VERSION "HNNBNNNYNNNNNNNNNNNNNNNNNNNNNNNNNNNNNNNNNN/4/%%%/4/'%**4NNN///"

NS_ :

BS_:

BU_: BAP_Tester BedienDisp_vo BedienSG_hi CGS DDA Gateway Gateway_PAG GurtMikrofon OTA_FC ZR_High ZR_LIMU ZR_MIB_TOP_ab_Gen3 ZR_Standard

BO_ 982 Licht_hinten_01: 8 Gateway
 SG_ BCM2_Bremsl_durch_ECD : 5|1@1+ (1.0,0.0) [0.0|1] ""  ZR_High
 SG_ LH_Aussenlicht_def : 7|1@1+ (1.0,0.0) [0.0|1] ""  ZR_High
 SG_ LH_Standlicht_H_aktiv : 8|1@1+ (1.0,0.0) [0.0|1] ""  ZR_High
 SG_ LH_Parklicht_HL_aktiv : 9|1@1+ (1.0,0.0) [0.0|1] ""  ZR_High
 SG_ LH_Parklicht_HR_aktiv : 10|1@1+ (1.0,0.0) [0.0|1] ""  ZR_High
 SG_ LH_Bremslicht_H_aktiv : 11|1@1+ (1.0,0.0) [0.0|1] ""  ZR_High
 SG_ LH_Nebelschluss_aktiv : 12|1@1+ (1.0,0.0) [0.0|1] ""  ZR_High
 SG_ LH_Rueckfahrlicht_aktiv : 13|1@1+ (1.0,0.0) [0.0|1] ""  ZR_High
 SG_ LH_Blinker_HL_akt : 14|1@1+ (1.0,0.0) [0.0|1] ""  ZR_High
 SG_ LH_Blinker_HR_akt : 15|1@1+ (1.0,0.0) [0.0|1] ""  ZR_High
 SG_ LH_Blinker_li_def : 16|1@1+ (1.0,0.0) [0.0|1] ""  ZR_High
 SG_ LH_Bremsl_li_def : 17|1@1+ (1.0,0.0) [0.0|1] ""  ZR_High
 SG_ LH_Schlusslicht_li_def : 18|1@1+ (1.0,0.0) [0.0|1] ""  ZR_High
 SG_ LH_Rueckf_li_def : 19|1@1+ (1.0,0.0) [0.0|1] ""  ZR_High
 SG_ LH_Nebel_li_def : 20|1@1+ (1.0,0.0) [0.0|1] ""  ZR_High
 SG_ LH_Schluss_Brems_Nebel_li_def : 21|1@1+ (1.0,0.0) [0.0|1] ""  ZR_High
 SG_ LH_Schluss_Brems_Nebel_re_def : 22|1@1+ (1.0,0.0) [0.0|1] ""  ZR_High
 SG_ LH_Zusatzschlussl_def : 23|1@1+ (1.0,0.0) [0.0|1] ""  Vector__XXX
 SG_ LH_Schluss_Brems_li_def : 24|1@1+ (1.0,0.0) [0.0|1] ""  ZR_High
 SG_ LH_Schluss_Nebel_li_def : 25|1@1+ (1.0,0.0) [0.0|1] ""  ZR_High
 SG_ LH_SL_BRL_BLK_li_def : 26|1@1+ (1.0,0.0) [0.0|1] ""  ZR_High
 SG_ LH_Brems_Blk_li_def : 27|1@1+ (1.0,0.0) [0.0|1] ""  Vector__XXX
 SG_ LH_Diag_Status_re_def : 28|1@1+ (1.0,0.0) [0.0|1] ""  ZR_High
 SG_ LH_Diag_Status_li_def : 29|1@1+ (1.0,0.0) [0.0|1] ""  ZR_High
 SG_ LH_Diag_LED_li_def : 30|1@1+ (1.0,0.0) [0.0|1] ""  ZR_High
 SG_ LH_Diag_LED_re_def : 31|1@1+ (1.0,0.0) [0.0|1] ""  ZR_High
 SG_ LH_Blinker_re_def : 32|1@1+ (1.0,0.0) [0.0|1] ""  ZR_High
 SG_ LH_Bremsl_re_def : 33|1@1+ (1.0,0.0) [0.0|1] ""  ZR_High
 SG_ LH_Schlusslicht_re_def : 34|1@1+ (1.0,0.0) [0.0|1] ""  ZR_High
 SG_ LH_Rueckf_re_def : 35|1@1+ (1.0,0.0) [0.0|1] ""  ZR_High
 SG_ LH_Nebel_re_def : 36|1@1+ (1.0,0.0) [0.0|1] ""  ZR_High
 SG_ LH_Schluss_Brems_mi_def : 37|1@1+ (1.0,0.0) [0.0|1] ""  Vector__XXX
 SG_ LH_Schluss_Brems_re_def : 40|1@1+ (1.0,0.0) [0.0|1] ""  ZR_High
 SG_ LH_Schluss_Nebel_re_def : 41|1@1+ (1.0,0.0) [0.0|1] ""  ZR_High
 SG_ LH_SL_BRL_BLK_re_def : 42|1@1+ (1.0,0.0) [0.0|1] ""  ZR_High
 SG_ LH_Brems_Blk_re_def : 43|1@1+ (1.0,0.0) [0.0|1] ""  ZR_High
 SG_ LH_Kennzl_def : 48|1@1+ (1.0,0.0) [0.0|1] ""  ZR_High
 SG_ LH_3_Bremsl_def : 49|1@1+ (1.0,0.0) [0.0|1] ""  ZR_High
 SG_ LH_Nebel_mi_def : 50|1@1+ (1.0,0.0) [0.0|1] ""  ZR_High
 SG_ LH_Rueckf_mi_def : 51|1@1+ (1.0,0.0) [0.0|1] ""  ZR_High
 SG_ LH_Schlusslicht_mi_def : 52|1@1+ (1.0,0.0) [0.0|1] ""  Vector__XXX
 SG_ LH_Bremsl_mi_def : 53|1@1+ (1.0,0.0) [0.0|1] ""  Vector__XXX
 SG_ LH_Bremsl_li_ges_def : 54|1@1+ (1.0,0.0) [0.0|1] ""  ZR_High
 SG_ LH_Bremsl_re_ges_def : 55|1@1+ (1.0,0.0) [0.0|1] ""  ZR_High

BO_ 1624 Licht_vorne_01: 8 Gateway
 SG_ Licht_Vorne_01_CRC : 0|8@1+ (1,0) [0|255] ""  Vector__XXX
 SG_ Licht_Vorne_01_BZ : 8|4@1+ (1,0) [0|15] ""  Vector__XXX
 SG_ LV_Standlicht_Anzeige : 12|1@1+ (1.0,0.0) [0.0|1] ""  BedienSG_hi,ZR_High
 SG_ LV_Abblendlicht_Anzeige : 13|1@1+ (1.0,0.0) [0.0|1] ""  OTA_FC,ZR_High
 SG_ LV_Fernlicht_Anzeige : 14|1@1+ (1.0,0.0) [0.0|1] ""  ZR_High
 SG_ LV_Nebellicht_Anzeige : 15|1@1+ (1.0,0.0) [0.0|1] ""  ZR_High
 SG_ LV_Nebelschlusslicht_Anzeige : 16|1@1+ (1.0,0.0) [0.0|1] ""  ZR_High
 SG_ LV_Tagfahrlicht_Anzeige : 17|1@1+ (1.0,0.0) [0.0|1] ""  BedienSG_hi,ZR_High
 SG_ LV_AFL_aktiv_Anzeige : 18|1@1+ (1.0,0.0) [0.0|1] ""  BedienSG_hi,ZR_High
 SG_ LV_AFL_defekt : 19|1@1+ (1.0,0.0) [0.0|1] ""  ZR_High
 SG_ LV_Blinker_li_def : 20|1@1+ (1.0,0.0) [0.0|1] ""  ZR_High
 SG_ LV_Standlicht_li_def : 21|1@1+ (1.0,0.0) [0.0|1] ""  ZR_High
 SG_ LV_Abblendlicht_li_def : 22|1@1+ (1.0,0.0) [0.0|1] ""  ZR_High
 SG_ LV_Fernlicht_li_def : 23|1@1+ (1.0,0.0) [0.0|1] ""  ZR_High
 SG_ LV_Nebellicht_li_def : 24|1@1+ (1.0,0.0) [0.0|1] ""  ZR_High
 SG_ LV_Blk_li_Seite_def : 25|1@1+ (1.0,0.0) [0.0|1] ""  ZR_High
 SG_ LV_Tagfahrlicht_li_def : 26|1@1+ (1.0,0.0) [0.0|1] ""  ZR_High
 SG_ LV_FLA_aktiv_Anzeige : 27|1@1+ (1.0,0.0) [0.0|1] ""  ZR_High
 SG_ LV_FLA_defekt : 28|1@1+ (1.0,0.0) [0.0|1] ""  ZR_High
 SG_ LV_FLA_Sensor_blockiert : 29|1@1+ (1.0,0.0) [0.0|1] ""  ZR_High
 SG_ LV_Blinker_re_def : 30|1@1+ (1.0,0.0) [0.0|1] ""  ZR_High
 SG_ LV_Standlicht_re_def : 31|1@1+ (1.0,0.0) [0.0|1] ""  ZR_High
 SG_ LV_Abblendlicht_re_def : 32|1@1+ (1.0,0.0) [0.0|1] ""  ZR_High
 SG_ LV_Fernlicht_re_def : 33|1@1+ (1.0,0.0) [0.0|1] ""  ZR_High
 SG_ LV_Nebellicht_re_def : 34|1@1+ (1.0,0.0) [0.0|1] ""  ZR_High
 SG_ LV_Blk_re_Seite_def : 35|1@1+ (1.0,0.0) [0.0|1] ""  ZR_High
 SG_ LV_Tagfahrlicht_re_def : 36|1@1+ (1.0,0.0) [0.0|1] ""  ZR_High
 SG_ LV_Aussenlicht_def : 37|1@1+ (1.0,0.0) [0.0|1] ""  ZR_High
 SG_ LV_Abblendlicht_TFL_li_def : 38|1@1+ (1.0,0.0) [0.0|1] ""  ZR_High
 SG_ LV_Nebellicht_TFL_li_def : 39|1@1+ (1.0,0.0) [0.0|1] ""  ZR_High
 SG_ LV_Standlicht_TFL_li_def : 40|1@1+ (1.0,0.0) [0.0|1] ""  ZR_High
 SG_ LV_Abblend_Fernlicht_li_def : 41|1@1+ (1.0,0.0) [0.0|1] ""  ZR_High
 SG_ LV_Abblendlicht_TFL_re_def : 42|1@1+ (1.0,0.0) [0.0|1] ""  ZR_High
 SG_ LV_Nebellicht_TFL_re_def : 43|1@1+ (1.0,0.0) [0.0|1] ""  ZR_High
 SG_ LV_Standlicht_TFL_re_def : 44|1@1+ (1.0,0.0) [0.0|1] ""  ZR_High
 SG_ LV_Abblend_Fernlicht_re_def : 45|1@1+ (1.0,0.0) [0.0|1] ""  ZR_High
 SG_ LV_Abbiegelicht_li_def : 46|1@1+ (1.0,0.0) [0.0|1] ""  Vector__XXX
 SG_ LV_Abbiegelicht_re_def : 47|1@1+ (1.0,0.0) [0.0|1] ""  Vector__XXX
 SG_ BCM1_Linksverkehr : 48|1@1+ (1.0,0.0) [0.0|1] ""  ZR_High
 SG_ BCM1_Licht_Dunkelheit_aktiv : 49|1@1+ (1.0,0.0) [0.0|1] ""  ZR_High
 SG_ LV_LED_Scheinwerfer_li_def : 50|1@1+ (1.0,0.0) [0.0|1] ""  Vector__XXX
 SG_ LV_LED_Scheinwerfer_re_def : 51|1@1+ (1.0,0.0) [0.0|1] ""  Vector__XXX
 SG_ LV_Blinker_VL_aktiv : 52|1@1+ (1.0,0.0) [0.0|1] ""  OTA_FC,ZR_High
 SG_ LV_Blinker_VR_aktiv : 53|1@1+ (1.0,0.0) [0.0|1] ""  OTA_FC,ZR_High
 SG_ LV_MXB_Status_Anzeige : 54|2@1+ (1.0,0.0) [0.0|3] ""  Vector__XXX

BO_ 1321 Lift_01: 8 Gateway
 SG_ Lift_Charisma_FahrPr : 15|3@1+ (1.0,0.0) [0.0|7] ""  Vector__XXX
 SG_ Lift_Charisma_Status : 18|2@1+ (1.0,0.0) [0.0|3] ""  Vector__XXX
 SG_ Lift_Charisma_Umschaltung : 20|2@1+ (1.0,0.0) [0.0|3] ""  Vector__XXX
 SG_ Lift_Anforderung_EFP : 22|2@1+ (1.0,0.0) [0.0|3] ""  Vector__XXX
 SG_ Lift_ESP_Zuschaltung : 24|1@1+ (1.0,0.0) [0.0|1] ""  Vector__XXX
 SG_ Lift_Meldung_12 : 40|1@1+ (1.0,0.0) [0.0|1] ""  Vector__XXX
 SG_ Lift_Meldung_13 : 41|1@1+ (1.0,0.0) [0.0|1] ""  Vector__XXX
 SG_ Lift_Meldung_14 : 42|1@1+ (1.0,0.0) [0.0|1] ""  Vector__XXX
 SG_ Lift_LED : 43|2@1+ (1.0,0.0) [0.0|3] ""  BedienDisp_vo
 SG_ Lift_Position : 45|3@1+ (1.0,0.0) [0.0|7] ""  Vector__XXX
 SG_ Lift_Meldung_01 : 48|1@1+ (1.0,0.0) [0.0|1] ""  Vector__XXX
 SG_ Lift_Meldung_02 : 49|1@1+ (1.0,0.0) [0.0|1] ""  Vector__XXX
 SG_ Lift_Meldung_03 : 50|1@1+ (1.0,0.0) [0.0|1] ""  Vector__XXX
 SG_ Lift_Meldung_04 : 51|1@1+ (1.0,0.0) [0.0|1] ""  Vector__XXX
 SG_ Lift_Meldung_05 : 52|1@1+ (1.0,0.0) [0.0|1] ""  Vector__XXX
 SG_ Lift_Meldung_06 : 53|1@1+ (1.0,0.0) [0.0|1] ""  Vector__XXX
 SG_ Lift_Meldung_07 : 54|1@1+ (1.0,0.0) [0.0|1] ""  Vector__XXX
 SG_ Lift_Meldung_08 : 55|1@1+ (1.0,0.0) [0.0|1] ""  Vector__XXX
 SG_ Lift_Meldung_09 : 56|1@1+ (1.0,0.0) [0.0|1] ""  Vector__XXX
 SG_ Lift_Meldung_10 : 57|1@1+ (1.0,0.0) [0.0|1] ""  Vector__XXX
 SG_ Lift_Meldung_11 : 58|1@1+ (1.0,0.0) [0.0|1] ""  Vector__XXX
 SG_ Lift_SpannungsAnf : 59|2@1+ (1.0,0.0) [0.0|3] ""  Vector__XXX
 SG_ Lift_StartStopp_Info : 61|2@1+ (1.0,0.0) [0.0|3] ""  Vector__XXX

BO_ 822 LR_HZG_01: 2 Gateway
 SG_ LR_HZG_Temp_Sensor : 0|8@1+ (1,-50) [-50|104] "Unit_DegreCelsi"  ZR_High
 SG_ LR_HZG_Taster_on_off : 8|1@1+ (1.0,0.0) [0.0|1] ""  ZR_High

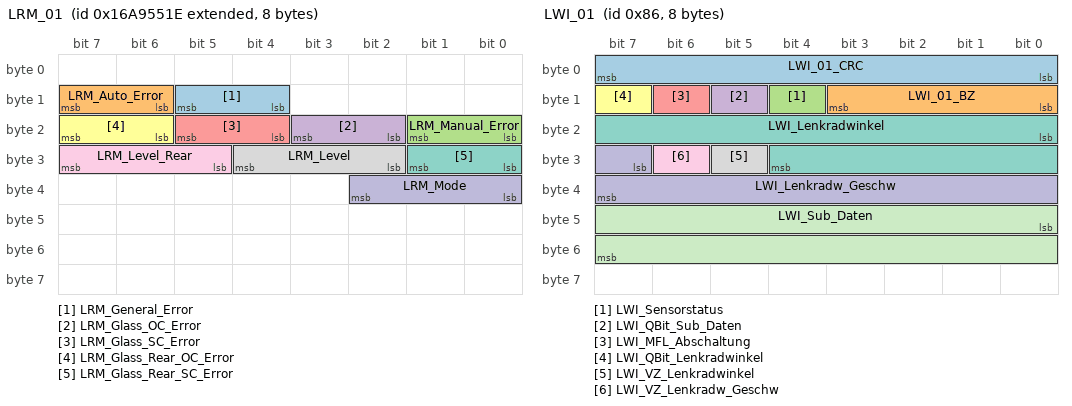
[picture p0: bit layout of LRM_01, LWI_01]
BO_ 2527679774 LRM_01: 8 Gateway
 SG_ LRM_General_Error : 12|2@1+ (1.0,0.0) [0.0|3] ""  ZR_LIMU
 SG_ LRM_Auto_Error : 14|2@1+ (1.0,0.0) [0.0|3] ""  ZR_LIMU
 SG_ LRM_Manual_Error : 16|2@1+ (1.0,0.0) [0.0|3] ""  ZR_LIMU
 SG_ LRM_Glass_OC_Error : 18|2@1+ (1.0,0.0) [0.0|3] ""  ZR_LIMU
 SG_ LRM_Glass_SC_Error : 20|2@1+ (1.0,0.0) [0.0|3] ""  ZR_LIMU
 SG_ LRM_Glass_Rear_OC_Error : 22|2@1+ (1.0,0.0) [0.0|3] ""  ZR_LIMU
 SG_ LRM_Glass_Rear_SC_Error : 24|2@1+ (1.0,0.0) [0.0|3] ""  ZR_LIMU
 SG_ LRM_Level : 26|3@1+ (1.0,0.0) [0.0|7] ""  ZR_LIMU
 SG_ LRM_Level_Rear : 29|3@1+ (1.0,0.0) [0.0|7] ""  ZR_LIMU
 SG_ LRM_Mode : 32|3@1+ (1.0,0.0) [0.0|7] ""  ZR_LIMU

BO_ 134 LWI_01: 8 Gateway
 SG_ LWI_01_CRC : 0|8@1+ (1,0) [0|255] ""  Vector__XXX
 SG_ LWI_01_BZ : 8|4@1+ (1,0) [0|15] ""  Vector__XXX
 SG_ LWI_Sensorstatus : 12|1@1+ (1.0,0.0) [0.0|1] ""  ZR_High,ZR_LIMU,ZR_MIB_TOP_ab_Gen3,ZR_Standard
 SG_ LWI_QBit_Sub_Daten : 13|1@1+ (1.0,0.0) [0.0|1] ""  ZR_High
 SG_ LWI_MFL_Abschaltung : 14|1@1+ (1.0,0.0) [0.0|1] ""  ZR_High
 SG_ LWI_QBit_Lenkradwinkel : 15|1@1+ (1.0,0.0) [0.0|1] ""  ZR_High,ZR_LIMU,ZR_MIB_TOP_ab_Gen3,ZR_Standard
 SG_ LWI_Lenkradwinkel : 16|13@1+ (0.1,0) [0.0|800.0] "Unit_DegreOfArc"  OTA_FC,ZR_High,ZR_LIMU,ZR_MIB_TOP_ab_Gen3,ZR_Standard
 SG_ LWI_VZ_Lenkradwinkel : 29|1@1+ (1.0,0.0) [0.0|1] ""  OTA_FC,ZR_High,ZR_LIMU,ZR_MIB_TOP_ab_Gen3,ZR_Standard
 SG_ LWI_VZ_Lenkradw_Geschw : 30|1@1+ (1.0,0.0) [0.0|1] ""  ZR_High
 SG_ LWI_Lenkradw_Geschw : 31|9@1+ (5,0) [0|2500] "Unit_DegreOfArcPerSecon"  OTA_FC,ZR_High
 SG_ LWI_Sub_Daten : 40|16@1+ (1,0) [0|65535] ""  Vector__XXX

BO_ 917 LWR_AFS_01: 8 Gateway
 SG_ AFS_Abbiegelicht_li_Anf : 0|1@1+ (1.0,0.0) [0.0|1] ""  ZR_High
 SG_ AFS_Abbiegelicht_re_Anf : 1|1@1+ (1.0,0.0) [0.0|1] ""  ZR_High
 SG_ AFS_Abbiegelicht_Dimm_Anf : 2|1@1+ (1.0,0.0) [0.0|1] ""  ZR_High
 SG_ AFS_Verfuegbarkeit_GLW : 3|1@1+ (1.0,0.0) [0.0|1] ""  ZR_High
 SG_ AFS_Status_adaptive_LV : 4|1@1+ (1.0,0.0) [0.0|1] ""  ZR_High
 SG_ AFS_Fernlicht_li_defekt : 5|1@1+ (1.0,0.0) [0.0|1] ""  ZR_High
 SG_ AFS_Fernlicht_re_defekt : 6|1@1+ (1.0,0.0) [0.0|1] ""  ZR_High
 SG_ AFS_Fernlicht_Status : 7|1@1+ (1.0,0.0) [0.0|1] ""  ZR_High
 SG_ LWR_AFS_01_BZ : 8|4@1+ (1,0) [0|15] ""  Vector__XXX
 SG_ AFS_Lampe : 12|1@1+ (1.0,0.0) [0.0|1] ""  ZR_High
 SG_ LWR_Lampe : 13|1@1+ (1.0,0.0) [0.0|1] ""  ZR_High
 SG_ AFS_Fehlertext : 14|1@1+ (1.0,0.0) [0.0|1] ""  ZR_High
 SG_ AFS_LED_Blinkmode : 15|1@1+ (1.0,0.0) [0.0|1] ""  Vector__XXX
 SG_ LWR_Touristenmodus_aktiv : 16|1@1+ (1.0,0.0) [0.0|1] ""  ZR_High
 SG_ AFS_Charisma_FahrPr : 17|4@1+ (1.0,0.0) [0.0|15] ""  Vector__XXX
 SG_ AFS_Charisma_Status : 21|2@1+ (1.0,0.0) [0.0|3] ""  Vector__XXX
 SG_ LWR_Sicherheitsposition_re : 23|1@1+ (1.0,0.0) [0.0|1] ""  ZR_High
 SG_ AFS_Allwetterlicht : 24|1@1+ (1.0,0.0) [0.0|1] ""  ZR_High
 SG_ LWR_Touristenmodus_verbaut : 25|1@1+ (1.0,0.0) [0.0|1] ""  ZR_High
 SG_ AFS_adaptive_LV_verbaut : 26|1@1+ (1.0,0.0) [0.0|1] ""  ZR_High
 SG_ LWR_Reisemodus_Texte : 27|2@1+ (1.0,0.0) [0.0|3] ""  ZR_High
 SG_ GLW_Sensor_blockiert : 29|1@1+ (1.0,0.0) [0.0|1] ""  ZR_High
 SG_ AFS_Charisma_Umschaltung : 30|2@1+ (1.0,0.0) [0.0|3] ""  Vector__XXX
 SG_ LWR_Pos_Schrittmotor : 32|8@1+ (0.4,0) [0.0|100.0] "Unit_PerCent"  Vector__XXX
 SG_ LWR_Hoehenwert_VL : 40|8@1+ (1,-127) [-127|126] ""  ZR_High
 SG_ LWR_Hoehenwert_HL : 48|8@1+ (1,-127) [-127|126] ""  ZR_High
 SG_ AFS_Ersatzlicht_Links : 56|1@1+ (1.0,0.0) [0.0|1] ""  ZR_High
 SG_ AFS_Ersatzlicht_Rechts : 57|1@1+ (1.0,0.0) [0.0|1] ""  ZR_High
 SG_ LWR_AFS_Grundeinstellung : 58|1@1+ (1.0,0.0) [0.0|1] ""  ZR_High
 SG_ LWR_AFS_Parametrisierung : 59|1@1+ (1.0,0.0) [0.0|1] ""  ZR_High
 SG_ LWR_Initialisierungslauf : 60|1@1+ (1.0,0.0) [0.0|1] ""  ZR_High
 SG_ LWR_Sicherheitsposition_li : 61|1@1+ (1.0,0.0) [0.0|1] ""  ZR_High
 SG_ LWR_Modus : 62|1@1+ (1.0,0.0) [0.0|1] ""  ZR_High

BO_ 1153 MainUnit_01: 8 ZR_High
 SG_ ZR_LoGeWa_Event_Kombiwarnung : 0|4@1+ (1.0,0.0) [0.0|15] ""  Gateway,Gateway_PAG
 SG_ Nav_FoD_Status : 4|3@1+ (1.0,0.0) [0.0|7] ""  Gateway,Gateway_PAG
 SG_ MIB_Tongenerator_PH_verfuegbar : 9|3@1+ (1.0,0.0) [0.0|7] ""  Gateway,Gateway_PAG
 SG_ MMI_Counter_Bedienevent : 12|4@1+ (1.0,0.0) [0.0|15] ""  Gateway,Gateway_PAG
 SG_ DSSS_Warning : 16|5@1+ (1.0,0.0) [0.0|31] ""  Gateway,Gateway_PAG
 SG_ ZR_Kindersicherung_RSE : 21|1@1+ (1.0,0.0) [0.0|1] ""  Gateway,Gateway_PAG
 SG_ ZR_RSE_aktivieren : 22|1@1+ (1.0,0.0) [0.0|1] ""  Gateway,Gateway_PAG
 SG_ MMI_SDS_aktiv : 23|1@1+ (1.0,0.0) [0.0|1] ""  Gateway,Gateway_PAG
 SG_ MU_SecondDisplay : 24|3@1+ (1.0,0.0) [0.0|7] ""  Gateway,Gateway_PAG
 SG_ MMI_Telefon_aktiv : 27|1@1+ (1.0,0.0) [0.0|1] ""  Gateway,Gateway_PAG
 SG_ MMI_Gurt_Mic_ref : 28|1@1+ (1.0,0.0) [0.0|1] ""  Gateway,Gateway_PAG,GurtMikrofon
 SG_ ZR_Sta_Inszenierung : 29|2@1+ (1.0,0.0) [0.0|3] ""  Gateway,Gateway_PAG
 SG_ MMI_Gauges_active : 31|1@1+ (1.0,0.0) [0.0|1] ""  BedienDisp_vo,Gateway,Gateway_PAG
 SG_ MU_Update_Time : 32|8@1+ (0.1,0) [0.0|25.5] "Unit_Hours"  Gateway,Gateway_PAG
 SG_ ZR_MXB_Manoever_Ansage : 42|2@1+ (1.0,0.0) [0.0|3] ""  Gateway,Gateway_PAG
 SG_ ZR_LAPP_Sondermodus_Status : 44|2@1+ (1.0,0.0) [0.0|3] ""  DDA,Gateway,Gateway_PAG
 SG_ MMI_StartStopp_Info : 46|2@1+ (1.0,0.0) [0.0|3] ""  Gateway,Gateway_PAG
 SG_ ZR_Parken_Sondermodus : 48|4@1+ (1.0,0.0) [0.0|15] ""  DDA,Gateway,Gateway_PAG
 SG_ ZR_Rundenbewertung : 52|4@1+ (1.0,0.0) [0.0|15] ""  Gateway,Gateway_PAG
 SG_ ZR_Rundenfortschritt : 56|8@1+ (0.5,0) [0.0|100.0] "Unit_PerCent"  Gateway,Gateway_PAG

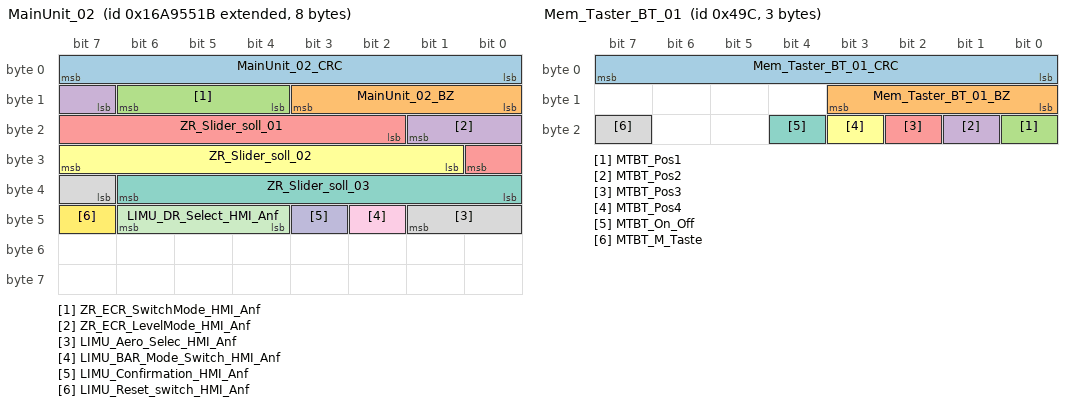
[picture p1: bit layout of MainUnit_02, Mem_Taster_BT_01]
BO_ 2527679771 MainUnit_02: 8 ZR_LIMU
 SG_ MainUnit_02_CRC : 0|8@1+ (1,0) [0|255] ""  Gateway,Gateway_PAG
 SG_ MainUnit_02_BZ : 8|4@1+ (1,0) [0|15] ""  Gateway,Gateway_PAG
 SG_ ZR_ECR_SwitchMode_HMI_Anf : 12|3@1+ (1.0,0.0) [0.0|7] ""  Gateway,Gateway_PAG
 SG_ ZR_ECR_LevelMode_HMI_Anf : 15|3@1+ (1.0,0.0) [0.0|7] ""  Gateway,Gateway_PAG
 SG_ ZR_Slider_soll_01 : 18|7@1+ (0.01,0) [0.00|1.26] "Unit_None"  Gateway,Gateway_PAG
 SG_ ZR_Slider_soll_02 : 25|7@1+ (0.01,0) [0.00|1.26] "Unit_None"  Gateway,Gateway_PAG
 SG_ ZR_Slider_soll_03 : 32|7@1+ (0.01,0) [0.00|1.26] "Unit_None"  Gateway,Gateway_PAG
 SG_ LIMU_Aero_Selec_HMI_Anf : 39|3@1+ (1.0,0.0) [0.0|7] ""  Gateway,Gateway_PAG
 SG_ LIMU_BAR_Mode_Switch_HMI_Anf : 42|1@1+ (1.0,0.0) [0.0|1] ""  Gateway,Gateway_PAG
 SG_ LIMU_Confirmation_HMI_Anf : 43|1@1+ (1.0,0.0) [0.0|1] ""  Gateway,Gateway_PAG
 SG_ LIMU_DR_Select_HMI_Anf : 44|3@1+ (1.0,0.0) [0.0|7] ""  Gateway,Gateway_PAG
 SG_ LIMU_Reset_switch_HMI_Anf : 47|1@1+ (1.0,0.0) [0.0|1] ""  Gateway,Gateway_PAG

BO_ 1639 Mem_BFS_01: 8 Gateway
 SG_ BFS_Fond_Bed_Ack : 12|1@1+ (1.0,0.0) [0.0|1] ""  ZR_High
 SG_ BFS_Lehne_nicht_verriegelt : 13|1@1+ (1.0,0.0) [0.0|1] ""  Vector__XXX
 SG_ BFS_Klapptisch_offen : 14|1@1+ (1.0,0.0) [0.0|1] ""  ZR_High
 SG_ BFS_Gurtbringer_Sperre : 15|1@1+ (1.0,0.0) [0.0|1] ""  ZR_High
 SG_ BFS_Sitzsym_Fahrt_aktiv : 16|1@1+ (1.0,0.0) [0.0|1] ""  ZR_High
 SG_ BFS_Sitzfahrt_aktiv : 17|1@1+ (1.0,0.0) [0.0|1] ""  ZR_High
 SG_ BFS_SLV_aktiv : 18|1@1+ (1.0,0.0) [0.0|1] ""  ZR_High
 SG_ BFS_SHV_aktiv : 19|1@1+ (1.0,0.0) [0.0|1] ""  ZR_High
 SG_ BFS_LNV_aktiv : 20|1@1+ (1.0,0.0) [0.0|1] ""  ZR_High
 SG_ BFS_SNV_aktiv : 21|1@1+ (1.0,0.0) [0.0|1] ""  ZR_High
 SG_ BFS_KSV_aktiv : 22|1@1+ (1.0,0.0) [0.0|1] ""  ZR_High
 SG_ BFS_LKV_aktiv : 23|1@1+ (1.0,0.0) [0.0|1] ""  ZR_High
 SG_ BFS_STV_aktiv : 24|1@1+ (1.0,0.0) [0.0|1] ""  ZR_High
 SG_ BFS_LHV_aktiv : 25|1@1+ (1.0,0.0) [0.0|1] ""  ZR_High
 SG_ BFS_LWV_aktiv : 26|1@1+ (1.0,0.0) [0.0|1] ""  ZR_High
 SG_ BFS_GHV_aktiv : 27|1@1+ (1.0,0.0) [0.0|1] ""  ZR_High
 SG_ BFS_KSS_Fahrt_aktiv : 28|1@1+ (1.0,0.0) [0.0|1] ""  ZR_High
 SG_ BFS_MMB_lokal_Stop : 29|1@1+ (1.0,0.0) [0.0|1] ""  ZR_High
 SG_ BFS_Ruhestellung_Status : 30|1@1+ (1.0,0.0) [0.0|1] ""  ZR_High
 SG_ BFS_Seat_Locked : 31|1@1+ (1.0,0.0) [0.0|1] ""  ZR_High
 SG_ BFS_MMB_storage : 32|4@1+ (1.0,0.0) [0.0|15] ""  ZR_High
 SG_ BFS_MMB_tipp : 36|1@1+ (1.0,0.0) [0.0|1] ""  ZR_High
 SG_ BFS_MMB_tast : 37|1@1+ (1.0,0.0) [0.0|1] ""  ZR_High
 SG_ BFS_MMB_store_LED_on : 38|1@1+ (1.0,0.0) [0.0|1] ""  ZR_High
 SG_ BFS_MMB_storage_beep : 39|1@1+ (1.0,0.0) [0.0|1] ""  ZR_High
 SG_ BFS_MMB_store : 40|1@1+ (1.0,0.0) [0.0|1] ""  ZR_High
 SG_ BFS_MMB_glob_stop : 41|1@1+ (1.0,0.0) [0.0|1] ""  ZR_High
 SG_ BFS_FSV_ausgeklappt : 42|1@1+ (1.0,0.0) [0.0|1] ""  ZR_High
 SG_ BFS_NFA_einfahren : 43|1@1+ (1.0,0.0) [0.0|1] ""  Vector__XXX
 SG_ BFS_Kollisionsbereich_Windschott : 44|1@1+ (1.0,0.0) [0.0|1] ""  Vector__XXX
 SG_ BFS_Kollisionsgefahr_Windschott : 45|1@1+ (1.0,0.0) [0.0|1] ""  Vector__XXX

BO_ 957 Mem_BFS_Fond_01: 8 Gateway
 SG_ Mem_BFSFo_Lordose_hoch : 12|1@1+ (1.0,0.0) [0.0|1] ""  ZR_High
 SG_ Mem_BFSFo_Lordose_runter : 13|1@1+ (1.0,0.0) [0.0|1] ""  ZR_High
 SG_ Mem_BFSFo_Lordose_vor : 14|1@1+ (1.0,0.0) [0.0|1] ""  ZR_High
 SG_ Mem_BFSFo_Lordose_zurueck : 15|1@1+ (1.0,0.0) [0.0|1] ""  ZR_High
 SG_ Mem_BFSFo_Massage_Geschw : 16|3@1+ (1.0,0.0) [0.0|7] ""  ZR_High
 SG_ Mem_BFSFo_Massage_Intens : 19|3@1+ (1.0,0.0) [0.0|7] ""  ZR_High
 SG_ Mem_BFSFo_MMB_storage : 22|2@1+ (1.0,0.0) [0.0|3] ""  ZR_High
 SG_ Mem_BFSFo_Massage_Prg : 24|3@1+ (1.0,0.0) [0.0|7] ""  ZR_High
 SG_ Mem_BFSFo_MMB_tast : 27|1@1+ (1.0,0.0) [0.0|1] ""  ZR_High
 SG_ Mem_BFSFo_MMB_tipp : 28|1@1+ (1.0,0.0) [0.0|1] ""  ZR_High
 SG_ Mem_BFSFo_MMB_glob_Stop : 29|1@1+ (1.0,0.0) [0.0|1] ""  ZR_High
 SG_ Mem_BFSFo_Sitztiefe_vor : 30|1@1+ (1.0,0.0) [0.0|1] ""  ZR_High
 SG_ Mem_BFSFo_Sitztiefe_zur : 31|1@1+ (1.0,0.0) [0.0|1] ""  ZR_High
 SG_ Mem_BFSFo_MMB_store : 32|1@1+ (1.0,0.0) [0.0|1] ""  ZR_High
 SG_ Mem_BFSFo_MMB_storage_beep : 33|1@1+ (1.0,0.0) [0.0|1] ""  Vector__XXX
 SG_ Mem_BFSFo_MMB_store_LED_on : 34|1@1+ (1.0,0.0) [0.0|1] ""  ZR_High
 SG_ Mem_BFSFo_BeifaSitzverstellung : 35|1@1+ (1.0,0.0) [0.0|1] ""  ZR_High
 SG_ Mem_BFSFo_MMB_lokal_Stop : 36|1@1+ (1.0,0.0) [0.0|1] ""  ZR_High
 SG_ Mem_BFSFo_Sitzfahrt_aktiv : 37|1@1+ (1.0,0.0) [0.0|1] ""  ZR_High
 SG_ Mem_BFSFo_BFS_Freigabe : 38|1@1+ (1.0,0.0) [0.0|1] ""  ZR_High
 SG_ Mem_BFS_Spezialpos_loeschen : 39|1@1+ (1.0,0.0) [0.0|1] ""  ZR_High
 SG_ Mem_BFSFo_RSE_zurueck : 40|1@1+ (1.0,0.0) [0.0|1] ""  ZR_High
 SG_ Mem_BFSFo_RSE_vor : 41|1@1+ (1.0,0.0) [0.0|1] ""  ZR_High
 SG_ Mem_BFSFo_Business_anfahren : 42|1@1+ (1.0,0.0) [0.0|1] ""  ZR_High
 SG_ Mem_BFSFo_Relax_anfahren : 43|1@1+ (1.0,0.0) [0.0|1] ""  ZR_High
 SG_ BFS_Kopfstuetze_vor : 44|1@1+ (1.0,0.0) [0.0|1] ""  ZR_High
 SG_ BFS_Kopfstuetze_zurueck : 45|1@1+ (1.0,0.0) [0.0|1] ""  ZR_High
 SG_ Mem_BFSFo_NFA_aufgestellt : 46|1@1+ (1.0,0.0) [0.0|1] ""  Vector__XXX
 SG_ Fernsteuerung_BFS_LED : 47|1@1+ (1.0,0.0) [0.0|1] ""  Vector__XXX
 SG_ Mem_BFSFo_BFS_RSE_Freigabe : 48|1@1+ (1.0,0.0) [0.0|1] ""  ZR_High
 SG_ Mem_BFSFo_Fusstuetze_runter : 49|1@1+ (1.0,0.0) [0.0|1] ""  ZR_High
 SG_ Mem_BFSFo_Fusstuetze_hoch : 50|1@1+ (1.0,0.0) [0.0|1] ""  ZR_High
 SG_ Fernsteuerung_Massage_LED : 51|1@1+ (1.0,0.0) [0.0|1] ""  Vector__XXX

BO_ 1178 Mem_FS_01: 8 Gateway
 SG_ FS_Fond_Bed_enable : 12|1@1+ (1.0,0.0) [0.0|1] ""  ZR_High
 SG_ FS_Lehne_nicht_verriegelt : 13|1@1+ (1.0,0.0) [0.0|1] ""  ZR_High
 SG_ FS_Spezialposition_anfahren : 14|1@1+ (1.0,0.0) [0.0|1] ""  ZR_High
 SG_ FS_Gurtbringer_Sperre : 15|1@1+ (1.0,0.0) [0.0|1] ""  ZR_High
 SG_ FS_BFS_Sitzsym_Anfahrt : 16|1@1+ (1.0,0.0) [0.0|1] ""  ZR_High
 SG_ FS_Sitzfahrt_aktiv : 17|1@1+ (1.0,0.0) [0.0|1] ""  ZR_High
 SG_ FS_SLV_aktiv : 18|1@1+ (1.0,0.0) [0.0|1] ""  ZR_High
 SG_ FS_SHV_aktiv : 19|1@1+ (1.0,0.0) [0.0|1] ""  ZR_High
 SG_ FS_LNV_aktiv : 20|1@1+ (1.0,0.0) [0.0|1] ""  ZR_High
 SG_ FS_SNV_aktiv : 21|1@1+ (1.0,0.0) [0.0|1] ""  ZR_High
 SG_ FS_KSV_aktiv : 22|1@1+ (1.0,0.0) [0.0|1] ""  ZR_High
 SG_ FS_LKV_aktiv : 23|1@1+ (1.0,0.0) [0.0|1] ""  ZR_High
 SG_ FS_STV_aktiv : 24|1@1+ (1.0,0.0) [0.0|1] ""  ZR_High
 SG_ FS_LHV_aktiv : 25|1@1+ (1.0,0.0) [0.0|1] ""  ZR_High
 SG_ FS_LWV_aktiv : 26|1@1+ (1.0,0.0) [0.0|1] ""  ZR_High
 SG_ FS_GHV_aktiv : 27|1@1+ (1.0,0.0) [0.0|1] ""  ZR_High
 SG_ FS_BFS_KSS_Anfahrt : 28|1@1+ (1.0,0.0) [0.0|1] ""  ZR_High
 SG_ FS_MMB_lokal_Stop : 29|1@1+ (1.0,0.0) [0.0|1] ""  ZR_High
 SG_ FS_NFA_einfahren : 30|1@1+ (1.0,0.0) [0.0|1] ""  Vector__XXX
 SG_ FS_Kollisionsbereich_Windschott : 31|1@1+ (1.0,0.0) [0.0|1] ""  Vector__XXX
 SG_ FS_MMB_storage : 32|4@1+ (1.0,0.0) [0.0|15] ""  ZR_High
 SG_ FS_MMB_tipp : 36|1@1+ (1.0,0.0) [0.0|1] ""  ZR_High
 SG_ FS_MMB_tast : 37|1@1+ (1.0,0.0) [0.0|1] ""  ZR_High
 SG_ FS_MMB_store_LED_on : 38|1@1+ (1.0,0.0) [0.0|1] ""  ZR_High
 SG_ FS_MMB_storage_beep : 39|1@1+ (1.0,0.0) [0.0|1] ""  Vector__XXX
 SG_ FS_MMB_store : 40|1@1+ (1.0,0.0) [0.0|1] ""  ZR_High
 SG_ FS_MMB_glob_stop : 41|1@1+ (1.0,0.0) [0.0|1] ""  ZR_High
 SG_ FS_EE_Fond_FS_enable : 42|1@1+ (1.0,0.0) [0.0|1] ""  ZR_High
 SG_ FS_EE_Fond_BFS_enable : 43|1@1+ (1.0,0.0) [0.0|1] ""  ZR_High
 SG_ FS_BFS_Fond_Verst_enable : 44|1@1+ (1.0,0.0) [0.0|1] ""  ZR_High
 SG_ FS_EE_BFS_enable : 45|1@1+ (1.0,0.0) [0.0|1] ""  ZR_High
 SG_ FS_Kollisionsgefahr_Windschott : 46|1@1+ (1.0,0.0) [0.0|1] ""  Vector__XXX

BO_ 954 Mem_FS_02: 8 Gateway
 SG_ Mem_FS_Lordose_hoch : 12|1@1+ (1.0,0.0) [0.0|1] ""  ZR_High
 SG_ Mem_FS_Lordose_runter : 13|1@1+ (1.0,0.0) [0.0|1] ""  ZR_High
 SG_ Mem_FS_Lordose_vor : 14|1@1+ (1.0,0.0) [0.0|1] ""  ZR_High
 SG_ Mem_FS_Lordose_zurueck : 15|1@1+ (1.0,0.0) [0.0|1] ""  ZR_High
 SG_ Mem_FS_Massage_Geschw : 16|3@1+ (1.0,0.0) [0.0|7] ""  ZR_High
 SG_ Mem_FS_Massage_Intensitaet : 19|3@1+ (1.0,0.0) [0.0|7] ""  ZR_High
 SG_ Mem_FS_SWangenLehne_beluef : 22|1@1+ (1.0,0.0) [0.0|1] ""  ZR_High
 SG_ Mem_FS_SWangenLehne_entlue : 23|1@1+ (1.0,0.0) [0.0|1] ""  ZR_High
 SG_ Mem_FS_Massage_Programm : 24|3@1+ (1.0,0.0) [0.0|7] ""  Vector__XXX
 SG_ Mem_FS_SWangenSitz_beluef : 27|1@1+ (1.0,0.0) [0.0|1] ""  ZR_High
 SG_ Mem_FS_SWangenSitz_entlue : 28|1@1+ (1.0,0.0) [0.0|1] ""  ZR_High
 SG_ FS_BFS_aufraeumen : 29|1@1+ (1.0,0.0) [0.0|1] ""  ZR_High
 SG_ FS_BFSFo_aufraeumen : 30|1@1+ (1.0,0.0) [0.0|1] ""  ZR_High
 SG_ FS_FSFo_aufraeumen : 31|1@1+ (1.0,0.0) [0.0|1] ""  ZR_High
 SG_ FS_Remote_Multif_Taster_hoch : 32|1@1+ (1.0,0.0) [0.0|1] ""  ZR_High
 SG_ FS_Remote_Multif_Taster_tief : 33|1@1+ (1.0,0.0) [0.0|1] ""  ZR_High
 SG_ FS_Remote_Multif_Taster_vor : 34|1@1+ (1.0,0.0) [0.0|1] ""  ZR_High
 SG_ FS_Remote_Multif_Taster_zurueck : 35|1@1+ (1.0,0.0) [0.0|1] ""  ZR_High
 SG_ FS_Remote_Programmwippe_hoch : 36|1@1+ (1.0,0.0) [0.0|1] ""  ZR_High
 SG_ FS_Remote_Programmwippe_tief : 37|1@1+ (1.0,0.0) [0.0|1] ""  ZR_High
 SG_ FS_Remote_SHV_Taste_hoch : 38|1@1+ (1.0,0.0) [0.0|1] ""  ZR_High
 SG_ FS_Remote_SHV_Taste_tief : 39|1@1+ (1.0,0.0) [0.0|1] ""  ZR_High
 SG_ FS_Remote_SLV_Taste_vor : 40|1@1+ (1.0,0.0) [0.0|1] ""  ZR_High
 SG_ FS_Remote_SLV_Taste_zurueck : 41|1@1+ (1.0,0.0) [0.0|1] ""  ZR_High
 SG_ FS_Remote_SNV_Taste_hoch : 42|1@1+ (1.0,0.0) [0.0|1] ""  ZR_High
 SG_ FS_Remote_SNV_Taste_tief : 43|1@1+ (1.0,0.0) [0.0|1] ""  ZR_High
 SG_ FS_Remote_KSV_Taste_hoch : 44|1@1+ (1.0,0.0) [0.0|1] ""  ZR_High
 SG_ FS_Remote_KSV_Taste_tief : 45|1@1+ (1.0,0.0) [0.0|1] ""  ZR_High
 SG_ FS_Remote_LNV_Taste_vor : 46|1@1+ (1.0,0.0) [0.0|1] ""  ZR_High
 SG_ FS_Remote_LNV_Taste_zurueck : 47|1@1+ (1.0,0.0) [0.0|1] ""  ZR_High
 SG_ FS_Remote_Massage_Taste : 48|1@1+ (1.0,0.0) [0.0|1] ""  ZR_High
 SG_ FS_RemoteTarget : 49|2@1+ (1.0,0.0) [0.0|3] ""  ZR_High
 SG_ FS_Remote_KSV_Taste_vor : 51|1@1+ (1.0,0.0) [0.0|1] ""  ZR_High
 SG_ FS_Remote_KSV_Taste_zurueck : 52|1@1+ (1.0,0.0) [0.0|1] ""  ZR_High
 SG_ FS_Remote_STV_Taste_vor : 53|1@1+ (1.0,0.0) [0.0|1] ""  ZR_High
 SG_ FS_Remote_STV_Taste_zurueck : 54|1@1+ (1.0,0.0) [0.0|1] ""  ZR_High
 SG_ FS_Remote_SWV_Taste_eng : 55|1@1+ (1.0,0.0) [0.0|1] ""  ZR_High
 SG_ FS_Remote_SWV_Taste_breit : 56|1@1+ (1.0,0.0) [0.0|1] ""  ZR_High
 SG_ FS_Remote_LWV_Taste_eng : 57|1@1+ (1.0,0.0) [0.0|1] ""  ZR_High
 SG_ FS_Remote_LWV_Taste_breit : 58|1@1+ (1.0,0.0) [0.0|1] ""  ZR_High
 SG_ FS_Remote_LKV_Taste_vor : 59|1@1+ (1.0,0.0) [0.0|1] ""  ZR_High
 SG_ FS_Remote_LKV_Taste_zurueck : 60|1@1+ (1.0,0.0) [0.0|1] ""  ZR_High
 SG_ FS_MMB_Sys_Fahrt_aktiv : 61|1@1+ (1.0,0.0) [0.0|1] ""  ZR_High

BO_ 956 Mem_FS_Fond_01: 8 Gateway
 SG_ Mem_FSFo_Lordose_hoch : 12|1@1+ (1.0,0.0) [0.0|1] ""  ZR_High
 SG_ Mem_FSFo_Lordose_runter : 13|1@1+ (1.0,0.0) [0.0|1] ""  ZR_High
 SG_ Mem_FSFo_Lordose_vor : 14|1@1+ (1.0,0.0) [0.0|1] ""  ZR_High
 SG_ Mem_FSFo_Lordose_zurueck : 15|1@1+ (1.0,0.0) [0.0|1] ""  ZR_High
 SG_ Mem_FSFo_Massage_Geschw : 16|3@1+ (1.0,0.0) [0.0|7] ""  ZR_High
 SG_ Mem_FSFo_Massage_Intens : 19|3@1+ (1.0,0.0) [0.0|7] ""  ZR_High
 SG_ Mem_FSFo_MMB_storage : 22|2@1+ (1.0,0.0) [0.0|3] ""  ZR_High
 SG_ Mem_FSFo_Massage_Prg : 24|3@1+ (1.0,0.0) [0.0|7] ""  ZR_High
 SG_ Mem_FSFo_MMB_tast : 27|1@1+ (1.0,0.0) [0.0|1] ""  ZR_High
 SG_ Mem_FSFo_MMB_tipp : 28|1@1+ (1.0,0.0) [0.0|1] ""  ZR_High
 SG_ Mem_FSFo_MMB_glob_Stop : 29|1@1+ (1.0,0.0) [0.0|1] ""  ZR_High
 SG_ Mem_FSFo_Sitztiefe_vor : 30|1@1+ (1.0,0.0) [0.0|1] ""  ZR_High
 SG_ Mem_FSFo_Sitztiefe_zur : 31|1@1+ (1.0,0.0) [0.0|1] ""  ZR_High
 SG_ Mem_FSFo_MMB_store : 32|1@1+ (1.0,0.0) [0.0|1] ""  ZR_High
 SG_ Mem_FSFo_MMB_storage_beep : 33|1@1+ (1.0,0.0) [0.0|1] ""  ZR_High
 SG_ Mem_FSFo_MMB_store_LED_on : 34|1@1+ (1.0,0.0) [0.0|1] ""  ZR_High
 SG_ Mem_FSFo_MMB_lokal_Stop : 36|1@1+ (1.0,0.0) [0.0|1] ""  ZR_High
 SG_ Mem_FSFo_Sitzfahrt_aktiv : 37|1@1+ (1.0,0.0) [0.0|1] ""  ZR_High
 SG_ Mem_FSFo_Business_anfahren : 42|1@1+ (1.0,0.0) [0.0|1] ""  ZR_High
 SG_ Mem_FSFo_Relax_anfahren : 43|1@1+ (1.0,0.0) [0.0|1] ""  ZR_High

BO_ 1180 Mem_Taster_BT_01: 3 Gateway
 SG_ Mem_Taster_BT_01_CRC : 0|8@1+ (1,0) [0|255] ""  Vector__XXX
 SG_ Mem_Taster_BT_01_BZ : 8|4@1+ (1,0) [0|15] ""  Vector__XXX
 SG_ MTBT_Pos1 : 16|1@1+ (1.0,0.0) [0.0|1] ""  ZR_High
 SG_ MTBT_Pos2 : 17|1@1+ (1.0,0.0) [0.0|1] ""  ZR_High
 SG_ MTBT_Pos3 : 18|1@1+ (1.0,0.0) [0.0|1] ""  ZR_High
 SG_ MTBT_Pos4 : 19|1@1+ (1.0,0.0) [0.0|1] ""  ZR_High
 SG_ MTBT_On_Off : 20|1@1+ (1.0,0.0) [0.0|1] ""  ZR_High
 SG_ MTBT_M_Taste : 23|1@1+ (1.0,0.0) [0.0|1] ""  ZR_High

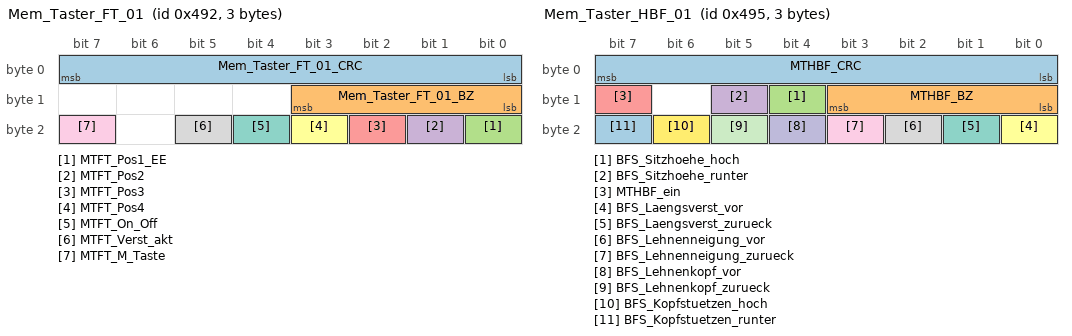
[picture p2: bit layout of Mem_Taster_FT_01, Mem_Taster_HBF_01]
BO_ 1170 Mem_Taster_FT_01: 3 Gateway
 SG_ Mem_Taster_FT_01_CRC : 0|8@1+ (1,0) [0|255] ""  Vector__XXX
 SG_ Mem_Taster_FT_01_BZ : 8|4@1+ (1,0) [0|15] ""  Vector__XXX
 SG_ MTFT_Pos1_EE : 16|1@1+ (1.0,0.0) [0.0|1] ""  ZR_High
 SG_ MTFT_Pos2 : 17|1@1+ (1.0,0.0) [0.0|1] ""  ZR_High
 SG_ MTFT_Pos3 : 18|1@1+ (1.0,0.0) [0.0|1] ""  ZR_High
 SG_ MTFT_Pos4 : 19|1@1+ (1.0,0.0) [0.0|1] ""  ZR_High
 SG_ MTFT_On_Off : 20|1@1+ (1.0,0.0) [0.0|1] ""  ZR_High
 SG_ MTFT_Verst_akt : 21|1@1+ (1.0,0.0) [0.0|1] ""  ZR_High
 SG_ MTFT_M_Taste : 23|1@1+ (1.0,0.0) [0.0|1] ""  ZR_High

BO_ 1173 Mem_Taster_HBF_01: 3 Gateway
 SG_ MTHBF_CRC : 0|8@1+ (1,0) [0|255] ""  Vector__XXX
 SG_ MTHBF_BZ : 8|4@1+ (1,0) [0|15] ""  Vector__XXX
 SG_ BFS_Sitzhoehe_hoch : 12|1@1+ (1.0,0.0) [0.0|1] ""  ZR_High
 SG_ BFS_Sitzhoehe_runter : 13|1@1+ (1.0,0.0) [0.0|1] ""  ZR_High
 SG_ MTHBF_ein : 15|1@1+ (1.0,0.0) [0.0|1] ""  ZR_High
 SG_ BFS_Laengsverst_vor : 16|1@1+ (1.0,0.0) [0.0|1] ""  ZR_High
 SG_ BFS_Laengsverst_zurueck : 17|1@1+ (1.0,0.0) [0.0|1] ""  ZR_High
 SG_ BFS_Lehnenneigung_vor : 18|1@1+ (1.0,0.0) [0.0|1] ""  ZR_High
 SG_ BFS_Lehnenneigung_zurueck : 19|1@1+ (1.0,0.0) [0.0|1] ""  ZR_High
 SG_ BFS_Lehnenkopf_vor : 20|1@1+ (1.0,0.0) [0.0|1] ""  ZR_High
 SG_ BFS_Lehnenkopf_zurueck : 21|1@1+ (1.0,0.0) [0.0|1] ""  ZR_High
 SG_ BFS_Kopfstuetzen_hoch : 22|1@1+ (1.0,0.0) [0.0|1] ""  ZR_High
 SG_ BFS_Kopfstuetzen_runter : 23|1@1+ (1.0,0.0) [0.0|1] ""  ZR_High

BO_TX_BU_ 982 :Gateway,Gateway_PAG;
BO_TX_BU_ 1624 :Gateway,Gateway_PAG;
BO_TX_BU_ 1321 :Gateway,Gateway_PAG;
BO_TX_BU_ 822 :Gateway,Gateway_PAG;
BO_TX_BU_ 134 :Gateway,Gateway_PAG;
BO_TX_BU_ 917 :Gateway,Gateway_PAG;
BO_TX_BU_ 1153 :ZR_High,ZR_LIMU,ZR_MIB_TOP_ab_Gen3,ZR_Standard;
BO_TX_BU_ 1639 :Gateway,Gateway_PAG;
BO_TX_BU_ 957 :Gateway,Gateway_PAG;
BO_TX_BU_ 1178 :Gateway,Gateway_PAG;
BO_TX_BU_ 954 :Gateway,Gateway_PAG;
BO_TX_BU_ 956 :Gateway,Gateway_PAG;
BO_TX_BU_ 1180 :Gateway,Gateway_PAG;
BO_TX_BU_ 1170 :Gateway,Gateway_PAG;
BO_TX_BU_ 1173 :Gateway,Gateway_PAG;
CM_ BO_ 982 "MQB";
CM_ BO_ 134 "ab MQB mit CRC in Byte 1";
CM_ BO_ 917 "MLB";
CM_ BO_ 1639 "MLBevo";
CM_ BO_ 957 "MLBevo";
CM_ BO_ 1178 "ab MQB 7.2";
CM_ BO_ 956 "MLBevo";
CM_ BO_ 1180 "Ab MLBevo - CRC
";
CM_ BO_ 1170 "Ab MLBevo - CRC
";
CM_ BO_ 1173 "Ab MLBevo - CRC";

CM_ SG_ 982 BCM2_Bremsl_durch_ECD "Bremslicht (ECD-Bremsung)
";
CM_ SG_ 982 LH_3_Bremsl_def "Fehlerstatus 3. Bremsleuchte
";
CM_ SG_ 982 LH_Aussenlicht_def "Aussenlicht kann nicht mehr korrekt angesteuert werden (EEPROM Codierung kann nicht mehr ausgelesen werden)
";
CM_ SG_ 982 LH_Blinker_HL_akt "Blinker hinten links
";
CM_ SG_ 982 LH_Blinker_HR_akt "Blinker hinten rechts
";
CM_ SG_ 982 LH_Blinker_li_def "Fehlerstatus Blinker hinten links
";
CM_ SG_ 982 LH_Blinker_re_def "Fehlerstatus Blinker hinten rechts
";
CM_ SG_ 982 LH_Brems_Blk_li_def "Konfiguration BRL + BLK links 
";
CM_ SG_ 982 LH_Brems_Blk_re_def "Konfiguration BRL + BLK rechts
";
CM_ SG_ 982 LH_Bremsl_li_def "Fehlerstatus Bremslicht hinten links (Detektion Einzelausfall)
";
CM_ SG_ 982 LH_Bremsl_li_ges_def "Fehlerstatus Bremslicht hinten links (Detektion Totalausfall)
";
CM_ SG_ 982 LH_Bremsl_mi_def "Fehlerstatus Bremslicht mitte oder Gepäckraumklappe  (Detektion Einzelausfall)";
CM_ SG_ 982 LH_Bremsl_re_def "Fehlerstatus Bremslicht hinten rechts  (Detektion Einzelausfall)
";
CM_ SG_ 982 LH_Bremsl_re_ges_def "Fehlerstatus Bremslicht hinten rechts (Detektion Totalausfall)";
CM_ SG_ 982 LH_Bremslicht_H_aktiv "Bremslicht hinten
";
CM_ SG_ 982 LH_Diag_LED_li_def "Heckleuchte links defekt";
CM_ SG_ 982 LH_Diag_LED_re_def "Heckleuchte rechts defekt";
CM_ SG_ 982 LH_Diag_Status_li_def "Außenlicht Diagnose 
Systemstörung links";
CM_ SG_ 982 LH_Diag_Status_re_def "Außenlicht Diagnose Systemstörung rechts ";
CM_ SG_ 982 LH_Kennzl_def "Fehlerstatus Kennzeichenbeleuchtung hinten
";
CM_ SG_ 982 LH_Nebel_li_def "Fehlererkennung Nebelschlusslicht hinten links
";
CM_ SG_ 982 LH_Nebel_mi_def "Fehlererkennung Nebelschlusslicht hinten Mitte


";
CM_ SG_ 982 LH_Nebel_re_def "Fehlererkennung Nebelschlusslicht hinten rechts
";
CM_ SG_ 982 LH_Nebelschluss_aktiv "Nebelschlusslicht
";
CM_ SG_ 982 LH_Parklicht_HL_aktiv "Parklicht hinten links 
";
CM_ SG_ 982 LH_Parklicht_HR_aktiv "Parklicht hinten rechts 
";
CM_ SG_ 982 LH_Rueckf_li_def "Fehlererkennung Rückfahrlicht hinten links
";
CM_ SG_ 982 LH_Rueckf_mi_def "Fehlererkennung Rückfahrlicht Mitte
";
CM_ SG_ 982 LH_Rueckf_re_def "Fehlererkennung Rückfahrlicht hinten rechts
";
CM_ SG_ 982 LH_Rueckfahrlicht_aktiv "Rueckfahrlicht";
CM_ SG_ 982 LH_Schluss_Brems_li_def "Konfiguration SL+ BRL + PL links und SL+ BRL  links
";
CM_ SG_ 982 LH_Schluss_Brems_mi_def "Fehlerstatus Schluss + Bremslicht mitte defekt (Detektion Einzelausfall)";
CM_ SG_ 982 LH_Schluss_Brems_Nebel_li_def "Signal wird gesetzt, wenn eine Unterbrechung oder  ein Kurzschluss am Lampenausgang für Schluss_Brems_Nebelschlusslicht erkannt wird.";
CM_ SG_ 982 LH_Schluss_Brems_Nebel_re_def "Signal wird gesetzt, wenn eine Unterbrechung oder  ein Kurzschluss am Lampenausgang für Schluss_Brems_Nebelschlusslicht erkannt wird.";
CM_ SG_ 982 LH_Schluss_Brems_re_def "Konfiguration SL+ BRL + PL rechts und SL+ BRL  rechts
";
CM_ SG_ 982 LH_Schluss_Nebel_li_def "Konfiguration SL + NSL links oder SL + NSL + PL links
";
CM_ SG_ 982 LH_Schluss_Nebel_re_def "Konfiguration SL + NSL rechts oder SL + NSL + PL rechts
";
CM_ SG_ 982 LH_Schlusslicht_li_def "Fehlererkennung Schlusslicht hinten links
";
CM_ SG_ 982 LH_Schlusslicht_mi_def "Fehlererkennung Schlusslicht hinten Mitte";
CM_ SG_ 982 LH_Schlusslicht_re_def "Fehlererkennung Schlusslicht hinten rechts
";
CM_ SG_ 982 LH_SL_BRL_BLK_li_def "Konfiguration SL + BRL + BLK links oder SL + BRL + BLK + PL links
";
CM_ SG_ 982 LH_SL_BRL_BLK_re_def "Konfiguration SL + BRL + BLK rechts oder SL + BRL + BLK + PL rechts
";
CM_ SG_ 982 LH_Standlicht_H_aktiv "Standlicht hinten
";
CM_ SG_ 982 LH_Zusatzschlussl_def "mindestens ein Zusatzschlusslicht in der Heckbeleuchtung defekt.";

CM_ SG_ 1624 BCM1_Licht_Dunkelheit_aktiv "Licht aktiv aufgrund von Dunkelheit (nicht bei Autobahn-, Tagfahr- oder Regenlicht)";
CM_ SG_ 1624 BCM1_Linksverkehr "Information über Aufbauzustand des Fzg:
0 = Scheinwerfer für Rechtsverkehr
1 = Scheinwerfer für Linksverkehr";
CM_ SG_ 1624 Licht_Vorne_01_CRC "Für MLB:
'Berechnung siehe Lastenheft 'Kommunikationsabsicherung für FlexRay und CAN''

Ab MQB und MLBevo:
'Berechnung siehe Lastenheft 'End-to-End Kommunikationsabsicherung''

Endwerte siehe Begleitdokument 'S-PDU Kennungsfolgen'";
CM_ SG_ 1624 LV_Abbiegelicht_li_def "Fehlerstatus Abbiegelicht vorne links
";
CM_ SG_ 1624 LV_Abbiegelicht_re_def "Fehlerstatus Abbiegelicht vorne rechts
";
CM_ SG_ 1624 LV_Abblend_Fernlicht_li_def "Fehlerstatus Abblendlicht und Fernlicht links ";
CM_ SG_ 1624 LV_Abblend_Fernlicht_re_def "Fehlerstatus Abblendlicht und Fernlicht rechts";
CM_ SG_ 1624 LV_Abblendlicht_Anzeige "Abblendlicht aktiv";
CM_ SG_ 1624 LV_Abblendlicht_li_def "Fehlerstatus Abblendlicht vorne links 
";
CM_ SG_ 1624 LV_Abblendlicht_re_def "Fehlerstatus Abblendlicht vorne rechts
";
CM_ SG_ 1624 LV_Abblendlicht_TFL_li_def "Fehlerstatus Abblendlicht und Tagfahrlicht links
";
CM_ SG_ 1624 LV_Abblendlicht_TFL_re_def "Fehlerstatus Abblendlicht und Tagfahrlicht rechts ";
CM_ SG_ 1624 LV_AFL_aktiv_Anzeige "Anzeige AFL-Funktion";
CM_ SG_ 1624 LV_AFL_defekt "Fehlerstatus AFL
";
CM_ SG_ 1624 LV_Aussenlicht_def "Aussenlicht kann nicht mehr korrekt angesteuert werden (EEPROM Codierung kann nicht mehr ausgelesen werden)
";
CM_ SG_ 1624 LV_Blinker_li_def "Fehlerstatus Blinker vorne links
";
CM_ SG_ 1624 LV_Blinker_re_def "Fehlerstatus Blinker vorne rechts
";
CM_ SG_ 1624 LV_Blinker_VL_aktiv "Blinker vorne links
";
CM_ SG_ 1624 LV_Blinker_VR_aktiv "Blinker vorne links
";
CM_ SG_ 1624 LV_Blk_li_Seite_def "Fehlerstatus Seitenblinker links
";
CM_ SG_ 1624 LV_Blk_re_Seite_def "Fehlerstatus Blinker Seite rechts
";
CM_ SG_ 1624 LV_Fernlicht_Anzeige "Fernlicht_aktiv";
CM_ SG_ 1624 LV_Fernlicht_li_def "Fehlerstatus Fernlicht vorne links
";
CM_ SG_ 1624 LV_Fernlicht_re_def "Fehlerstatus Fernlicht vorne rechts
";
CM_ SG_ 1624 LV_FLA_aktiv_Anzeige "Ansteuerung FLA-Lampe im Kombi (BCM1 Bedienmaster)";
CM_ SG_ 1624 LV_FLA_defekt "Fehlerstatus FLA (Anzeige des entsprechenden Fehlertext im Kombi)";
CM_ SG_ 1624 LV_FLA_Sensor_blockiert "Status FLA-Sensor (Anzeige des entsprechenden Fehlertext im Kombi)";
CM_ SG_ 1624 LV_LED_Scheinwerfer_li_def "Fehlerstatus LED-Scheinwerfer links
";
CM_ SG_ 1624 LV_LED_Scheinwerfer_re_def "Fehlerstatus LED-Scheinwerfer rechts";
CM_ SG_ 1624 LV_MXB_Status_Anzeige "Aktueller Status des Fernlichts / MxB zur Signalisierung im Kombi.";
CM_ SG_ 1624 LV_Nebellicht_Anzeige "Nebellicht_aktiv
";
CM_ SG_ 1624 LV_Nebellicht_li_def "Fehlerstatus Nebelscheinwerfer vorne links
";
CM_ SG_ 1624 LV_Nebellicht_re_def "Fehlerstatus Nebelscheinwerfer vorne rechts
";
CM_ SG_ 1624 LV_Nebellicht_TFL_li_def "Fehlerstatus Nebellicht und Tagfahrlicht links ";
CM_ SG_ 1624 LV_Nebellicht_TFL_re_def "Fehlerstatus Nebellicht und Tagfahrlicht rechts";
CM_ SG_ 1624 LV_Nebelschlusslicht_Anzeige "Nebelschlusslicht_aktiv
";
CM_ SG_ 1624 LV_Standlicht_Anzeige "Anzeige Standlicht
";
CM_ SG_ 1624 LV_Standlicht_li_def "Fehlerstatus Standlicht vorne links
";
CM_ SG_ 1624 LV_Standlicht_re_def "Fehlerstatus Standlicht vorne rechts
";
CM_ SG_ 1624 LV_Standlicht_TFL_li_def "Fehlerstatus Standlicht und Tagfahrlicht links ";
CM_ SG_ 1624 LV_Standlicht_TFL_re_def "Fehlerstatus Standlicht und Tagfahrlicht rechts ";
CM_ SG_ 1624 LV_Tagfahrlicht_Anzeige "Anzeige Tagfahrlicht
";
CM_ SG_ 1624 LV_Tagfahrlicht_li_def "Fehlerstatus Tagfahrlicht links
";
CM_ SG_ 1624 LV_Tagfahrlicht_re_def "Fehlerstatus Tagfahrlicht rechts";

CM_ SG_ 1321 Lift_Anforderung_EFP "Lift Funktionsanforderungen";
CM_ SG_ 1321 Lift_Charisma_FahrPr "


";
CM_ SG_ 1321 Lift_Charisma_Status "Systemstatus des Charismateilnehmers

";
CM_ SG_ 1321 Lift_Charisma_Umschaltung "Erkennung Umschaltaufforderung des Charisma-Teilnehmers";
CM_ SG_ 1321 Lift_ESP_Zuschaltung "Zwangsweise Aktivierung der ESP-Funktionalität wird angefordert.";
CM_ SG_ 1321 Lift_LED "Status der Liftanzeige";
CM_ SG_ 1321 Lift_Meldung_01 "Meldung 1 für das Kombi ";
CM_ SG_ 1321 Lift_Meldung_02 "Meldung 2 für das Kombi ";
CM_ SG_ 1321 Lift_Meldung_03 "Meldung 3 für das Kombi ";
CM_ SG_ 1321 Lift_Meldung_04 "Meldung 4 für das Kombi ";
CM_ SG_ 1321 Lift_Meldung_05 "Meldung 5 für das Kombi ";
CM_ SG_ 1321 Lift_Meldung_06 "Meldung 6 für das Kombi ";
CM_ SG_ 1321 Lift_Meldung_07 "Meldung 7 für das Kombi ";
CM_ SG_ 1321 Lift_Meldung_08 "Meldung 8 für das Kombi ";
CM_ SG_ 1321 Lift_Meldung_09 "Meldung 9 für das Kombi ";
CM_ SG_ 1321 Lift_Meldung_10 "Meldung 10 für das Kombi";
CM_ SG_ 1321 Lift_Meldung_11 "Meldung 11 für das Kombi";
CM_ SG_ 1321 Lift_Meldung_12 "Meldung 12 für das Kombi";
CM_ SG_ 1321 Lift_Meldung_13 "Meldung 13 für das Kombi";
CM_ SG_ 1321 Lift_Meldung_14 "Meldung 14 für das Kombi";
CM_ SG_ 1321 Lift_Position "Aktuelle Position der Liftfunktion";
CM_ SG_ 1321 Lift_SpannungsAnf "Anforderung des Lift zur Spannungsanhebung des Bordnetzes.";
CM_ SG_ 1321 Lift_StartStopp_Info "Stopp-Freigabe und Start-Anforderung an den Start-Stopp-Koordinator";

CM_ SG_ 822 LR_HZG_Taster_on_off "Anforderung des Schalters am MFL: Lenkradheizung aus/ein
(Regelung der LR_HZG ist im SMLS)";
CM_ SG_ 822 LR_HZG_Temp_Sensor "Temperaturwert Lenkradheizung";

CM_ SG_ 2527679774 LRM_Auto_Error "Auto mode not available";
CM_ SG_ 2527679774 LRM_General_Error "ECU Internal fault";
CM_ SG_ 2527679774 LRM_Glass_OC_Error "Glass open circuit";
CM_ SG_ 2527679774 LRM_Glass_Rear_OC_Error "Rear glass open circuit";
CM_ SG_ 2527679774 LRM_Glass_Rear_SC_Error "Rear glass short circuit";
CM_ SG_ 2527679774 LRM_Glass_SC_Error "Glass short circuit";
CM_ SG_ 2527679774 LRM_Level "Electro-chromic glass level status";
CM_ SG_ 2527679774 LRM_Level_Rear "Rear electro-chromic glass level status";
CM_ SG_ 2527679774 LRM_Manual_Error "Manual mode not available";
CM_ SG_ 2527679774 LRM_Mode "Electro-chromic glass mode status";

CM_ SG_ 134 LWI_01_BZ "Botschaft asynchron geroutet. Zählerwert kann springen.";
CM_ SG_ 134 LWI_01_CRC "Für MLB:
'Berechnung siehe Lastenheft 'Kommunikationsabsicherung für FlexRay und CAN''

Ab MQB und MLBevo:
'Berechnung siehe Lastenheft 'End-to-End Kommunikationsabsicherung'

Endwerte siehe Begleitdokument 'S-PDU Kennungsfolgen'";
CM_ SG_ 134 LWI_Lenkradw_Geschw "Wertebereich = +/- 2500 Grad/s
Auflösung = 5 Grad/s

Hinweis: Zusätzlich gestellte Winkel bei Dynamiklenkung beachten !";
CM_ SG_ 134 LWI_Lenkradwinkel "Wertebereich = +/- 800 Grad
Auflösung = 0,1 Grad
ACHTUNG: spezifizierte Interne Auflösung des Sensors beträgt aber nur Schrittweite 0,5 Grad!

Hinweis:
MLB: Zusätzlich gestellte Winkel bei Dynamiklenkung beachten !
MQB: Nicht konstante Lenkübersetzu";
CM_ SG_ 134 LWI_MFL_Abschaltung "Signal zur Anforderung der MFL Abschaltung bei Erkennung einer dynamischen Lenkbewegung.";
CM_ SG_ 134 LWI_QBit_Lenkradwinkel "Das QBit wird auch bei nicht abgeglichenem Lenkradwinkelsensor gesetzt";
CM_ SG_ 134 LWI_QBit_Sub_Daten "Es gilt die Signalspezifikation laut LAH";
CM_ SG_ 134 LWI_Sub_Daten "Verschlüsseltes Datenpaket vom Sub-Rechner des LWS, Verwendung nur durch SCU und ESP_ADS
Verwendung gemäß 'Sicherheitsanforderungen an Empfängersteuergeräte'

Im MLB gilt die Signalspezifikation: LAH 8K0953B
Im MLBevo gilt die Signalspezifikation LAH.";
CM_ SG_ 134 LWI_VZ_Lenkradw_Geschw "Vorzeichen Lenkradwinkelgeschwindigkeit gemäss DIN70000; 
Nullstellung = +0";
CM_ SG_ 134 LWI_VZ_Lenkradwinkel "Vorzeichen Lenkradwinkel gemäss DIN70000; 
Nullstellung = +0";

CM_ SG_ 917 AFS_Abbiegelicht_Dimm_Anf "Beschreibt ob das Abbiegelicht gedimmt oder hart einschalten werden soll. Dimmkurve ist Empfänger hinterlegt.";
CM_ SG_ 917 AFS_Abbiegelicht_li_Anf "Anforderung das Abbiegelicht links einzuschalten";
CM_ SG_ 917 AFS_Abbiegelicht_re_Anf "Anforderung das Abbiegelicht rechts einzuschalten";
CM_ SG_ 917 AFS_adaptive_LV_verbaut "Verfügbarkeit der adaptiven Lichtverteilung im AFS-SG.
(Das BCM steuert mit diesem Signal die Einblendung des entsprechenden Menüs)";
CM_ SG_ 917 AFS_Allwetterlicht "Status ¿Allwetterlicht¿ - Licht für schlechte Sichtverhältnisse
(bei Defekt -> nicht aktiv)";
CM_ SG_ 917 AFS_Charisma_FahrPr "MLBevo: Aktuelles Fahrprogramm des Charisma-Teilnehmers (siehe Systemlastenheft Drive Select)
MQB: Istwert der Kennlinie (siehe Systemlastenheft MQB FPA)";
CM_ SG_ 917 AFS_Charisma_Status "Charisma Systemstatus des Charisma-Teilnehmers

Wert 0x3 ist nur für Fahrzeuge ab MQB relevant";
CM_ SG_ 917 AFS_Charisma_Umschaltung "Erkennung  Umschaltaufforderung des Charisma-Teilnehmers";
CM_ SG_ 917 AFS_Ersatzlicht_Links "Bei aktivierter Ersatzlichtfunktion wird das Abblendlicht ausgeschaltet und eine Ersatzlichtquelle eingeschaltet (z.Zt. B7)";
CM_ SG_ 917 AFS_Ersatzlicht_Rechts "Bei aktivierter Ersatzlichtfunktion wird das Abblendlicht ausgeschaltet und eine Ersatzlichtquelle eingeschaltet (z.Zt. B7)";
CM_ SG_ 917 AFS_Fehlertext "Fehlertext wird im Kombi angezeigt (z.Zt nur bei VW)";
CM_ SG_ 917 AFS_Fernlicht_li_defekt "Beschreibt ob das Fernlicht des linken Scheinwerfers defekt ist";
CM_ SG_ 917 AFS_Fernlicht_re_defekt "Beschreibt ob das Fernlicht des rechten Scheinwerfers defekt ist";
CM_ SG_ 917 AFS_Fernlicht_Status "Beschreibt ob das Fernlicht aktiv oder inaktiv ist";
CM_ SG_ 917 AFS_Lampe "Status der Fehlerlampe: aktuell anliegender Fehlerzustand des dynamischen oder statischen Kurvenlichtes";
CM_ SG_ 917 AFS_LED_Blinkmode "Lampe soll im Warnfall mit 1Hz blinken, wenn das Bit gesetzt ist (z.Zt nur bei VW)";
CM_ SG_ 917 AFS_Status_adaptive_LV "Gibt den Status der adaptiven Lichtverteilung an";
CM_ SG_ 917 AFS_Verfuegbarkeit_GLW "Beschreibt die Verfügbarkeit der Gleitenden Leuchtweite / Fernlichtassistenz - Verfügbarkeit bedeutet, dass die Funktion Gleitende Leuchtweite möglich ist";
CM_ SG_ 917 GLW_Sensor_blockiert "Das Signal zeigt an, dass die Kamera zur Zeit keine Sicht hat. 
Verhalten wie Fernlichassisten. 
Weiterleitung des Signals vom BCM an das KOMBI";
CM_ SG_ 917 LWR_AFS_Grundeinstellung "Grundeinstellung des Abblendlichtes am Lichteinstellkasten im Service oder Bandende mit Tester erfolgt! (auch für das dynamische Kurvernlicht)";
CM_ SG_ 917 LWR_AFS_Parametrisierung "Parametrisierung wählt die Fahrzeugvariante und die AFS-Variante aus";
CM_ SG_ 917 LWR_Hoehenwert_HL "Aktueller Höhensensorwert Hinten Links
MSS LB überträgt den Aktueller Höhensensorwert Vorne Rechts.

0x7F = 0 mm";
CM_ SG_ 917 LWR_Hoehenwert_VL "Aktueller Höhensensorwert Vorne Links

0x7F = 0 mm";
CM_ SG_ 917 LWR_Initialisierungslauf "Initialisierungslauf der Schrittmotoren, erfolgt defaultmäßig beim Motorstart";
CM_ SG_ 917 LWR_Lampe "Status der Fehlerlampe: aktuell anliegender Fehlerzustand";
CM_ SG_ 917 LWR_Modus "Schnelle oder langsame Regelart der LWR";
CM_ SG_ 917 LWR_Pos_Schrittmotor "Position des Aktuators in Prozent des maximalen Stellweges; vor dem Initialisierungslauf (Motorstart) wird der Initwert ausgegeben: 
0% : tiefste Stellung (auf Block) des Schrittmotors;
100% : maximaler Verstellweg des Schrittmotors (nicht die Grenze de";
CM_ SG_ 917 LWR_Reisemodus_Texte "Anzeige der eingestellten Verkehrsart bei aktivem Touristenlicht";
CM_ SG_ 917 LWR_Sicherheitsposition_li "Rechter Scheinwerfer in Sicherheitsposition.";
CM_ SG_ 917 LWR_Sicherheitsposition_re "Rechter Scheinwerfer in Sicherheitsposition.";
CM_ SG_ 917 LWR_Touristenmodus_aktiv "Über MMI sendet BCM1 eine Anforderung Touristenmodus an die LWR. Diese sendet als Rückmeldung an BCM1, dass der Touristenmodus aktiv geschaltet wurde";
CM_ SG_ 917 LWR_Touristenmodus_verbaut "Verfügbarkeit der Touristenfunktion im AFS/LWR-SG.
(Das BCM steuert mit diesem Signal die Einblendung des entsprechenden Menüs)";

CM_ SG_ 1153 DSSS_Warning "DSSS - Driving Safety Support System Meldungen";
CM_ SG_ 1153 MIB_Tongenerator_PH_verfuegbar "Verfügbarkeit des Tongenerators im MIB für die Nutzung durch die Parkhilfe";
CM_ SG_ 1153 MMI_Counter_Bedienevent "Signal wird inkrementiert, wenn Bedienevent stattgefunden hat.";
CM_ SG_ 1153 MMI_Gauges_active "Signal sent from Main Unit to Kombi instrument to give the display status of the additional gauges in the rotating display";
CM_ SG_ 1153 MMI_Gurt_Mic_ref "Referenzsignal für das Gurtmikrofon Steuergerät zur Signalisierung ob der Downlink aktiv oder inaktiv ist";
CM_ SG_ 1153 MMI_SDS_aktiv "Signal wird gesetzt, solange die Sprachbedienung aktiv ist.";
CM_ SG_ 1153 MMI_StartStopp_Info "Stopp-Freigabe und Start-Anforderung an den Start-Stopp-Koordinator
Signal gilt nur für MHEV12V im MLBevo, Stoppverbot darf nur bei Ausstattungsvariante mit 3D-Sound verwendet werden.";
CM_ SG_ 1153 MU_SecondDisplay "Dient zur Überwachung der zweiten LVDS Leitung.";
CM_ SG_ 1153 MU_Update_Time "Ermöglicht auslesen der Historiendaten, wann ein Update lief";
CM_ SG_ 1153 Nav_FoD_Status "FoD Status der Navigation";
CM_ SG_ 1153 ZR_Kindersicherung_RSE "Sperren der Rearseat Unit (Komplette Weckfähigkeit)";
CM_ SG_ 1153 ZR_LAPP_Sondermodus_Status "Statusrückmeldung zum ZR Sondermodus (BT Abschaltung)";
CM_ SG_ 1153 ZR_LoGeWa_Event_Kombiwarnung "Event für Kombiwarnung";
CM_ SG_ 1153 ZR_MXB_Manoever_Ansage "Übertragung der aktuellen Manöver-Ansage für MatrixBeam. Dient zur Veränderung des Lichtbilds abhängig von Navigationsmanövern.";
CM_ SG_ 1153 ZR_Parken_Sondermodus "Rückkanal zum pilotierten Parken zur Signalisierung Status Sondermodus";
CM_ SG_ 1153 ZR_RSE_aktivieren "Weckfähigkeit der RSE";
CM_ SG_ 1153 ZR_Rundenbewertung "Bewertung einer aktuellen Runde (langsamer, gleich schnell, schneller)";
CM_ SG_ 1153 ZR_Rundenfortschritt "Verhältnis von gefahrener Strecke in einer aktuellen Runde zur Länge einer Referenzrunde in Prozent";
CM_ SG_ 1153 ZR_Sta_Inszenierung "MIB sendet Status über Inszenierungssound (welcome sound) an BCM1
Zweck: Synchronisierung mit weiteren Teilnehmern der Startupinszenierung";

CM_ SG_ 2527679771 LIMU_Aero_Selec_HMI_Anf "Virtual buttons for different tuning of the Aerodynamics modes.";
CM_ SG_ 2527679771 LIMU_BAR_Mode_Switch_HMI_Anf "Manual opening of rear spoiler";
CM_ SG_ 2527679771 LIMU_Confirmation_HMI_Anf "Confirmation virtual button for Slider setting confirm";
CM_ SG_ 2527679771 LIMU_DR_Select_HMI_Anf "Virtual button for Dynamic regulation of Dampfer system";
CM_ SG_ 2527679771 LIMU_Reset_switch_HMI_Anf "Reset virtual button for Slider setting reset";
CM_ SG_ 2527679771 MainUnit_02_BZ "4bit Botschaftszähler, wird mit jeder Sendebotschaft inkrementiert";
CM_ SG_ 2527679771 MainUnit_02_CRC "Für MLB:
Berechnung siehe Lastenheft 'Kommunikationsabsicherung für FlexRay und CAN'
Ab MQB und MLBevo:
Berechnung siehe Lastenheft 'End-to-End Kommunikationsabsicherung'

Endwerte siehe Begleitdokument 'S-PDU Kennungsfolgen'";
CM_ SG_ 2527679771 ZR_ECR_LevelMode_HMI_Anf "Electro-chromic glass level request";
CM_ SG_ 2527679771 ZR_ECR_SwitchMode_HMI_Anf "Electro-chromic glass mode request";
CM_ SG_ 2527679771 ZR_Slider_soll_01 "Information about the slider request";
CM_ SG_ 2527679771 ZR_Slider_soll_02 "Information about the slider request";
CM_ SG_ 2527679771 ZR_Slider_soll_03 "Information about the slider request";

CM_ SG_ 1639 BFS_Fond_Bed_Ack "Bestätigung Beifahrersitzverstellung vom Fond";
CM_ SG_ 1639 BFS_FSV_ausgeklappt "Zustandssignalisierung der el. mech. Fußstütze (eingeklappt oder ausgeklappt)";
CM_ SG_ 1639 BFS_GHV_aktiv "Verstellung Gurthoehe
";
CM_ SG_ 1639 BFS_Gurtbringer_Sperre "Freigabesignal für den Gurtzubringer";
CM_ SG_ 1639 BFS_Klapptisch_offen "Signalisiert eine Verstelleinschränkung des Beifahrersitz  (für BAP Visualisierung)";
CM_ SG_ 1639 BFS_Kollisionsbereich_Windschott "Beifahrersitz steht innerhalb oder außerhalb Windschottbereich. Sitzposition in Kennfeld bedeutet: Windschott kann ohne Kollision ausfahren.";
CM_ SG_ 1639 BFS_Kollisionsgefahr_Windschott "Warnmeldung in Kombi anzeigen, dass manuelle oder automatische Sitzfahrt nicht (mehr) möglich ist, da Kollisionsgefahr zwischen Sitz und Windschott besteht.";
CM_ SG_ 1639 BFS_KSS_Fahrt_aktiv "Komfortseitensichtfahrt (BFS)";
CM_ SG_ 1639 BFS_KSV_aktiv "Kopfstuetzenverstellung BFS
";
CM_ SG_ 1639 BFS_Lehne_nicht_verriegelt "Fahrer Sitz Lehne Verstellung Verriegelt Status

Verwendung nur im  Bentley";
CM_ SG_ 1639 BFS_LHV_aktiv "Verstellung Lordose Höhe
";
CM_ SG_ 1639 BFS_LKV_aktiv "Verstellung Lehnenkopf
";
CM_ SG_ 1639 BFS_LNV_aktiv "Verstellung Lehnenneigung
";
CM_ SG_ 1639 BFS_LWV_aktiv "Lordose W Verstellung
";
CM_ SG_ 1639 BFS_MMB_glob_stop "Abbruch Memoryverstellung";
CM_ SG_ 1639 BFS_MMB_lokal_Stop "mit dem lokal Stop moechte man, dass ein Sitz mit Pneumatik - Lordose sich im Memoryfall wie ein Sitz mit elektromechanischer Lordose verhaelt. Nur lokler Abbruch im TIP-Betrieb.";
CM_ SG_ 1639 BFS_MMB_storage "Speichern auf Memoryposition";
CM_ SG_ 1639 BFS_MMB_storage_beep "Quittierungston Sitzmemory BFS (Anforderung Kombi)

";
CM_ SG_ 1639 BFS_MMB_store "Speichern der Sitzposition
";
CM_ SG_ 1639 BFS_MMB_store_LED_on "LED für Speichern
";
CM_ SG_ 1639 BFS_MMB_tast "Memoryverstellung im Tastbetrieb";
CM_ SG_ 1639 BFS_MMB_tipp "Memoryverstellung im Tippbetrieb";
CM_ SG_ 1639 BFS_NFA_einfahren "Neigungsverstellbare Fussauflage im Fond muss eingefahren werden";
CM_ SG_ 1639 BFS_Ruhestellung_Status "dient der Signalisierung für eine Verstelleinschränkung, da der Sitz sich in Ruhestellung befindet.";
CM_ SG_ 1639 BFS_Seat_Locked "Anzeige des gesperrten Beifahrersitzes aufgrund ungültiger Sitzposition.";
CM_ SG_ 1639 BFS_SHV_aktiv "Sitzhöhenverstellung
";
CM_ SG_ 1639 BFS_Sitzfahrt_aktiv "Aktive Sitzfahrt";
CM_ SG_ 1639 BFS_Sitzsym_Fahrt_aktiv "Sitzsymetriefahrt
";
CM_ SG_ 1639 BFS_SLV_aktiv "Sitzlängsverstellung
";
CM_ SG_ 1639 BFS_SNV_aktiv "Verstellung Sitzneigung
";
CM_ SG_ 1639 BFS_STV_aktiv "Sitztiefeverstellung
";

CM_ SG_ 957 BFS_Kopfstuetze_vor "Berücksichtigung des Aktors Kopfstützenverstellung in X-Richtung bei der Fernsteuerung des Beifahrsersitzes von Hintersitz aus.";
CM_ SG_ 957 BFS_Kopfstuetze_zurueck "Berücksichtigung des Aktors Kopfstützenverstellung in X-Richtung bei der Fernsteuerung des Beifahrsersitzes von Hintersitz aus.";
CM_ SG_ 957 Fernsteuerung_BFS_LED "Fernsteuerung Beifahrersitz-LED
0 = keine Fernsteuerung des Sitzbedienschalters
1 = Fernsteuerung des Sitzbedienschalters - Tastenbetätigung am SBM führen zu keiner Reaktion.
      Anzeige lt. Empfangsbotschaft Mem_Beifahrersitzverstellung.";
CM_ SG_ 957 Fernsteuerung_Massage_LED "Fernsteuerung Sitzbedienmodul Massagefunktions-LED
0 = keine Fernsteuerung des Sitzbedienschalters
1 = Fernsteuerung des Sitzbedienschalters - Tastenbetätigung am SBM führen zu keiner Reaktion.
      Anzeige lt. Empfangsbotschaft Mem_Hx_Massage_Intens ";
CM_ SG_ 957 Mem_BFS_Spezialpos_loeschen "Spezialpositionen im BFS löschen";
CM_ SG_ 957 Mem_BFSFo_BeifaSitzverstellung "Funktionsrückmelde-LED 'Beifahrersitzverstellung aktiv'";
CM_ SG_ 957 Mem_BFSFo_BFS_Freigabe "Freigabe für die Fahrt des Beifahrersitzes aus der  Ruhestellung .";
CM_ SG_ 957 Mem_BFSFo_BFS_RSE_Freigabe "Freigabe für die RSE-Verstellung am am Ruhestellung.";
CM_ SG_ 957 Mem_BFSFo_Business_anfahren "Befehl um Business Position an zufahren";
CM_ SG_ 957 Mem_BFSFo_Fusstuetze_hoch "dient der Fusstuetzen -steuerung am Beifahrersitz aus dem Fond";
CM_ SG_ 957 Mem_BFSFo_Fusstuetze_runter "dient der Fusstuetzen -steuerung am Beifahrersitz aus dem Fond";
CM_ SG_ 957 Mem_BFSFo_Lordose_hoch "Anforderung Lordosenwölbung nach oben zu verschieben.";
CM_ SG_ 957 Mem_BFSFo_Lordose_runter "Anforderung Lordosenwölbung nach unten zu verschieben.";
CM_ SG_ 957 Mem_BFSFo_Lordose_vor "Anforderung Lordosenwölbung pneumatisch zu vergrößern.";
CM_ SG_ 957 Mem_BFSFo_Lordose_zurueck "Anforderung Lordosenwölbung zu verkleinern.";
CM_ SG_ 957 Mem_BFSFo_Massage_Geschw "Weiterleitung  der gewünschten Massage Geschwindigkeit ans IVB und zugleich Anforderungsbestätigung für LEDs am Klima-SG.";
CM_ SG_ 957 Mem_BFSFo_Massage_Intens "Weiterleitung  der gewünschten Massage Intensität ans IVB und zugleich Anforderungsbestätigung für LEDs am Klima-SG.";
CM_ SG_ 957 Mem_BFSFo_Massage_Prg "Weiterleitung  des gewünschten Massageprogramms ans IVB und zugleich Anforderungsbestätigung für LEDs am Klima-SG.";
CM_ SG_ 957 Mem_BFSFo_MMB_glob_Stop "Globaler Abbruch für automatische Funktionen";
CM_ SG_ 957 Mem_BFSFo_MMB_lokal_Stop "mit dem lokal Stop moechte man, dass ein Sitz mit Pneumatik - Lordose sich im Memoryfall wie ein Sitz mit elektromechanischer Lordose verhaelt. Nur lokler Abbruch im TIP-Betrieb.";
CM_ SG_ 957 Mem_BFSFo_MMB_storage "Angabe der zu speichernden oder einzustellenden Memoryposition";
CM_ SG_ 957 Mem_BFSFo_MMB_storage_beep "Quittierungston Sitzmemory  (Anforderung Kombi)";
CM_ SG_ 957 Mem_BFSFo_MMB_store "Aufforderung Memory-Position Mem_HL_MMB_store zu speichern";
CM_ SG_ 957 Mem_BFSFo_MMB_store_LED_on "LED zur Anzeige der Speicherbereitschaft";
CM_ SG_ 957 Mem_BFSFo_MMB_tast "Einstellung der Memoryposition im  Tastbetrieb";
CM_ SG_ 957 Mem_BFSFo_MMB_tipp "Einstellung der Memoryposition im  Tippbetrieb";
CM_ SG_ 957 Mem_BFSFo_NFA_aufgestellt "Neigungsverstellbare Fussauflage aufgestellt";
CM_ SG_ 957 Mem_BFSFo_Relax_anfahren "Befehl um Relax Position an zufahren";
CM_ SG_ 957 Mem_BFSFo_RSE_vor "dient der Monitorsteuerung (RSE) am Beifahrersitz aus dem Fond";
CM_ SG_ 957 Mem_BFSFo_RSE_zurueck "dient der Monitorsteuerung (RSE) am Beifahrersitz aus dem Fond";
CM_ SG_ 957 Mem_BFSFo_Sitzfahrt_aktiv "Signalisiert eine aktive Sitzfahrt.";
CM_ SG_ 957 Mem_BFSFo_Sitztiefe_vor "Anforderung Sitztiefe nach vorne zu verlängern.";
CM_ SG_ 957 Mem_BFSFo_Sitztiefe_zur "Anforderung Sitztiefe nach vorne zu verlängern.";

CM_ SG_ 1178 FS_BFS_Fond_Verst_enable "Verstellung Fond (vom MMI)
";
CM_ SG_ 1178 FS_BFS_KSS_Anfahrt "Komfortseitensicht Anfahrt BFS";
CM_ SG_ 1178 FS_BFS_Sitzsym_Anfahrt "Sitzsymetrie Anfahrt BFS";
CM_ SG_ 1178 FS_EE_BFS_enable "EasyEntry Freigabe für Befahrersitz.";
CM_ SG_ 1178 FS_EE_Fond_BFS_enable "EE Fond rechts

";
CM_ SG_ 1178 FS_EE_Fond_FS_enable "EE Fond links
";
CM_ SG_ 1178 FS_Fond_Bed_enable "Freigabe für Fondsitzverstellungen";
CM_ SG_ 1178 FS_GHV_aktiv "Verstellung Gurthöhe
";
CM_ SG_ 1178 FS_Gurtbringer_Sperre "Freigabesignal für den Gurtzubringer";
CM_ SG_ 1178 FS_Kollisionsbereich_Windschott "Fahrersitz steht innerhalb oder außerhalb Windschottbereich. Sitzposition in Kennfeld bedeutet: Windschott kann ohne Kollision ausfahren.";
CM_ SG_ 1178 FS_Kollisionsgefahr_Windschott "Warnmeldung in Kombi anzeigen, dass manuelle oder automatische Sitzfahrt nicht (mehr) möglich ist, da Kollisionsgefahr zwischen Sitz und Windschott besteht.";
CM_ SG_ 1178 FS_KSV_aktiv "Verstellung Kopfstütze
";
CM_ SG_ 1178 FS_Lehne_nicht_verriegelt "Fahrer Sitz Lehne Verstellung Verriegelt Status

Verwendung nur im Bentley";
CM_ SG_ 1178 FS_LHV_aktiv "Verstellung Lordose Höhe
";
CM_ SG_ 1178 FS_LKV_aktiv "Verstellung Lehnenkopf
";
CM_ SG_ 1178 FS_LNV_aktiv "Verstellung Lehnenneigung
";
CM_ SG_ 1178 FS_LWV_aktiv "Verstellung Lordose W
";
CM_ SG_ 1178 FS_MMB_glob_stop "Abbruch Memoryverstellung";
CM_ SG_ 1178 FS_MMB_lokal_Stop "mit dem lokal Stop moechte man, dass ein Sitz mit Pneumatik - Lordose sich im Memoryfall wie ein Sitz mit elektromechanischer Lordose verhaelt. Nur lokler Abbruch im TIP-Betrieb.";
CM_ SG_ 1178 FS_MMB_storage "Memory-Positionstaste, Funkschlüssel-Memory-ID, Benutzerkonto-Nummer";
CM_ SG_ 1178 FS_MMB_storage_beep "Quittierungston Sitzmemory FS (Anforderung Kombi)";
CM_ SG_ 1178 FS_MMB_store "Memoryposition Speichern";
CM_ SG_ 1178 FS_MMB_store_LED_on "LED für Speichern
";
CM_ SG_ 1178 FS_MMB_tast "Memoryverstellung im Tastbetrieb";
CM_ SG_ 1178 FS_MMB_tipp "Memoryverstellung im Tippbetrieb";
CM_ SG_ 1178 FS_NFA_einfahren "Neigungsverstellbare Fussauflage im Fond muss eingefahren werden";
CM_ SG_ 1178 FS_SHV_aktiv "Verstellung Sitzhöhe

";
CM_ SG_ 1178 FS_Sitzfahrt_aktiv "Aktive Sitzfahrt Fahrersitz
";
CM_ SG_ 1178 FS_SLV_aktiv "Sitzlängsverstellung
";
CM_ SG_ 1178 FS_SNV_aktiv "Verstellung Sitzneigung
";
CM_ SG_ 1178 FS_Spezialposition_anfahren "paralell zu diesem Signal wird eine Botschaft auf den KCAN gesendet in der spezielle Anforderungen für den Empfänger stehen. 
Dieses Signal dient zusätzlich der Checksummenabsicherung bei einer Remotverstellung ";
CM_ SG_ 1178 FS_STV_aktiv "Verstellung Sitztiefe
";

CM_ SG_ 954 FS_BFS_aufraeumen "Das Signal dient der Fernsteuerung des Beifahrersitz.";
CM_ SG_ 954 FS_BFSFo_aufraeumen "Das Signal dient der Fernsteuerung des Beifahrersitz.";
CM_ SG_ 954 FS_FSFo_aufraeumen "Das Signal dient der Fernsteuerung des Beifahrersitz.";
CM_ SG_ 954 FS_MMB_Sys_Fahrt_aktiv "Signalisierung einer aktiven Verstellung, solange der Sitz und/oder die Lenksäule im Fall Peronalisierung eine Automatikfahrt durchführt. Nutzung dieses Signals zur Verkürzung der Anzeigedauer des Abbruchtexts im Kombi oder der entsprechenden Abbruchmögli";
CM_ SG_ 954 FS_Remote_KSV_Taste_hoch "Zu FS_Remote_Target zugehöriges Aktionssignal zur Fernsteuerung von Sitzfunktionen (hier KSV).";
CM_ SG_ 954 FS_Remote_KSV_Taste_tief "Zu FS_Remote_Target zugehöriges Aktionssignal zur Fernsteuerung von Sitzfunktionen (hier KSV).";
CM_ SG_ 954 FS_Remote_KSV_Taste_vor "Zu FS_Remote_Target zugehöriges Aktionssignal zur Fernsteuerung von Sitzfunktionen (hier KSVx).";
CM_ SG_ 954 FS_Remote_KSV_Taste_zurueck "Zu FS_Remote_Target zugehöriges Aktionssignal zur Fernsteuerung von Sitzfunktionen (hier KSVx).";
CM_ SG_ 954 FS_Remote_LKV_Taste_vor "Zu FS_Remote_Target zugehöriges Aktionssignal zur Fernsteuerung von Sitzfunktionen (hier LKV).";
CM_ SG_ 954 FS_Remote_LKV_Taste_zurueck "Zu FS_Remote_Target zugehöriges Aktionssignal zur Fernsteuerung von Sitzfunktionen (hier LKV).";
CM_ SG_ 954 FS_Remote_LNV_Taste_vor "Zu FS_Remote_Target zugehöriges Aktionssignal zur Fernsteuerung von Sitzfunktionen (hier LNV).";
CM_ SG_ 954 FS_Remote_LNV_Taste_zurueck "Zu FS_Remote_Target zugehöriges Aktionssignal zur Fernsteuerung von Sitzfunktionen (hier LNV).";
CM_ SG_ 954 FS_Remote_LWV_Taste_breit "Zu FS_Remote_Target zugehöriges Aktionssignal zur Fernsteuerung von Sitzfunktionen (hier LWV).";
CM_ SG_ 954 FS_Remote_LWV_Taste_eng "Zu FS_Remote_Target zugehöriges Aktionssignal zur Fernsteuerung von Sitzfunktionen (hier LWV).";
CM_ SG_ 954 FS_Remote_Massage_Taste "Zu FS_Remote_Target zugehöriges Aktionssignal zur Fernsteuerung von Sitzfunktionen (hier Massage).";
CM_ SG_ 954 FS_Remote_Multif_Taster_hoch "Zu FS_Remote_Target zugehöriges Aktionssignal zur Fernsteuerung von Sitzfunktionen (hier MuFu).";
CM_ SG_ 954 FS_Remote_Multif_Taster_tief "Zu FS_Remote_Target zugehöriges Aktionssignal zur Fernsteuerung von Sitzfunktionen (hier MuFu).";
CM_ SG_ 954 FS_Remote_Multif_Taster_vor "Zu FS_Remote_Target zugehöriges Aktionssignal zur Fernsteuerung von Sitzfunktionen (hier MuFu).";
CM_ SG_ 954 FS_Remote_Multif_Taster_zurueck "Zu FS_Remote_Target zugehöriges Aktionssignal zur Fernsteuerung von Sitzfunktionen (hier MuFu).";
CM_ SG_ 954 FS_Remote_Programmwippe_hoch "Zu FS_Remote_Target zugehöriges Aktionssignal zur Fernsteuerung von Sitzfunktionen (hier MuFu).";
CM_ SG_ 954 FS_Remote_Programmwippe_tief "Zu FS_Remote_Target zugehöriges Aktionssignal zur Fernsteuerung von Sitzfunktionen (hier MuFu).";
CM_ SG_ 954 FS_Remote_SHV_Taste_hoch "Zu FS_Remote_Target zugehöriges Aktionssignal zur Fernsteuerung von Sitzfunktionen (hier SHV).";
CM_ SG_ 954 FS_Remote_SHV_Taste_tief "Zu FS_Remote_Target zugehöriges Aktionssignal zur Fernsteuerung von Sitzfunktionen (hier SHV).";
CM_ SG_ 954 FS_Remote_SLV_Taste_vor "Zu FS_Remote_Target zugehöriges Aktionssignal zur Fernsteuerung von Sitzfunktionen (hier SLV).";
CM_ SG_ 954 FS_Remote_SLV_Taste_zurueck "Zu FS_Remote_Target zugehöriges Aktionssignal zur Fernsteuerung von Sitzfunktionen (hier SLV).";
CM_ SG_ 954 FS_Remote_SNV_Taste_hoch "Zu FS_Remote_Target zugehöriges Aktionssignal zur Fernsteuerung von Sitzfunktionen (hier SNV).";
CM_ SG_ 954 FS_Remote_SNV_Taste_tief "Zu FS_Remote_Target zugehöriges Aktionssignal zur Fernsteuerung von Sitzfunktionen (hier SNV).";
CM_ SG_ 954 FS_Remote_STV_Taste_vor "Zu FS_Remote_Target zugehöriges Aktionssignal zur Fernsteuerung von Sitzfunktionen (hier STV).";
CM_ SG_ 954 FS_Remote_STV_Taste_zurueck "Zu FS_Remote_Target zugehöriges Aktionssignal zur Fernsteuerung von Sitzfunktionen (hier STV).";
CM_ SG_ 954 FS_Remote_SWV_Taste_breit "Zu FS_Remote_Target zugehöriges Aktionssignal zur Fernsteuerung von Sitzfunktionen (hier SWV).";
CM_ SG_ 954 FS_Remote_SWV_Taste_eng "Zu FS_Remote_Target zugehöriges Aktionssignal zur Fernsteuerung von Sitzfunktionen (hier SWV).";
CM_ SG_ 954 FS_RemoteTarget "Empfänger-Nummer der zugehörigen FS_Remote-Signale (Fernsteuerung von Sitzfunktionen BFS, FSFo & BFSFo vom Fahrersitz aus)";
CM_ SG_ 954 Mem_FS_Lordose_hoch "Anforderung Lordosenwölbung nach oben zu verschieben.";
CM_ SG_ 954 Mem_FS_Lordose_runter "Anforderung Lordosenwölbung nach unten zu verschieben.";
CM_ SG_ 954 Mem_FS_Lordose_vor "Anforderung Lordosenwölbung pneumatisch zu vergrößern.";
CM_ SG_ 954 Mem_FS_Lordose_zurueck "Anforderung Lordosenwölbung zu verkleinern.";
CM_ SG_ 954 Mem_FS_Massage_Geschw "Weiterleitung  der gewünschten Massage Geschwindigkeit";
CM_ SG_ 954 Mem_FS_Massage_Intensitaet "Weiterleitung  der gewünschten Massage Intensität";
CM_ SG_ 954 Mem_FS_Massage_Programm "Weiterleitung  des gewünschten Massageprogramms";
CM_ SG_ 954 Mem_FS_SWangenLehne_beluef "Anforderung Seitenwangen Lehne zu vergrößern.";
CM_ SG_ 954 Mem_FS_SWangenLehne_entlue "Anforderung Seitenwangen Lehne zu verkleinern.";
CM_ SG_ 954 Mem_FS_SWangenSitz_beluef "Anforderung Seitenwangen Sitz zu vergrößern.";
CM_ SG_ 954 Mem_FS_SWangenSitz_entlue "Anforderung Seitenwangen Sitz zu verkleinern.";

CM_ SG_ 956 Mem_FSFo_Business_anfahren "Befehl um Business Position an zufahren";
CM_ SG_ 956 Mem_FSFo_Lordose_hoch "Anforderung Lordosenwölbung nach oben zu verschieben.";
CM_ SG_ 956 Mem_FSFo_Lordose_runter "Anforderung Lordosenwölbung nach unten zu verschieben.";
CM_ SG_ 956 Mem_FSFo_Lordose_vor "Anforderung Lordosenwölbung pneumatisch zu vergrößern.";
CM_ SG_ 956 Mem_FSFo_Lordose_zurueck "Anforderung Lordosenwölbung zu verkleinern.";
CM_ SG_ 956 Mem_FSFo_Massage_Geschw "Weiterleitung  der gewünschten Massage Geschwindigkeit ans IVB und zugleich Anforderungsbestätigung für LEDs am Klima-SG.";
CM_ SG_ 956 Mem_FSFo_Massage_Intens "Weiterleitung  der gewünschten Massage Intensität ans IVB und zugleich Anforderungsbestätigung für LEDs am Klima-SG.";
CM_ SG_ 956 Mem_FSFo_Massage_Prg "Weiterleitung  des gewünschten Massageprogramms ans IVB und zugleich Anforderungsbestätigung für LEDs am Klima-SG.";
CM_ SG_ 956 Mem_FSFo_MMB_glob_Stop "Globaler Abbruch für automatische Funktionen";
CM_ SG_ 956 Mem_FSFo_MMB_lokal_Stop "mit dem lokal Stop moechte man, dass ein Sitz mit Pneumatik - Lordose sich im Memoryfall wie ein Sitz mit elektromechanischer Lordose verhaelt. Nur lokler Abbruch im TIP-Betrieb.";
CM_ SG_ 956 Mem_FSFo_MMB_storage "Angabe der zu speichernden oder einzustellenden Memoryposition";
CM_ SG_ 956 Mem_FSFo_MMB_storage_beep "Quittierungston Sitzmemory  (Anforderung Kombi)";
CM_ SG_ 956 Mem_FSFo_MMB_store "Aufforderung Memory-Position Mem_HL_MMB_store zu speichern";
CM_ SG_ 956 Mem_FSFo_MMB_store_LED_on "LED zur Anzeige der Speicherbereitschaft";
CM_ SG_ 956 Mem_FSFo_MMB_tast "Einstellung der Memoryposition im  Tastbetrieb";
CM_ SG_ 956 Mem_FSFo_MMB_tipp "Einstellung der Memoryposition im  Tippbetrieb";
CM_ SG_ 956 Mem_FSFo_Relax_anfahren "Befehl um Relax Position an zufahren";
CM_ SG_ 956 Mem_FSFo_Sitzfahrt_aktiv "Signalisiert eine aktive Sitzfahrt.";
CM_ SG_ 956 Mem_FSFo_Sitztiefe_vor "Anforderung Sitztiefe nach vorne zu verlängern.";
CM_ SG_ 956 Mem_FSFo_Sitztiefe_zur "Anforderung Sitztiefe nach vorne zu verlängern.";

CM_ SG_ 1180 Mem_Taster_BT_01_BZ "4bit Botschaftszähler, wird in jeder Sendebotschaft inkrementiert";
CM_ SG_ 1180 Mem_Taster_BT_01_CRC "Für MLB:
'Berechnung siehe Lastenheft 'Kommunikationsabsicherung für FlexRay und CAN''

Ab MQB und MLBevo:
'Berechnung siehe Lastenheft 'End-to-End Kommunikationsabsicherung''

Endwerte siehe Begleitdokument 'S-PDU Kennungsfolgen'";
CM_ SG_ 1180 MTBT_M_Taste "Betätigung M-Taste BT";
CM_ SG_ 1180 MTBT_On_Off "Betätigung On-Off Taste BT";
CM_ SG_ 1180 MTBT_Pos1 "Betätigung Postionstaste 1 BT";
CM_ SG_ 1180 MTBT_Pos2 "Betätigung Postionstaste 2 BT";
CM_ SG_ 1180 MTBT_Pos3 "Betätigung Postionstaste 3 BT";
CM_ SG_ 1180 MTBT_Pos4 "Betätigung Postionstaste 4 BT";

CM_ SG_ 1170 Mem_Taster_FT_01_BZ "4bit Botschaftszähler, wird in jeder Sendebotschaft inkrementiert";
CM_ SG_ 1170 Mem_Taster_FT_01_CRC "Für MLB:
'Berechnung siehe Lastenheft 'Kommunikationsabsicherung für FlexRay und CAN''

Ab MQB und MLBevo:
'Berechnung siehe Lastenheft 'End-to-End Kommunikationsabsicherung''

Endwerte siehe Begleitdokument 'S-PDU Kennungsfolgen'";
CM_ SG_ 1170 MTFT_M_Taste "Betätigung M-Taste FT";
CM_ SG_ 1170 MTFT_On_Off "Betätigung On-Off Taste FT";
CM_ SG_ 1170 MTFT_Pos1_EE "Betätigung Postionstaste 1 FT";
CM_ SG_ 1170 MTFT_Pos2 "Betätigung Postionstaste 2 FT";
CM_ SG_ 1170 MTFT_Pos3 "Betätigung Postionstaste 3 FT";
CM_ SG_ 1170 MTFT_Pos4 "Betätigung Postionstaste 4 FT";
CM_ SG_ 1170 MTFT_Verst_akt "Mem Taster Verstellung aktiv";

CM_ SG_ 1173 BFS_Kopfstuetzen_hoch "Kopfstützen hoch (Wird bei Rechtslenker vom TSG HL gesendet)";
CM_ SG_ 1173 BFS_Kopfstuetzen_runter "Kopfstützen runter (Wird bei Rechtslenker vom TSG HL gesendet)";
CM_ SG_ 1173 BFS_Laengsverst_vor "Längsverstellung vor (Wird bei Rechtslenker vom TSG HL gesendet)";
CM_ SG_ 1173 BFS_Laengsverst_zurueck "Längsverstellung zurück (Wird bei Rechtslenker vom TSG HL gesendet)";
CM_ SG_ 1173 BFS_Lehnenkopf_vor "Lehnenkopf vor (Wird bei Rechtslenker vom TSG HL gesendet)";
CM_ SG_ 1173 BFS_Lehnenkopf_zurueck "Lehnenkopf zurück (Wird bei Rechtslenker vom TSG HL gesendet)";
CM_ SG_ 1173 BFS_Lehnenneigung_vor "Lehnenneigung vor (Wird bei Rechtslenker vom TSG HL gesendet)";
CM_ SG_ 1173 BFS_Lehnenneigung_zurueck "Lehnenneigung zurück (Wird bei Rechtslenker vom TSG HL gesendet)";
CM_ SG_ 1173 BFS_Sitzhoehe_hoch "Dient der Sitzhoehenverstellung des Beifahrersitzes aus dem Fond";
CM_ SG_ 1173 BFS_Sitzhoehe_runter "Dient der Sitzhoehenverstellung des Beifahrersitzes aus dem Fond";
CM_ SG_ 1173 MTHBF_BZ "4bit Botschaftszähler, wird in jeder Sendebotschaft inkrementiert
(Wird bei Rechtslenker vom TSG HL gesendet)
";
CM_ SG_ 1173 MTHBF_CRC "Für MLB:
'Berechnung siehe Lastenheft 'Kommunikationsabsicherung für FlexRay und CAN''

Ab MQB und MLBevo:
'Berechnung siehe Lastenheft 'End-to-End Kommunikationsabsicherung''

Endwerte siehe Begleitdokument 'S-PDU Kennungsfolgen'";
CM_ SG_ 1173 MTHBF_ein "Wird bei Rechtslenker vom TSG HL gesendet";
BA_DEF_REL_ BU_SG_REL_  "GenSigTimeoutTime" INT 0 65535;
BA_DEF_ BO_  "DiagRequest" ENUM "No", "Yes";
BA_DEF_ BO_  "DiagResponse" ENUM "No", "Yes";
BA_DEF_ BO_  "DiagState" ENUM "No", "Yes";
BA_DEF_ BO_  "GenMsgChkConstant" HEX 0 4095;
BA_DEF_ BO_  "GenMsgCycleTime" INT 0 65535;
BA_DEF_ BO_  "GenMsgCycleTimeFast" INT 0 65535;
BA_DEF_ BO_  "GenMsgDelayTime" INT 0 100000;
BA_DEF_ BO_  "GenMsgILSupport" ENUM "No", "Yes";
BA_DEF_ BO_  "GenMsgNrOfRepetition" INT 0 100;
BA_DEF_ BO_  "GenMsgPDUConstants" STRING;
BA_DEF_ BO_  "GenMsgSendType" ENUM "Cyclic", "not_used", "not_used", "not_used", "not_used", "not_used", "not_used", "IfActive", "NoMsgSendType";
BA_DEF_ BO_  "GenMsgStartDelayTime" INT 0 100000;
BA_DEF_ BO_  "NmMessage" ENUM "No", "Yes";
BA_DEF_ BO_  "NmhMessage" ENUM "No", "Yes";
BA_DEF_ BO_  "MsgType" ENUM "Application", "NM ", "NMH", "TP2.0", "ISO-TP ", "BAP", "EID", "KS", "XCP_PRE_CONFIGURED", "XCP_RUNTIME_CONFIGURED";
BA_DEF_ BO_  "VAGTP20_API" HEX 0 255;
BA_DEF_ BO_  "VAGTP20_DynConnection" ENUM "No", "Yes";
BA_DEF_ BO_  "VAGTP20_DynSetup" ENUM "No", "Yes";
BA_DEF_ BO_  "VAGTP20_StatConnection" ENUM "No", "Yes";
BA_DEF_ SG_  "GenSigActiveRepetitions" INT -2147483648 2147483647;
BA_DEF_ SG_  "GenSigInactiveValue" INT -2147483648 2147483647;
BA_DEF_ SG_  "GenSigSendType" ENUM "Cyclic", "OnWrite", "OnWriteWithRepetition", "OnChange", "OnChangeWithRepetition", "IfActive", "IfActiveWithRepetition", "NoSigSendType", "OnChangeAndIfActive", "OnChangeAndIfActiveWithRepetition";
BA_DEF_ SG_  "GenSigStartValue" INT -2147483648 2147483647;
BA_DEF_ SG_  "NWM-WakeupAllowed" ENUM "No", "Yes";
BA_DEF_ SG_  "GenSigFuncType" ENUM "NoFunction", "MsgCounter", "CRC-8", "XOR", "XOR-2", "DatedBit", "SW-Kl15", "CHK", "Constant", "Protocol", "CRC-8-SAE_J1850", "CRC-32", "DataLength", "DataID", "MsgCounter16", "SOK-Signatur", "Cluster";
BA_DEF_ SG_  "GenSigSwitchedByIgnition" ENUM "No", "Yes";
BA_DEF_ SG_  "Fehlerwert" HEX 0 2147483647;
BA_DEF_ SG_  "GenSigMissingSourceValue" HEX 0 2147483647;
BA_DEF_DEF_REL_  "GenSigTimeoutTime" 0;
BA_DEF_DEF_  "DiagRequest" "No";
BA_DEF_DEF_  "DiagResponse" "No";
BA_DEF_DEF_  "DiagState" "No";
BA_DEF_DEF_  "GenMsgChkConstant" 0;
BA_DEF_DEF_  "GenMsgCycleTime" 0;
BA_DEF_DEF_  "GenMsgCycleTimeFast" 0;
BA_DEF_DEF_  "GenMsgDelayTime" 0;
BA_DEF_DEF_  "GenMsgILSupport" "No";
BA_DEF_DEF_  "GenMsgNrOfRepetition" 0;
BA_DEF_DEF_  "GenMsgPDUConstants" "";
BA_DEF_DEF_  "GenMsgSendType" "NoMsgSendType";
BA_DEF_DEF_  "GenMsgStartDelayTime" 0;
BA_DEF_DEF_  "NmMessage" "No";
BA_DEF_DEF_  "NmhMessage" "No";
BA_DEF_DEF_  "MsgType" "Application";
BA_DEF_DEF_  "VAGTP20_API" 0;
BA_DEF_DEF_  "VAGTP20_DynConnection" "No";
BA_DEF_DEF_  "VAGTP20_DynSetup" "No";
BA_DEF_DEF_  "VAGTP20_StatConnection" "No";
BA_DEF_DEF_  "GenSigActiveRepetitions" 0;
BA_DEF_DEF_  "GenSigInactiveValue" 0;
BA_DEF_DEF_  "GenSigSendType" "NoSigSendType";
BA_DEF_DEF_  "GenSigStartValue" 0;
BA_DEF_DEF_  "NWM-WakeupAllowed" "No";
BA_DEF_DEF_  "GenSigFuncType" "NoFunction";
BA_DEF_DEF_  "GenSigSwitchedByIgnition" "Yes";
BA_DEF_DEF_  "Fehlerwert" 0;
BA_DEF_DEF_  "GenSigMissingSourceValue" 0;
BA_ "GenMsgCycleTime" BO_ 982 100;
BA_ "GenMsgILSupport" BO_ 982 1;
BA_ "GenMsgPDUConstants" BO_ 982 "0xc5,0x8e,0x64,0x95,0x9e,0xed,0x60,0x45,0x5d,0x8d,0xb2,0x80,0xa1,0x23,0x7d,0x35";
BA_ "GenMsgSendType" BO_ 982 0;
BA_ "GenMsgCycleTime" BO_ 1624 1000;
BA_ "GenMsgDelayTime" BO_ 1624 50;
BA_ "GenMsgILSupport" BO_ 1624 1;
BA_ "GenMsgPDUConstants" BO_ 1624 "0x46,0x0f,0xe0,0xcc,0xbe,0xb1,0xd7,0xf1,0x1f,0x31,0xc1,0x25,0xb4,0x3e,0xc8,0xa3";
BA_ "GenMsgSendType" BO_ 1624 0;
BA_ "GenMsgCycleTime" BO_ 1321 200;
BA_ "GenMsgDelayTime" BO_ 1321 20;
BA_ "GenMsgILSupport" BO_ 1321 1;
BA_ "GenMsgSendType" BO_ 1321 0;
BA_ "GenMsgCycleTime" BO_ 822 120;
BA_ "GenMsgILSupport" BO_ 822 1;
BA_ "GenMsgSendType" BO_ 822 0;
BA_ "GenMsgCycleTime" BO_ 2527679774 500;
BA_ "GenMsgDelayTime" BO_ 2527679774 50;
BA_ "GenMsgILSupport" BO_ 2527679774 1;
BA_ "GenMsgSendType" BO_ 2527679774 0;
BA_ "GenMsgChkConstant" BO_ 134 134;
BA_ "GenMsgCycleTime" BO_ 134 100;
BA_ "GenMsgILSupport" BO_ 134 1;
BA_ "GenMsgPDUConstants" BO_ 134 "0x86,0x86,0x86,0x86,0x86,0x86,0x86,0x86,0x86,0x86,0x86,0x86,0x86,0x86,0x86,0x86";
BA_ "GenMsgSendType" BO_ 134 0;
BA_ "GenMsgCycleTime" BO_ 917 100;
BA_ "GenMsgDelayTime" BO_ 917 10;
BA_ "GenMsgILSupport" BO_ 917 1;
BA_ "GenMsgSendType" BO_ 917 0;
BA_ "GenMsgCycleTime" BO_ 1153 500;
BA_ "GenMsgCycleTimeFast" BO_ 1153 50;
BA_ "GenMsgDelayTime" BO_ 1153 50;
BA_ "GenMsgILSupport" BO_ 1153 1;
BA_ "GenMsgNrOfRepetition" BO_ 1153 5;
BA_ "GenMsgSendType" BO_ 1153 0;
BA_ "GenMsgStartDelayTime" BO_ 1153 10;
BA_ "GenMsgCycleTime" BO_ 2527679771 500;
BA_ "GenMsgDelayTime" BO_ 2527679771 50;
BA_ "GenMsgILSupport" BO_ 2527679771 1;
BA_ "GenMsgPDUConstants" BO_ 2527679771 "0x1a,0xab,0x8f,0xd8,0x5f,0x05,0x58,0x17,0xb0,0x16,0x98,0x76,0x0d,0xc7,0xa4,0xbe";
BA_ "GenMsgSendType" BO_ 2527679771 0;
BA_ "GenMsgCycleTime" BO_ 1639 100;
BA_ "GenMsgDelayTime" BO_ 1639 50;
BA_ "GenMsgILSupport" BO_ 1639 1;
BA_ "GenMsgSendType" BO_ 1639 0;
BA_ "GenMsgCycleTime" BO_ 957 100;
BA_ "GenMsgDelayTime" BO_ 957 50;
BA_ "GenMsgILSupport" BO_ 957 1;
BA_ "GenMsgSendType" BO_ 957 0;
BA_ "GenMsgCycleTime" BO_ 1178 100;
BA_ "GenMsgDelayTime" BO_ 1178 50;
BA_ "GenMsgILSupport" BO_ 1178 1;
BA_ "GenMsgSendType" BO_ 1178 0;
BA_ "GenMsgCycleTime" BO_ 954 100;
BA_ "GenMsgDelayTime" BO_ 954 50;
BA_ "GenMsgILSupport" BO_ 954 1;
BA_ "GenMsgSendType" BO_ 954 0;
BA_ "GenMsgCycleTime" BO_ 956 100;
BA_ "GenMsgDelayTime" BO_ 956 50;
BA_ "GenMsgILSupport" BO_ 956 1;
BA_ "GenMsgSendType" BO_ 956 0;
BA_ "GenMsgChkConstant" BO_ 1180 152;
BA_ "GenMsgCycleTime" BO_ 1180 100;
BA_ "GenMsgCycleTimeFast" BO_ 1180 50;
BA_ "GenMsgDelayTime" BO_ 1180 30;
BA_ "GenMsgILSupport" BO_ 1180 1;
BA_ "GenMsgNrOfRepetition" BO_ 1180 6;
BA_ "GenMsgPDUConstants" BO_ 1180 "0x98,0x98,0x98,0x98,0x98,0x98,0x98,0x98,0x98,0x98,0x98,0x98,0x98,0x98,0x98,0x98";
BA_ "GenMsgSendType" BO_ 1180 0;
BA_ "GenMsgChkConstant" BO_ 1170 150;
BA_ "GenMsgCycleTime" BO_ 1170 100;
BA_ "GenMsgCycleTimeFast" BO_ 1170 50;
BA_ "GenMsgDelayTime" BO_ 1170 30;
BA_ "GenMsgILSupport" BO_ 1170 1;
BA_ "GenMsgNrOfRepetition" BO_ 1170 6;
BA_ "GenMsgPDUConstants" BO_ 1170 "0x96,0x96,0x96,0x96,0x96,0x96,0x96,0x96,0x96,0x96,0x96,0x96,0x96,0x96,0x96,0x96";
BA_ "GenMsgSendType" BO_ 1170 0;
BA_ "GenMsgChkConstant" BO_ 1173 145;
BA_ "GenMsgCycleTime" BO_ 1173 100;
BA_ "GenMsgILSupport" BO_ 1173 1;
BA_ "GenMsgPDUConstants" BO_ 1173 "0x91,0x91,0x91,0x91,0x91,0x91,0x91,0x91,0x91,0x91,0x91,0x91,0x91,0x91,0x91,0x91";
BA_ "GenMsgSendType" BO_ 1173 0;
BA_ "GenSigSendType" SG_ 982 BCM2_Bremsl_durch_ECD 0;
BA_ "GenSigSwitchedByIgnition" SG_ 982 BCM2_Bremsl_durch_ECD 0;
BA_ "GenSigSendType" SG_ 982 LH_3_Bremsl_def 0;
BA_ "GenSigSwitchedByIgnition" SG_ 982 LH_3_Bremsl_def 0;
BA_ "GenSigSendType" SG_ 982 LH_Aussenlicht_def 0;
BA_ "GenSigSwitchedByIgnition" SG_ 982 LH_Aussenlicht_def 0;
BA_ "GenSigSendType" SG_ 982 LH_Blinker_HL_akt 0;
BA_ "GenSigSwitchedByIgnition" SG_ 982 LH_Blinker_HL_akt 0;
BA_ "GenSigSendType" SG_ 982 LH_Blinker_HR_akt 0;
BA_ "GenSigSwitchedByIgnition" SG_ 982 LH_Blinker_HR_akt 0;
BA_ "GenSigSendType" SG_ 982 LH_Blinker_li_def 0;
BA_ "GenSigSwitchedByIgnition" SG_ 982 LH_Blinker_li_def 0;
BA_ "GenSigSendType" SG_ 982 LH_Blinker_re_def 0;
BA_ "GenSigSwitchedByIgnition" SG_ 982 LH_Blinker_re_def 0;
BA_ "GenSigSendType" SG_ 982 LH_Brems_Blk_li_def 0;
BA_ "GenSigSwitchedByIgnition" SG_ 982 LH_Brems_Blk_li_def 0;
BA_ "GenSigSendType" SG_ 982 LH_Brems_Blk_re_def 0;
BA_ "GenSigSwitchedByIgnition" SG_ 982 LH_Brems_Blk_re_def 0;
BA_ "GenSigSendType" SG_ 982 LH_Bremsl_li_def 0;
BA_ "GenSigSwitchedByIgnition" SG_ 982 LH_Bremsl_li_def 0;
BA_ "GenSigSendType" SG_ 982 LH_Bremsl_li_ges_def 0;
BA_ "GenSigSwitchedByIgnition" SG_ 982 LH_Bremsl_li_ges_def 0;
BA_ "GenSigSendType" SG_ 982 LH_Bremsl_mi_def 0;
BA_ "GenSigSwitchedByIgnition" SG_ 982 LH_Bremsl_mi_def 0;
BA_ "GenSigSendType" SG_ 982 LH_Bremsl_re_def 0;
BA_ "GenSigSwitchedByIgnition" SG_ 982 LH_Bremsl_re_def 0;
BA_ "GenSigSendType" SG_ 982 LH_Bremsl_re_ges_def 0;
BA_ "GenSigSwitchedByIgnition" SG_ 982 LH_Bremsl_re_ges_def 0;
BA_ "GenSigSendType" SG_ 982 LH_Bremslicht_H_aktiv 0;
BA_ "GenSigSwitchedByIgnition" SG_ 982 LH_Bremslicht_H_aktiv 0;
BA_ "GenSigSendType" SG_ 982 LH_Diag_LED_li_def 0;
BA_ "GenSigSwitchedByIgnition" SG_ 982 LH_Diag_LED_li_def 0;
BA_ "GenSigSendType" SG_ 982 LH_Diag_LED_re_def 0;
BA_ "GenSigSwitchedByIgnition" SG_ 982 LH_Diag_LED_re_def 0;
BA_ "GenSigSendType" SG_ 982 LH_Diag_Status_li_def 0;
BA_ "GenSigSwitchedByIgnition" SG_ 982 LH_Diag_Status_li_def 0;
BA_ "GenSigSendType" SG_ 982 LH_Diag_Status_re_def 0;
BA_ "GenSigSwitchedByIgnition" SG_ 982 LH_Diag_Status_re_def 0;
BA_ "GenSigSendType" SG_ 982 LH_Kennzl_def 0;
BA_ "GenSigSwitchedByIgnition" SG_ 982 LH_Kennzl_def 0;
BA_ "GenSigSendType" SG_ 982 LH_Nebel_li_def 0;
BA_ "GenSigSwitchedByIgnition" SG_ 982 LH_Nebel_li_def 0;
BA_ "GenSigSendType" SG_ 982 LH_Nebel_mi_def 0;
BA_ "GenSigSwitchedByIgnition" SG_ 982 LH_Nebel_mi_def 0;
BA_ "GenSigSendType" SG_ 982 LH_Nebel_re_def 0;
BA_ "GenSigSwitchedByIgnition" SG_ 982 LH_Nebel_re_def 0;
BA_ "GenSigSendType" SG_ 982 LH_Nebelschluss_aktiv 0;
BA_ "GenSigSwitchedByIgnition" SG_ 982 LH_Nebelschluss_aktiv 0;
BA_ "GenSigSendType" SG_ 982 LH_Parklicht_HL_aktiv 0;
BA_ "GenSigSwitchedByIgnition" SG_ 982 LH_Parklicht_HL_aktiv 0;
BA_ "GenSigSendType" SG_ 982 LH_Parklicht_HR_aktiv 0;
BA_ "GenSigSwitchedByIgnition" SG_ 982 LH_Parklicht_HR_aktiv 0;
BA_ "GenSigSendType" SG_ 982 LH_Rueckf_li_def 0;
BA_ "GenSigSwitchedByIgnition" SG_ 982 LH_Rueckf_li_def 0;
BA_ "GenSigSendType" SG_ 982 LH_Rueckf_mi_def 0;
BA_ "GenSigSwitchedByIgnition" SG_ 982 LH_Rueckf_mi_def 0;
BA_ "GenSigSendType" SG_ 982 LH_Rueckf_re_def 0;
BA_ "GenSigSwitchedByIgnition" SG_ 982 LH_Rueckf_re_def 0;
BA_ "GenSigSendType" SG_ 982 LH_Rueckfahrlicht_aktiv 0;
BA_ "GenSigSwitchedByIgnition" SG_ 982 LH_Rueckfahrlicht_aktiv 0;
BA_ "GenSigSendType" SG_ 982 LH_Schluss_Brems_li_def 0;
BA_ "GenSigSwitchedByIgnition" SG_ 982 LH_Schluss_Brems_li_def 0;
BA_ "GenSigSendType" SG_ 982 LH_Schluss_Brems_mi_def 0;
BA_ "GenSigSwitchedByIgnition" SG_ 982 LH_Schluss_Brems_mi_def 0;
BA_ "GenSigSendType" SG_ 982 LH_Schluss_Brems_Nebel_li_def 0;
BA_ "GenSigSwitchedByIgnition" SG_ 982 LH_Schluss_Brems_Nebel_li_def 0;
BA_ "GenSigSendType" SG_ 982 LH_Schluss_Brems_Nebel_re_def 0;
BA_ "GenSigSwitchedByIgnition" SG_ 982 LH_Schluss_Brems_Nebel_re_def 0;
BA_ "GenSigSendType" SG_ 982 LH_Schluss_Brems_re_def 0;
BA_ "GenSigSwitchedByIgnition" SG_ 982 LH_Schluss_Brems_re_def 0;
BA_ "GenSigSendType" SG_ 982 LH_Schluss_Nebel_li_def 0;
BA_ "GenSigSwitchedByIgnition" SG_ 982 LH_Schluss_Nebel_li_def 0;
BA_ "GenSigSendType" SG_ 982 LH_Schluss_Nebel_re_def 0;
BA_ "GenSigSwitchedByIgnition" SG_ 982 LH_Schluss_Nebel_re_def 0;
BA_ "GenSigSendType" SG_ 982 LH_Schlusslicht_li_def 0;
BA_ "GenSigSwitchedByIgnition" SG_ 982 LH_Schlusslicht_li_def 0;
BA_ "GenSigSendType" SG_ 982 LH_Schlusslicht_mi_def 0;
BA_ "GenSigSwitchedByIgnition" SG_ 982 LH_Schlusslicht_mi_def 0;
BA_ "GenSigSendType" SG_ 982 LH_Schlusslicht_re_def 0;
BA_ "GenSigSwitchedByIgnition" SG_ 982 LH_Schlusslicht_re_def 0;
BA_ "GenSigSendType" SG_ 982 LH_SL_BRL_BLK_li_def 0;
BA_ "GenSigSwitchedByIgnition" SG_ 982 LH_SL_BRL_BLK_li_def 0;
BA_ "GenSigSendType" SG_ 982 LH_SL_BRL_BLK_re_def 0;
BA_ "GenSigSwitchedByIgnition" SG_ 982 LH_SL_BRL_BLK_re_def 0;
BA_ "GenSigSendType" SG_ 982 LH_Standlicht_H_aktiv 0;
BA_ "GenSigSwitchedByIgnition" SG_ 982 LH_Standlicht_H_aktiv 0;
BA_ "GenSigSendType" SG_ 982 LH_Zusatzschlussl_def 0;
BA_ "GenSigSwitchedByIgnition" SG_ 982 LH_Zusatzschlussl_def 0;
BA_ "GenSigSendType" SG_ 1624 BCM1_Licht_Dunkelheit_aktiv 3;
BA_ "GenSigSwitchedByIgnition" SG_ 1624 BCM1_Licht_Dunkelheit_aktiv 0;
BA_ "GenSigSendType" SG_ 1624 BCM1_Linksverkehr 0;
BA_ "GenSigSwitchedByIgnition" SG_ 1624 BCM1_Linksverkehr 0;
BA_ "GenSigSendType" SG_ 1624 Licht_Vorne_01_BZ 0;
BA_ "GenSigFuncType" SG_ 1624 Licht_Vorne_01_BZ 1;
BA_ "GenSigSendType" SG_ 1624 Licht_Vorne_01_CRC 0;
BA_ "GenSigFuncType" SG_ 1624 Licht_Vorne_01_CRC 2;
BA_ "GenSigSendType" SG_ 1624 LV_Abbiegelicht_li_def 0;
BA_ "GenSigSwitchedByIgnition" SG_ 1624 LV_Abbiegelicht_li_def 0;
BA_ "GenSigSendType" SG_ 1624 LV_Abbiegelicht_re_def 0;
BA_ "GenSigSwitchedByIgnition" SG_ 1624 LV_Abbiegelicht_re_def 0;
BA_ "GenSigSendType" SG_ 1624 LV_Abblend_Fernlicht_li_def 0;
BA_ "GenSigSwitchedByIgnition" SG_ 1624 LV_Abblend_Fernlicht_li_def 0;
BA_ "GenSigSendType" SG_ 1624 LV_Abblend_Fernlicht_re_def 0;
BA_ "GenSigSwitchedByIgnition" SG_ 1624 LV_Abblend_Fernlicht_re_def 0;
BA_ "GenSigSendType" SG_ 1624 LV_Abblendlicht_Anzeige 3;
BA_ "GenSigSwitchedByIgnition" SG_ 1624 LV_Abblendlicht_Anzeige 0;
BA_ "GenSigSendType" SG_ 1624 LV_Abblendlicht_li_def 0;
BA_ "GenSigSwitchedByIgnition" SG_ 1624 LV_Abblendlicht_li_def 0;
BA_ "GenSigSendType" SG_ 1624 LV_Abblendlicht_re_def 0;
BA_ "GenSigSwitchedByIgnition" SG_ 1624 LV_Abblendlicht_re_def 0;
BA_ "GenSigSendType" SG_ 1624 LV_Abblendlicht_TFL_li_def 0;
BA_ "GenSigSwitchedByIgnition" SG_ 1624 LV_Abblendlicht_TFL_li_def 0;
BA_ "GenSigSendType" SG_ 1624 LV_Abblendlicht_TFL_re_def 0;
BA_ "GenSigSwitchedByIgnition" SG_ 1624 LV_Abblendlicht_TFL_re_def 0;
BA_ "GenSigSendType" SG_ 1624 LV_AFL_aktiv_Anzeige 3;
BA_ "GenSigSwitchedByIgnition" SG_ 1624 LV_AFL_aktiv_Anzeige 0;
BA_ "GenSigSendType" SG_ 1624 LV_AFL_defekt 3;
BA_ "GenSigSwitchedByIgnition" SG_ 1624 LV_AFL_defekt 0;
BA_ "GenSigSendType" SG_ 1624 LV_Aussenlicht_def 3;
BA_ "GenSigSwitchedByIgnition" SG_ 1624 LV_Aussenlicht_def 0;
BA_ "GenSigSendType" SG_ 1624 LV_Blinker_li_def 3;
BA_ "GenSigSwitchedByIgnition" SG_ 1624 LV_Blinker_li_def 0;
BA_ "GenSigSendType" SG_ 1624 LV_Blinker_re_def 3;
BA_ "GenSigSwitchedByIgnition" SG_ 1624 LV_Blinker_re_def 0;
BA_ "GenSigSendType" SG_ 1624 LV_Blinker_VL_aktiv 3;
BA_ "GenSigSwitchedByIgnition" SG_ 1624 LV_Blinker_VL_aktiv 0;
BA_ "GenSigSendType" SG_ 1624 LV_Blinker_VR_aktiv 3;
BA_ "GenSigSwitchedByIgnition" SG_ 1624 LV_Blinker_VR_aktiv 0;
BA_ "GenSigSendType" SG_ 1624 LV_Blk_li_Seite_def 0;
BA_ "GenSigSwitchedByIgnition" SG_ 1624 LV_Blk_li_Seite_def 0;
BA_ "GenSigSendType" SG_ 1624 LV_Blk_re_Seite_def 0;
BA_ "GenSigSwitchedByIgnition" SG_ 1624 LV_Blk_re_Seite_def 0;
BA_ "GenSigSendType" SG_ 1624 LV_Fernlicht_Anzeige 3;
BA_ "GenSigSwitchedByIgnition" SG_ 1624 LV_Fernlicht_Anzeige 0;
BA_ "GenSigSendType" SG_ 1624 LV_Fernlicht_li_def 0;
BA_ "GenSigSwitchedByIgnition" SG_ 1624 LV_Fernlicht_li_def 0;
BA_ "GenSigSendType" SG_ 1624 LV_Fernlicht_re_def 0;
BA_ "GenSigSwitchedByIgnition" SG_ 1624 LV_Fernlicht_re_def 0;
BA_ "GenSigSendType" SG_ 1624 LV_FLA_aktiv_Anzeige 3;
BA_ "GenSigSwitchedByIgnition" SG_ 1624 LV_FLA_aktiv_Anzeige 0;
BA_ "GenSigSendType" SG_ 1624 LV_FLA_defekt 0;
BA_ "GenSigSwitchedByIgnition" SG_ 1624 LV_FLA_defekt 0;
BA_ "GenSigSendType" SG_ 1624 LV_FLA_Sensor_blockiert 0;
BA_ "GenSigSwitchedByIgnition" SG_ 1624 LV_FLA_Sensor_blockiert 0;
BA_ "GenSigSendType" SG_ 1624 LV_LED_Scheinwerfer_li_def 0;
BA_ "GenSigSwitchedByIgnition" SG_ 1624 LV_LED_Scheinwerfer_li_def 0;
BA_ "GenSigSendType" SG_ 1624 LV_LED_Scheinwerfer_re_def 0;
BA_ "GenSigSwitchedByIgnition" SG_ 1624 LV_LED_Scheinwerfer_re_def 0;
BA_ "GenSigSendType" SG_ 1624 LV_MXB_Status_Anzeige 3;
BA_ "GenSigSwitchedByIgnition" SG_ 1624 LV_MXB_Status_Anzeige 0;
BA_ "GenSigSendType" SG_ 1624 LV_Nebellicht_Anzeige 3;
BA_ "GenSigSwitchedByIgnition" SG_ 1624 LV_Nebellicht_Anzeige 0;
BA_ "GenSigSendType" SG_ 1624 LV_Nebellicht_li_def 0;
BA_ "GenSigSwitchedByIgnition" SG_ 1624 LV_Nebellicht_li_def 0;
BA_ "GenSigSendType" SG_ 1624 LV_Nebellicht_re_def 0;
BA_ "GenSigSwitchedByIgnition" SG_ 1624 LV_Nebellicht_re_def 0;
BA_ "GenSigSendType" SG_ 1624 LV_Nebellicht_TFL_li_def 0;
BA_ "GenSigSwitchedByIgnition" SG_ 1624 LV_Nebellicht_TFL_li_def 0;
BA_ "GenSigSendType" SG_ 1624 LV_Nebellicht_TFL_re_def 0;
BA_ "GenSigSwitchedByIgnition" SG_ 1624 LV_Nebellicht_TFL_re_def 0;
BA_ "GenSigSendType" SG_ 1624 LV_Nebelschlusslicht_Anzeige 3;
BA_ "GenSigSwitchedByIgnition" SG_ 1624 LV_Nebelschlusslicht_Anzeige 0;
BA_ "GenSigSendType" SG_ 1624 LV_Standlicht_Anzeige 3;
BA_ "GenSigSwitchedByIgnition" SG_ 1624 LV_Standlicht_Anzeige 0;
BA_ "GenSigSendType" SG_ 1624 LV_Standlicht_li_def 0;
BA_ "GenSigSwitchedByIgnition" SG_ 1624 LV_Standlicht_li_def 0;
BA_ "GenSigSendType" SG_ 1624 LV_Standlicht_re_def 0;
BA_ "GenSigSwitchedByIgnition" SG_ 1624 LV_Standlicht_re_def 0;
BA_ "GenSigSendType" SG_ 1624 LV_Standlicht_TFL_li_def 0;
BA_ "GenSigSwitchedByIgnition" SG_ 1624 LV_Standlicht_TFL_li_def 0;
BA_ "GenSigSendType" SG_ 1624 LV_Standlicht_TFL_re_def 0;
BA_ "GenSigSwitchedByIgnition" SG_ 1624 LV_Standlicht_TFL_re_def 0;
BA_ "GenSigSendType" SG_ 1624 LV_Tagfahrlicht_Anzeige 3;
BA_ "GenSigSwitchedByIgnition" SG_ 1624 LV_Tagfahrlicht_Anzeige 0;
BA_ "GenSigSendType" SG_ 1624 LV_Tagfahrlicht_li_def 0;
BA_ "GenSigSwitchedByIgnition" SG_ 1624 LV_Tagfahrlicht_li_def 0;
BA_ "GenSigSendType" SG_ 1624 LV_Tagfahrlicht_re_def 0;
BA_ "GenSigSwitchedByIgnition" SG_ 1624 LV_Tagfahrlicht_re_def 0;
BA_ "GenSigSendType" SG_ 1321 Lift_Anforderung_EFP 3;
BA_ "GenSigSwitchedByIgnition" SG_ 1321 Lift_Anforderung_EFP 0;
BA_ "GenSigSendType" SG_ 1321 Lift_Charisma_FahrPr 3;
BA_ "GenSigSwitchedByIgnition" SG_ 1321 Lift_Charisma_FahrPr 0;
BA_ "GenSigSendType" SG_ 1321 Lift_Charisma_Status 3;
BA_ "GenSigSwitchedByIgnition" SG_ 1321 Lift_Charisma_Status 0;
BA_ "GenSigSendType" SG_ 1321 Lift_Charisma_Umschaltung 3;
BA_ "GenSigSwitchedByIgnition" SG_ 1321 Lift_Charisma_Umschaltung 0;
BA_ "GenSigSendType" SG_ 1321 Lift_ESP_Zuschaltung 3;
BA_ "GenSigSwitchedByIgnition" SG_ 1321 Lift_ESP_Zuschaltung 0;
BA_ "GenSigSendType" SG_ 1321 Lift_LED 3;
BA_ "GenSigSwitchedByIgnition" SG_ 1321 Lift_LED 0;
BA_ "Fehlerwert" SG_ 1321 Lift_LED 3;
BA_ "GenSigSendType" SG_ 1321 Lift_Meldung_01 3;
BA_ "GenSigSwitchedByIgnition" SG_ 1321 Lift_Meldung_01 0;
BA_ "GenSigSendType" SG_ 1321 Lift_Meldung_02 3;
BA_ "GenSigSwitchedByIgnition" SG_ 1321 Lift_Meldung_02 0;
BA_ "GenSigSendType" SG_ 1321 Lift_Meldung_03 3;
BA_ "GenSigSwitchedByIgnition" SG_ 1321 Lift_Meldung_03 0;
BA_ "GenSigSendType" SG_ 1321 Lift_Meldung_04 3;
BA_ "GenSigSwitchedByIgnition" SG_ 1321 Lift_Meldung_04 0;
BA_ "GenSigSendType" SG_ 1321 Lift_Meldung_05 3;
BA_ "GenSigSwitchedByIgnition" SG_ 1321 Lift_Meldung_05 0;
BA_ "GenSigSendType" SG_ 1321 Lift_Meldung_06 3;
BA_ "GenSigSwitchedByIgnition" SG_ 1321 Lift_Meldung_06 0;
BA_ "GenSigSendType" SG_ 1321 Lift_Meldung_07 3;
BA_ "GenSigSwitchedByIgnition" SG_ 1321 Lift_Meldung_07 0;
BA_ "GenSigSendType" SG_ 1321 Lift_Meldung_08 3;
BA_ "GenSigSwitchedByIgnition" SG_ 1321 Lift_Meldung_08 0;
BA_ "GenSigSendType" SG_ 1321 Lift_Meldung_09 3;
BA_ "GenSigSwitchedByIgnition" SG_ 1321 Lift_Meldung_09 0;
BA_ "GenSigSendType" SG_ 1321 Lift_Meldung_10 3;
BA_ "GenSigSwitchedByIgnition" SG_ 1321 Lift_Meldung_10 0;
BA_ "GenSigSendType" SG_ 1321 Lift_Meldung_11 3;
BA_ "GenSigSwitchedByIgnition" SG_ 1321 Lift_Meldung_11 0;
BA_ "GenSigSendType" SG_ 1321 Lift_Meldung_12 3;
BA_ "GenSigSwitchedByIgnition" SG_ 1321 Lift_Meldung_12 0;
BA_ "GenSigSendType" SG_ 1321 Lift_Meldung_13 3;
BA_ "GenSigSwitchedByIgnition" SG_ 1321 Lift_Meldung_13 0;
BA_ "GenSigSendType" SG_ 1321 Lift_Meldung_14 3;
BA_ "GenSigSwitchedByIgnition" SG_ 1321 Lift_Meldung_14 0;
BA_ "GenSigSendType" SG_ 1321 Lift_Position 3;
BA_ "GenSigSwitchedByIgnition" SG_ 1321 Lift_Position 0;
BA_ "GenSigSendType" SG_ 1321 Lift_SpannungsAnf 3;
BA_ "GenSigSwitchedByIgnition" SG_ 1321 Lift_SpannungsAnf 0;
BA_ "GenSigSendType" SG_ 1321 Lift_StartStopp_Info 3;
BA_ "GenSigSendType" SG_ 822 LR_HZG_Taster_on_off 0;
BA_ "GenSigSwitchedByIgnition" SG_ 822 LR_HZG_Taster_on_off 0;
BA_ "GenSigSendType" SG_ 822 LR_HZG_Temp_Sensor 0;
BA_ "GenSigStartValue" SG_ 822 LR_HZG_Temp_Sensor 254;
BA_ "GenSigSwitchedByIgnition" SG_ 822 LR_HZG_Temp_Sensor 0;
BA_ "GenSigSendType" SG_ 2527679774 LRM_Auto_Error 3;
BA_ "GenSigSwitchedByIgnition" SG_ 2527679774 LRM_Auto_Error 0;
BA_ "GenSigSendType" SG_ 2527679774 LRM_General_Error 3;
BA_ "GenSigSwitchedByIgnition" SG_ 2527679774 LRM_General_Error 0;
BA_ "GenSigSendType" SG_ 2527679774 LRM_Glass_OC_Error 3;
BA_ "GenSigSwitchedByIgnition" SG_ 2527679774 LRM_Glass_OC_Error 0;
BA_ "GenSigSendType" SG_ 2527679774 LRM_Glass_Rear_OC_Error 3;
BA_ "GenSigSwitchedByIgnition" SG_ 2527679774 LRM_Glass_Rear_OC_Error 0;
BA_ "GenSigSendType" SG_ 2527679774 LRM_Glass_Rear_SC_Error 3;
BA_ "GenSigSwitchedByIgnition" SG_ 2527679774 LRM_Glass_Rear_SC_Error 0;
BA_ "GenSigSendType" SG_ 2527679774 LRM_Glass_SC_Error 3;
BA_ "GenSigSwitchedByIgnition" SG_ 2527679774 LRM_Glass_SC_Error 0;
BA_ "GenSigSendType" SG_ 2527679774 LRM_Level 3;
BA_ "GenSigStartValue" SG_ 2527679774 LRM_Level 6;
BA_ "GenSigSwitchedByIgnition" SG_ 2527679774 LRM_Level 0;
BA_ "Fehlerwert" SG_ 2527679774 LRM_Level 7;
BA_ "GenSigSendType" SG_ 2527679774 LRM_Level_Rear 3;
BA_ "GenSigStartValue" SG_ 2527679774 LRM_Level_Rear 6;
BA_ "GenSigSwitchedByIgnition" SG_ 2527679774 LRM_Level_Rear 0;
BA_ "Fehlerwert" SG_ 2527679774 LRM_Level_Rear 7;
BA_ "GenSigSendType" SG_ 2527679774 LRM_Manual_Error 3;
BA_ "GenSigSwitchedByIgnition" SG_ 2527679774 LRM_Manual_Error 0;
BA_ "GenSigSendType" SG_ 2527679774 LRM_Mode 3;
BA_ "GenSigStartValue" SG_ 2527679774 LRM_Mode 6;
BA_ "GenSigSwitchedByIgnition" SG_ 2527679774 LRM_Mode 0;
BA_ "Fehlerwert" SG_ 2527679774 LRM_Mode 7;
BA_ "GenSigSendType" SG_ 134 LWI_01_BZ 0;
BA_ "GenSigFuncType" SG_ 134 LWI_01_BZ 1;
BA_ "GenSigSendType" SG_ 134 LWI_01_CRC 0;
BA_ "GenSigFuncType" SG_ 134 LWI_01_CRC 2;
BA_ "GenSigSwitchedByIgnition" SG_ 134 LWI_01_CRC 0;
BA_ "GenSigSendType" SG_ 134 LWI_Lenkradw_Geschw 0;
BA_ "GenSigStartValue" SG_ 134 LWI_Lenkradw_Geschw 510;
BA_ "Fehlerwert" SG_ 134 LWI_Lenkradw_Geschw 511;
BA_ "GenSigSendType" SG_ 134 LWI_Lenkradwinkel 0;
BA_ "GenSigStartValue" SG_ 134 LWI_Lenkradwinkel 8190;
BA_ "Fehlerwert" SG_ 134 LWI_Lenkradwinkel 8191;
BA_ "GenSigSendType" SG_ 134 LWI_MFL_Abschaltung 0;
BA_ "GenSigSwitchedByIgnition" SG_ 134 LWI_MFL_Abschaltung 0;
BA_ "GenSigSendType" SG_ 134 LWI_QBit_Lenkradwinkel 0;
BA_ "GenSigStartValue" SG_ 134 LWI_QBit_Lenkradwinkel 1;
BA_ "GenSigSendType" SG_ 134 LWI_QBit_Sub_Daten 0;
BA_ "GenSigSendType" SG_ 134 LWI_Sensorstatus 0;
BA_ "GenSigSendType" SG_ 134 LWI_Sub_Daten 0;
BA_ "GenSigSendType" SG_ 134 LWI_VZ_Lenkradw_Geschw 0;
BA_ "GenSigSendType" SG_ 134 LWI_VZ_Lenkradwinkel 0;
BA_ "GenSigSendType" SG_ 917 AFS_Abbiegelicht_Dimm_Anf 0;
BA_ "GenSigSendType" SG_ 917 AFS_Abbiegelicht_li_Anf 0;
BA_ "GenSigSendType" SG_ 917 AFS_Abbiegelicht_re_Anf 0;
BA_ "GenSigSendType" SG_ 917 AFS_adaptive_LV_verbaut 0;
BA_ "GenSigSendType" SG_ 917 AFS_Allwetterlicht 0;
BA_ "GenSigSendType" SG_ 917 AFS_Charisma_FahrPr 0;
BA_ "GenSigSendType" SG_ 917 AFS_Charisma_Status 0;
BA_ "GenSigSendType" SG_ 917 AFS_Charisma_Umschaltung 3;
BA_ "GenSigSendType" SG_ 917 AFS_Ersatzlicht_Links 0;
BA_ "GenSigSendType" SG_ 917 AFS_Ersatzlicht_Rechts 0;
BA_ "GenSigSendType" SG_ 917 AFS_Fehlertext 0;
BA_ "GenSigSendType" SG_ 917 AFS_Fernlicht_li_defekt 0;
BA_ "GenSigSendType" SG_ 917 AFS_Fernlicht_re_defekt 0;
BA_ "GenSigSendType" SG_ 917 AFS_Fernlicht_Status 3;
BA_ "GenSigSendType" SG_ 917 AFS_Lampe 0;
BA_ "GenSigSendType" SG_ 917 AFS_LED_Blinkmode 0;
BA_ "GenSigSendType" SG_ 917 AFS_Status_adaptive_LV 0;
BA_ "GenSigStartValue" SG_ 917 AFS_Status_adaptive_LV 1;
BA_ "GenSigSendType" SG_ 917 AFS_Verfuegbarkeit_GLW 0;
BA_ "GenSigStartValue" SG_ 917 AFS_Verfuegbarkeit_GLW 1;
BA_ "GenSigSendType" SG_ 917 GLW_Sensor_blockiert 0;
BA_ "GenSigSendType" SG_ 917 LWR_AFS_01_BZ 0;
BA_ "GenSigFuncType" SG_ 917 LWR_AFS_01_BZ 1;
BA_ "GenSigSendType" SG_ 917 LWR_AFS_Grundeinstellung 0;
BA_ "GenSigSendType" SG_ 917 LWR_AFS_Parametrisierung 0;
BA_ "GenSigSendType" SG_ 917 LWR_Hoehenwert_HL 0;
BA_ "GenSigStartValue" SG_ 917 LWR_Hoehenwert_HL 254;
BA_ "Fehlerwert" SG_ 917 LWR_Hoehenwert_HL 255;
BA_ "GenSigSendType" SG_ 917 LWR_Hoehenwert_VL 0;
BA_ "GenSigStartValue" SG_ 917 LWR_Hoehenwert_VL 254;
BA_ "Fehlerwert" SG_ 917 LWR_Hoehenwert_VL 255;
BA_ "GenSigSendType" SG_ 917 LWR_Initialisierungslauf 0;
BA_ "GenSigSendType" SG_ 917 LWR_Lampe 0;
BA_ "GenSigSendType" SG_ 917 LWR_Modus 0;
BA_ "GenSigSendType" SG_ 917 LWR_Pos_Schrittmotor 0;
BA_ "GenSigStartValue" SG_ 917 LWR_Pos_Schrittmotor 254;
BA_ "Fehlerwert" SG_ 917 LWR_Pos_Schrittmotor 255;
BA_ "GenSigSendType" SG_ 917 LWR_Reisemodus_Texte 0;
BA_ "GenSigSendType" SG_ 917 LWR_Sicherheitsposition_li 0;
BA_ "GenSigSendType" SG_ 917 LWR_Sicherheitsposition_re 0;
BA_ "GenSigSendType" SG_ 917 LWR_Touristenmodus_aktiv 0;
BA_ "GenSigSendType" SG_ 917 LWR_Touristenmodus_verbaut 0;
BA_ "GenSigSendType" SG_ 1153 DSSS_Warning 3;
BA_ "GenSigSwitchedByIgnition" SG_ 1153 DSSS_Warning 0;
BA_ "GenSigSendType" SG_ 1153 MIB_Tongenerator_PH_verfuegbar 3;
BA_ "GenSigSwitchedByIgnition" SG_ 1153 MIB_Tongenerator_PH_verfuegbar 0;
BA_ "GenSigSendType" SG_ 1153 MMI_Counter_Bedienevent 0;
BA_ "GenSigSwitchedByIgnition" SG_ 1153 MMI_Counter_Bedienevent 0;
BA_ "GenSigSendType" SG_ 1153 MMI_Gauges_active 3;
BA_ "GenSigSwitchedByIgnition" SG_ 1153 MMI_Gauges_active 0;
BA_ "GenSigSendType" SG_ 1153 MMI_Gurt_Mic_ref 0;
BA_ "GenSigSwitchedByIgnition" SG_ 1153 MMI_Gurt_Mic_ref 0;
BA_ "GenSigSendType" SG_ 1153 MMI_SDS_aktiv 3;
BA_ "GenSigSwitchedByIgnition" SG_ 1153 MMI_SDS_aktiv 0;
BA_ "GenSigSendType" SG_ 1153 MMI_StartStopp_Info 3;
BA_ "GenSigSwitchedByIgnition" SG_ 1153 MMI_StartStopp_Info 0;
BA_ "Fehlerwert" SG_ 1153 MMI_StartStopp_Info 3;
BA_ "GenSigSendType" SG_ 1153 MMI_Telefon_aktiv 3;
BA_ "GenSigSwitchedByIgnition" SG_ 1153 MMI_Telefon_aktiv 0;
BA_ "GenSigSendType" SG_ 1153 MU_SecondDisplay 3;
BA_ "GenSigSwitchedByIgnition" SG_ 1153 MU_SecondDisplay 0;
BA_ "GenSigSendType" SG_ 1153 MU_Update_Time 0;
BA_ "GenSigSwitchedByIgnition" SG_ 1153 MU_Update_Time 0;
BA_ "GenSigSendType" SG_ 1153 Nav_FoD_Status 3;
BA_ "GenSigSwitchedByIgnition" SG_ 1153 Nav_FoD_Status 0;
BA_ "GenSigSendType" SG_ 1153 ZR_Kindersicherung_RSE 3;
BA_ "GenSigSwitchedByIgnition" SG_ 1153 ZR_Kindersicherung_RSE 0;
BA_ "GenSigSendType" SG_ 1153 ZR_LAPP_Sondermodus_Status 3;
BA_ "GenSigSendType" SG_ 1153 ZR_LoGeWa_Event_Kombiwarnung 3;
BA_ "GenSigSwitchedByIgnition" SG_ 1153 ZR_LoGeWa_Event_Kombiwarnung 0;
BA_ "GenSigSendType" SG_ 1153 ZR_MXB_Manoever_Ansage 3;
BA_ "GenSigSwitchedByIgnition" SG_ 1153 ZR_MXB_Manoever_Ansage 0;
BA_ "GenSigSendType" SG_ 1153 ZR_Parken_Sondermodus 3;
BA_ "GenSigSwitchedByIgnition" SG_ 1153 ZR_Parken_Sondermodus 0;
BA_ "GenSigSendType" SG_ 1153 ZR_RSE_aktivieren 3;
BA_ "GenSigSwitchedByIgnition" SG_ 1153 ZR_RSE_aktivieren 0;
BA_ "GenSigSendType" SG_ 1153 ZR_Rundenbewertung 3;
BA_ "GenSigStartValue" SG_ 1153 ZR_Rundenbewertung 14;
BA_ "GenSigSwitchedByIgnition" SG_ 1153 ZR_Rundenbewertung 0;
BA_ "GenSigSendType" SG_ 1153 ZR_Rundenfortschritt 3;
BA_ "GenSigStartValue" SG_ 1153 ZR_Rundenfortschritt 254;
BA_ "GenSigSwitchedByIgnition" SG_ 1153 ZR_Rundenfortschritt 0;
BA_ "GenSigActiveRepetitions" SG_ 1153 ZR_Sta_Inszenierung 5;
BA_ "GenSigSendType" SG_ 1153 ZR_Sta_Inszenierung 4;
BA_ "GenSigSwitchedByIgnition" SG_ 1153 ZR_Sta_Inszenierung 0;
BA_ "GenSigSendType" SG_ 2527679771 LIMU_Aero_Selec_HMI_Anf 3;
BA_ "GenSigSwitchedByIgnition" SG_ 2527679771 LIMU_Aero_Selec_HMI_Anf 0;
BA_ "GenSigSendType" SG_ 2527679771 LIMU_BAR_Mode_Switch_HMI_Anf 3;
BA_ "GenSigSwitchedByIgnition" SG_ 2527679771 LIMU_BAR_Mode_Switch_HMI_Anf 0;
BA_ "GenSigSendType" SG_ 2527679771 LIMU_Confirmation_HMI_Anf 3;
BA_ "GenSigSwitchedByIgnition" SG_ 2527679771 LIMU_Confirmation_HMI_Anf 0;
BA_ "GenSigSendType" SG_ 2527679771 LIMU_DR_Select_HMI_Anf 3;
BA_ "GenSigSwitchedByIgnition" SG_ 2527679771 LIMU_DR_Select_HMI_Anf 0;
BA_ "GenSigSendType" SG_ 2527679771 LIMU_Reset_switch_HMI_Anf 3;
BA_ "GenSigSwitchedByIgnition" SG_ 2527679771 LIMU_Reset_switch_HMI_Anf 0;
BA_ "GenSigSendType" SG_ 2527679771 MainUnit_02_BZ 0;
BA_ "GenSigFuncType" SG_ 2527679771 MainUnit_02_BZ 1;
BA_ "GenSigSwitchedByIgnition" SG_ 2527679771 MainUnit_02_BZ 0;
BA_ "GenSigSendType" SG_ 2527679771 MainUnit_02_CRC 0;
BA_ "GenSigFuncType" SG_ 2527679771 MainUnit_02_CRC 2;
BA_ "GenSigSwitchedByIgnition" SG_ 2527679771 MainUnit_02_CRC 0;
BA_ "GenSigSendType" SG_ 2527679771 ZR_ECR_LevelMode_HMI_Anf 3;
BA_ "GenSigSwitchedByIgnition" SG_ 2527679771 ZR_ECR_LevelMode_HMI_Anf 0;
BA_ "Fehlerwert" SG_ 2527679771 ZR_ECR_LevelMode_HMI_Anf 7;
BA_ "GenSigSendType" SG_ 2527679771 ZR_ECR_SwitchMode_HMI_Anf 3;
BA_ "GenSigStartValue" SG_ 2527679771 ZR_ECR_SwitchMode_HMI_Anf 3;
BA_ "GenSigSwitchedByIgnition" SG_ 2527679771 ZR_ECR_SwitchMode_HMI_Anf 0;
BA_ "Fehlerwert" SG_ 2527679771 ZR_ECR_SwitchMode_HMI_Anf 7;
BA_ "GenSigSendType" SG_ 2527679771 ZR_Slider_soll_01 3;
BA_ "GenSigStartValue" SG_ 2527679771 ZR_Slider_soll_01 127;
BA_ "GenSigSwitchedByIgnition" SG_ 2527679771 ZR_Slider_soll_01 0;
BA_ "GenSigSendType" SG_ 2527679771 ZR_Slider_soll_02 3;
BA_ "GenSigStartValue" SG_ 2527679771 ZR_Slider_soll_02 127;
BA_ "GenSigSwitchedByIgnition" SG_ 2527679771 ZR_Slider_soll_02 0;
BA_ "GenSigSendType" SG_ 2527679771 ZR_Slider_soll_03 3;
BA_ "GenSigStartValue" SG_ 2527679771 ZR_Slider_soll_03 127;
BA_ "GenSigSwitchedByIgnition" SG_ 2527679771 ZR_Slider_soll_03 0;
BA_ "GenSigSendType" SG_ 1639 BFS_Fond_Bed_Ack 3;
BA_ "GenSigSwitchedByIgnition" SG_ 1639 BFS_Fond_Bed_Ack 0;
BA_ "GenSigSendType" SG_ 1639 BFS_FSV_ausgeklappt 0;
BA_ "GenSigSwitchedByIgnition" SG_ 1639 BFS_FSV_ausgeklappt 0;
BA_ "GenSigSendType" SG_ 1639 BFS_GHV_aktiv 3;
BA_ "GenSigSwitchedByIgnition" SG_ 1639 BFS_GHV_aktiv 0;
BA_ "GenSigSendType" SG_ 1639 BFS_Gurtbringer_Sperre 0;
BA_ "GenSigSwitchedByIgnition" SG_ 1639 BFS_Gurtbringer_Sperre 0;
BA_ "GenSigSendType" SG_ 1639 BFS_Klapptisch_offen 3;
BA_ "GenSigSwitchedByIgnition" SG_ 1639 BFS_Klapptisch_offen 0;
BA_ "GenSigSendType" SG_ 1639 BFS_Kollisionsbereich_Windschott 3;
BA_ "GenSigSwitchedByIgnition" SG_ 1639 BFS_Kollisionsbereich_Windschott 0;
BA_ "GenSigSendType" SG_ 1639 BFS_Kollisionsgefahr_Windschott 3;
BA_ "GenSigSwitchedByIgnition" SG_ 1639 BFS_Kollisionsgefahr_Windschott 0;
BA_ "GenSigSendType" SG_ 1639 BFS_KSS_Fahrt_aktiv 3;
BA_ "GenSigSwitchedByIgnition" SG_ 1639 BFS_KSS_Fahrt_aktiv 0;
BA_ "GenSigSendType" SG_ 1639 BFS_KSV_aktiv 3;
BA_ "GenSigSwitchedByIgnition" SG_ 1639 BFS_KSV_aktiv 0;
BA_ "GenSigSendType" SG_ 1639 BFS_Lehne_nicht_verriegelt 3;
BA_ "GenSigSwitchedByIgnition" SG_ 1639 BFS_Lehne_nicht_verriegelt 0;
BA_ "GenSigSendType" SG_ 1639 BFS_LHV_aktiv 3;
BA_ "GenSigSwitchedByIgnition" SG_ 1639 BFS_LHV_aktiv 0;
BA_ "GenSigSendType" SG_ 1639 BFS_LKV_aktiv 3;
BA_ "GenSigSwitchedByIgnition" SG_ 1639 BFS_LKV_aktiv 0;
BA_ "GenSigSendType" SG_ 1639 BFS_LNV_aktiv 3;
BA_ "GenSigSwitchedByIgnition" SG_ 1639 BFS_LNV_aktiv 0;
BA_ "GenSigSendType" SG_ 1639 BFS_LWV_aktiv 3;
BA_ "GenSigSwitchedByIgnition" SG_ 1639 BFS_LWV_aktiv 0;
BA_ "GenSigSendType" SG_ 1639 BFS_MMB_glob_stop 3;
BA_ "GenSigSwitchedByIgnition" SG_ 1639 BFS_MMB_glob_stop 0;
BA_ "GenSigSendType" SG_ 1639 BFS_MMB_lokal_Stop 3;
BA_ "GenSigSwitchedByIgnition" SG_ 1639 BFS_MMB_lokal_Stop 0;
BA_ "GenSigSendType" SG_ 1639 BFS_MMB_storage 3;
BA_ "GenSigSwitchedByIgnition" SG_ 1639 BFS_MMB_storage 0;
BA_ "GenSigSendType" SG_ 1639 BFS_MMB_storage_beep 3;
BA_ "GenSigSwitchedByIgnition" SG_ 1639 BFS_MMB_storage_beep 0;
BA_ "GenSigSendType" SG_ 1639 BFS_MMB_store 3;
BA_ "GenSigSwitchedByIgnition" SG_ 1639 BFS_MMB_store 0;
BA_ "GenSigSendType" SG_ 1639 BFS_MMB_store_LED_on 3;
BA_ "GenSigSwitchedByIgnition" SG_ 1639 BFS_MMB_store_LED_on 0;
BA_ "GenSigSendType" SG_ 1639 BFS_MMB_tast 3;
BA_ "GenSigSwitchedByIgnition" SG_ 1639 BFS_MMB_tast 0;
BA_ "GenSigSendType" SG_ 1639 BFS_MMB_tipp 3;
BA_ "GenSigSwitchedByIgnition" SG_ 1639 BFS_MMB_tipp 0;
BA_ "GenSigSendType" SG_ 1639 BFS_NFA_einfahren 3;
BA_ "GenSigSwitchedByIgnition" SG_ 1639 BFS_NFA_einfahren 0;
BA_ "GenSigSendType" SG_ 1639 BFS_Ruhestellung_Status 3;
BA_ "GenSigSwitchedByIgnition" SG_ 1639 BFS_Ruhestellung_Status 0;
BA_ "GenSigSendType" SG_ 1639 BFS_Seat_Locked 0;
BA_ "GenSigSwitchedByIgnition" SG_ 1639 BFS_Seat_Locked 0;
BA_ "GenSigSendType" SG_ 1639 BFS_SHV_aktiv 3;
BA_ "GenSigSwitchedByIgnition" SG_ 1639 BFS_SHV_aktiv 0;
BA_ "GenSigSendType" SG_ 1639 BFS_Sitzfahrt_aktiv 3;
BA_ "GenSigSwitchedByIgnition" SG_ 1639 BFS_Sitzfahrt_aktiv 0;
BA_ "GenSigSendType" SG_ 1639 BFS_Sitzsym_Fahrt_aktiv 3;
BA_ "GenSigSwitchedByIgnition" SG_ 1639 BFS_Sitzsym_Fahrt_aktiv 0;
BA_ "GenSigSendType" SG_ 1639 BFS_SLV_aktiv 3;
BA_ "GenSigSwitchedByIgnition" SG_ 1639 BFS_SLV_aktiv 0;
BA_ "GenSigSendType" SG_ 1639 BFS_SNV_aktiv 3;
BA_ "GenSigSwitchedByIgnition" SG_ 1639 BFS_SNV_aktiv 0;
BA_ "GenSigSendType" SG_ 1639 BFS_STV_aktiv 3;
BA_ "GenSigSwitchedByIgnition" SG_ 1639 BFS_STV_aktiv 0;
BA_ "GenSigSendType" SG_ 957 BFS_Kopfstuetze_vor 0;
BA_ "GenSigSwitchedByIgnition" SG_ 957 BFS_Kopfstuetze_vor 0;
BA_ "GenSigSendType" SG_ 957 BFS_Kopfstuetze_zurueck 0;
BA_ "GenSigSwitchedByIgnition" SG_ 957 BFS_Kopfstuetze_zurueck 0;
BA_ "GenSigSendType" SG_ 957 Fernsteuerung_BFS_LED 0;
BA_ "GenSigSwitchedByIgnition" SG_ 957 Fernsteuerung_BFS_LED 0;
BA_ "GenSigSendType" SG_ 957 Fernsteuerung_Massage_LED 0;
BA_ "GenSigSwitchedByIgnition" SG_ 957 Fernsteuerung_Massage_LED 0;
BA_ "GenSigSendType" SG_ 957 Mem_BFS_Spezialpos_loeschen 3;
BA_ "GenSigSwitchedByIgnition" SG_ 957 Mem_BFS_Spezialpos_loeschen 0;
BA_ "GenSigSendType" SG_ 957 Mem_BFSFo_BeifaSitzverstellung 3;
BA_ "GenSigSwitchedByIgnition" SG_ 957 Mem_BFSFo_BeifaSitzverstellung 0;
BA_ "GenSigSendType" SG_ 957 Mem_BFSFo_BFS_Freigabe 3;
BA_ "GenSigSwitchedByIgnition" SG_ 957 Mem_BFSFo_BFS_Freigabe 0;
BA_ "GenSigSendType" SG_ 957 Mem_BFSFo_BFS_RSE_Freigabe 3;
BA_ "GenSigSwitchedByIgnition" SG_ 957 Mem_BFSFo_BFS_RSE_Freigabe 0;
BA_ "GenSigSendType" SG_ 957 Mem_BFSFo_Business_anfahren 3;
BA_ "GenSigSwitchedByIgnition" SG_ 957 Mem_BFSFo_Business_anfahren 0;
BA_ "GenSigSendType" SG_ 957 Mem_BFSFo_Fusstuetze_hoch 3;
BA_ "GenSigSwitchedByIgnition" SG_ 957 Mem_BFSFo_Fusstuetze_hoch 0;
BA_ "GenSigSendType" SG_ 957 Mem_BFSFo_Fusstuetze_runter 3;
BA_ "GenSigSwitchedByIgnition" SG_ 957 Mem_BFSFo_Fusstuetze_runter 0;
BA_ "GenSigSendType" SG_ 957 Mem_BFSFo_Lordose_hoch 3;
BA_ "GenSigSwitchedByIgnition" SG_ 957 Mem_BFSFo_Lordose_hoch 0;
BA_ "GenSigSendType" SG_ 957 Mem_BFSFo_Lordose_runter 3;
BA_ "GenSigSwitchedByIgnition" SG_ 957 Mem_BFSFo_Lordose_runter 0;
BA_ "GenSigSendType" SG_ 957 Mem_BFSFo_Lordose_vor 3;
BA_ "GenSigSwitchedByIgnition" SG_ 957 Mem_BFSFo_Lordose_vor 0;
BA_ "GenSigSendType" SG_ 957 Mem_BFSFo_Lordose_zurueck 3;
BA_ "GenSigSwitchedByIgnition" SG_ 957 Mem_BFSFo_Lordose_zurueck 0;
BA_ "GenSigSendType" SG_ 957 Mem_BFSFo_Massage_Geschw 3;
BA_ "GenSigSwitchedByIgnition" SG_ 957 Mem_BFSFo_Massage_Geschw 0;
BA_ "GenSigSendType" SG_ 957 Mem_BFSFo_Massage_Intens 3;
BA_ "GenSigSwitchedByIgnition" SG_ 957 Mem_BFSFo_Massage_Intens 0;
BA_ "GenSigSendType" SG_ 957 Mem_BFSFo_Massage_Prg 3;
BA_ "GenSigSwitchedByIgnition" SG_ 957 Mem_BFSFo_Massage_Prg 0;
BA_ "GenSigSendType" SG_ 957 Mem_BFSFo_MMB_glob_Stop 3;
BA_ "GenSigSwitchedByIgnition" SG_ 957 Mem_BFSFo_MMB_glob_Stop 0;
BA_ "GenSigSendType" SG_ 957 Mem_BFSFo_MMB_lokal_Stop 3;
BA_ "GenSigSwitchedByIgnition" SG_ 957 Mem_BFSFo_MMB_lokal_Stop 0;
BA_ "GenSigSendType" SG_ 957 Mem_BFSFo_MMB_storage 3;
BA_ "GenSigSwitchedByIgnition" SG_ 957 Mem_BFSFo_MMB_storage 0;
BA_ "GenSigSendType" SG_ 957 Mem_BFSFo_MMB_storage_beep 3;
BA_ "GenSigSwitchedByIgnition" SG_ 957 Mem_BFSFo_MMB_storage_beep 0;
BA_ "GenSigSendType" SG_ 957 Mem_BFSFo_MMB_store 3;
BA_ "GenSigSwitchedByIgnition" SG_ 957 Mem_BFSFo_MMB_store 0;
BA_ "GenSigSendType" SG_ 957 Mem_BFSFo_MMB_store_LED_on 3;
BA_ "GenSigSwitchedByIgnition" SG_ 957 Mem_BFSFo_MMB_store_LED_on 0;
BA_ "GenSigSendType" SG_ 957 Mem_BFSFo_MMB_tast 3;
BA_ "GenSigSwitchedByIgnition" SG_ 957 Mem_BFSFo_MMB_tast 0;
BA_ "GenSigSendType" SG_ 957 Mem_BFSFo_MMB_tipp 3;
BA_ "GenSigSwitchedByIgnition" SG_ 957 Mem_BFSFo_MMB_tipp 0;
BA_ "GenSigSendType" SG_ 957 Mem_BFSFo_NFA_aufgestellt 3;
BA_ "GenSigSwitchedByIgnition" SG_ 957 Mem_BFSFo_NFA_aufgestellt 0;
BA_ "GenSigSendType" SG_ 957 Mem_BFSFo_Relax_anfahren 3;
BA_ "GenSigSwitchedByIgnition" SG_ 957 Mem_BFSFo_Relax_anfahren 0;
BA_ "GenSigSendType" SG_ 957 Mem_BFSFo_RSE_vor 3;
BA_ "GenSigSwitchedByIgnition" SG_ 957 Mem_BFSFo_RSE_vor 0;
BA_ "GenSigSendType" SG_ 957 Mem_BFSFo_RSE_zurueck 3;
BA_ "GenSigSwitchedByIgnition" SG_ 957 Mem_BFSFo_RSE_zurueck 0;
BA_ "GenSigSendType" SG_ 957 Mem_BFSFo_Sitzfahrt_aktiv 3;
BA_ "GenSigSwitchedByIgnition" SG_ 957 Mem_BFSFo_Sitzfahrt_aktiv 0;
BA_ "GenSigSendType" SG_ 957 Mem_BFSFo_Sitztiefe_vor 3;
BA_ "GenSigSwitchedByIgnition" SG_ 957 Mem_BFSFo_Sitztiefe_vor 0;
BA_ "GenSigSendType" SG_ 957 Mem_BFSFo_Sitztiefe_zur 3;
BA_ "GenSigSwitchedByIgnition" SG_ 957 Mem_BFSFo_Sitztiefe_zur 0;
BA_ "GenSigSendType" SG_ 1178 FS_BFS_Fond_Verst_enable 3;
BA_ "GenSigSwitchedByIgnition" SG_ 1178 FS_BFS_Fond_Verst_enable 0;
BA_ "GenSigSendType" SG_ 1178 FS_BFS_KSS_Anfahrt 3;
BA_ "GenSigSwitchedByIgnition" SG_ 1178 FS_BFS_KSS_Anfahrt 0;
BA_ "GenSigSendType" SG_ 1178 FS_BFS_Sitzsym_Anfahrt 3;
BA_ "GenSigSwitchedByIgnition" SG_ 1178 FS_BFS_Sitzsym_Anfahrt 0;
BA_ "GenSigSendType" SG_ 1178 FS_EE_BFS_enable 3;
BA_ "GenSigSwitchedByIgnition" SG_ 1178 FS_EE_BFS_enable 0;
BA_ "GenSigSendType" SG_ 1178 FS_EE_Fond_BFS_enable 3;
BA_ "GenSigSwitchedByIgnition" SG_ 1178 FS_EE_Fond_BFS_enable 0;
BA_ "GenSigSendType" SG_ 1178 FS_EE_Fond_FS_enable 3;
BA_ "GenSigSwitchedByIgnition" SG_ 1178 FS_EE_Fond_FS_enable 0;
BA_ "GenSigSendType" SG_ 1178 FS_Fond_Bed_enable 3;
BA_ "GenSigSwitchedByIgnition" SG_ 1178 FS_Fond_Bed_enable 0;
BA_ "GenSigSendType" SG_ 1178 FS_GHV_aktiv 3;
BA_ "GenSigSwitchedByIgnition" SG_ 1178 FS_GHV_aktiv 0;
BA_ "GenSigSendType" SG_ 1178 FS_Gurtbringer_Sperre 0;
BA_ "GenSigSwitchedByIgnition" SG_ 1178 FS_Gurtbringer_Sperre 0;
BA_ "GenSigSendType" SG_ 1178 FS_Kollisionsbereich_Windschott 3;
BA_ "GenSigSwitchedByIgnition" SG_ 1178 FS_Kollisionsbereich_Windschott 0;
BA_ "GenSigSendType" SG_ 1178 FS_Kollisionsgefahr_Windschott 3;
BA_ "GenSigSwitchedByIgnition" SG_ 1178 FS_Kollisionsgefahr_Windschott 0;
BA_ "GenSigSendType" SG_ 1178 FS_KSV_aktiv 3;
BA_ "GenSigSwitchedByIgnition" SG_ 1178 FS_KSV_aktiv 0;
BA_ "GenSigSendType" SG_ 1178 FS_Lehne_nicht_verriegelt 3;
BA_ "GenSigSwitchedByIgnition" SG_ 1178 FS_Lehne_nicht_verriegelt 0;
BA_ "GenSigSendType" SG_ 1178 FS_LHV_aktiv 3;
BA_ "GenSigSwitchedByIgnition" SG_ 1178 FS_LHV_aktiv 0;
BA_ "GenSigSendType" SG_ 1178 FS_LKV_aktiv 3;
BA_ "GenSigSwitchedByIgnition" SG_ 1178 FS_LKV_aktiv 0;
BA_ "GenSigSendType" SG_ 1178 FS_LNV_aktiv 3;
BA_ "GenSigSwitchedByIgnition" SG_ 1178 FS_LNV_aktiv 0;
BA_ "GenSigSendType" SG_ 1178 FS_LWV_aktiv 3;
BA_ "GenSigSwitchedByIgnition" SG_ 1178 FS_LWV_aktiv 0;
BA_ "GenSigSendType" SG_ 1178 FS_MMB_glob_stop 3;
BA_ "GenSigSwitchedByIgnition" SG_ 1178 FS_MMB_glob_stop 0;
BA_ "GenSigSendType" SG_ 1178 FS_MMB_lokal_Stop 3;
BA_ "GenSigSwitchedByIgnition" SG_ 1178 FS_MMB_lokal_Stop 0;
BA_ "GenSigSendType" SG_ 1178 FS_MMB_storage 3;
BA_ "GenSigSwitchedByIgnition" SG_ 1178 FS_MMB_storage 0;
BA_ "GenSigSendType" SG_ 1178 FS_MMB_storage_beep 3;
BA_ "GenSigSwitchedByIgnition" SG_ 1178 FS_MMB_storage_beep 0;
BA_ "GenSigSendType" SG_ 1178 FS_MMB_store 3;
BA_ "GenSigSwitchedByIgnition" SG_ 1178 FS_MMB_store 0;
BA_ "GenSigSendType" SG_ 1178 FS_MMB_store_LED_on 3;
BA_ "GenSigSwitchedByIgnition" SG_ 1178 FS_MMB_store_LED_on 0;
BA_ "GenSigSendType" SG_ 1178 FS_MMB_tast 3;
BA_ "GenSigSwitchedByIgnition" SG_ 1178 FS_MMB_tast 0;
BA_ "GenSigSendType" SG_ 1178 FS_MMB_tipp 3;
BA_ "GenSigSwitchedByIgnition" SG_ 1178 FS_MMB_tipp 0;
BA_ "GenSigSendType" SG_ 1178 FS_NFA_einfahren 3;
BA_ "GenSigSwitchedByIgnition" SG_ 1178 FS_NFA_einfahren 0;
BA_ "GenSigSendType" SG_ 1178 FS_SHV_aktiv 3;
BA_ "GenSigSwitchedByIgnition" SG_ 1178 FS_SHV_aktiv 0;
BA_ "GenSigSendType" SG_ 1178 FS_Sitzfahrt_aktiv 3;
BA_ "GenSigSwitchedByIgnition" SG_ 1178 FS_Sitzfahrt_aktiv 0;
BA_ "GenSigSendType" SG_ 1178 FS_SLV_aktiv 3;
BA_ "GenSigSwitchedByIgnition" SG_ 1178 FS_SLV_aktiv 0;
BA_ "GenSigSendType" SG_ 1178 FS_SNV_aktiv 3;
BA_ "GenSigSwitchedByIgnition" SG_ 1178 FS_SNV_aktiv 0;
BA_ "GenSigSendType" SG_ 1178 FS_Spezialposition_anfahren 3;
BA_ "GenSigSwitchedByIgnition" SG_ 1178 FS_Spezialposition_anfahren 0;
BA_ "GenSigSendType" SG_ 1178 FS_STV_aktiv 3;
BA_ "GenSigSwitchedByIgnition" SG_ 1178 FS_STV_aktiv 0;
BA_ "GenSigSendType" SG_ 954 FS_BFS_aufraeumen 3;
BA_ "GenSigSwitchedByIgnition" SG_ 954 FS_BFS_aufraeumen 0;
BA_ "GenSigSendType" SG_ 954 FS_BFSFo_aufraeumen 3;
BA_ "GenSigSwitchedByIgnition" SG_ 954 FS_BFSFo_aufraeumen 0;
BA_ "GenSigSendType" SG_ 954 FS_FSFo_aufraeumen 3;
BA_ "GenSigSwitchedByIgnition" SG_ 954 FS_FSFo_aufraeumen 0;
BA_ "GenSigSendType" SG_ 954 FS_MMB_Sys_Fahrt_aktiv 3;
BA_ "GenSigSwitchedByIgnition" SG_ 954 FS_MMB_Sys_Fahrt_aktiv 0;
BA_ "GenSigSendType" SG_ 954 FS_Remote_KSV_Taste_hoch 3;
BA_ "GenSigSwitchedByIgnition" SG_ 954 FS_Remote_KSV_Taste_hoch 0;
BA_ "GenSigSendType" SG_ 954 FS_Remote_KSV_Taste_tief 3;
BA_ "GenSigSwitchedByIgnition" SG_ 954 FS_Remote_KSV_Taste_tief 0;
BA_ "GenSigSendType" SG_ 954 FS_Remote_KSV_Taste_vor 3;
BA_ "GenSigSwitchedByIgnition" SG_ 954 FS_Remote_KSV_Taste_vor 0;
BA_ "GenSigSendType" SG_ 954 FS_Remote_KSV_Taste_zurueck 3;
BA_ "GenSigSwitchedByIgnition" SG_ 954 FS_Remote_KSV_Taste_zurueck 0;
BA_ "GenSigSendType" SG_ 954 FS_Remote_LKV_Taste_vor 3;
BA_ "GenSigSwitchedByIgnition" SG_ 954 FS_Remote_LKV_Taste_vor 0;
BA_ "GenSigSendType" SG_ 954 FS_Remote_LKV_Taste_zurueck 3;
BA_ "GenSigSwitchedByIgnition" SG_ 954 FS_Remote_LKV_Taste_zurueck 0;
BA_ "GenSigSendType" SG_ 954 FS_Remote_LNV_Taste_vor 3;
BA_ "GenSigSwitchedByIgnition" SG_ 954 FS_Remote_LNV_Taste_vor 0;
BA_ "GenSigSendType" SG_ 954 FS_Remote_LNV_Taste_zurueck 3;
BA_ "GenSigSwitchedByIgnition" SG_ 954 FS_Remote_LNV_Taste_zurueck 0;
BA_ "GenSigSendType" SG_ 954 FS_Remote_LWV_Taste_breit 3;
BA_ "GenSigSwitchedByIgnition" SG_ 954 FS_Remote_LWV_Taste_breit 0;
BA_ "GenSigSendType" SG_ 954 FS_Remote_LWV_Taste_eng 3;
BA_ "GenSigSwitchedByIgnition" SG_ 954 FS_Remote_LWV_Taste_eng 0;
BA_ "GenSigSendType" SG_ 954 FS_Remote_Massage_Taste 3;
BA_ "GenSigSwitchedByIgnition" SG_ 954 FS_Remote_Massage_Taste 0;
BA_ "GenSigSendType" SG_ 954 FS_Remote_Multif_Taster_hoch 3;
BA_ "GenSigSwitchedByIgnition" SG_ 954 FS_Remote_Multif_Taster_hoch 0;
BA_ "GenSigSendType" SG_ 954 FS_Remote_Multif_Taster_tief 3;
BA_ "GenSigSwitchedByIgnition" SG_ 954 FS_Remote_Multif_Taster_tief 0;
BA_ "GenSigSendType" SG_ 954 FS_Remote_Multif_Taster_vor 3;
BA_ "GenSigSwitchedByIgnition" SG_ 954 FS_Remote_Multif_Taster_vor 0;
BA_ "GenSigSendType" SG_ 954 FS_Remote_Multif_Taster_zurueck 3;
BA_ "GenSigSwitchedByIgnition" SG_ 954 FS_Remote_Multif_Taster_zurueck 0;
BA_ "GenSigSendType" SG_ 954 FS_Remote_Programmwippe_hoch 3;
BA_ "GenSigSwitchedByIgnition" SG_ 954 FS_Remote_Programmwippe_hoch 0;
BA_ "GenSigSendType" SG_ 954 FS_Remote_Programmwippe_tief 3;
BA_ "GenSigSwitchedByIgnition" SG_ 954 FS_Remote_Programmwippe_tief 0;
BA_ "GenSigSendType" SG_ 954 FS_Remote_SHV_Taste_hoch 3;
BA_ "GenSigSwitchedByIgnition" SG_ 954 FS_Remote_SHV_Taste_hoch 0;
BA_ "GenSigSendType" SG_ 954 FS_Remote_SHV_Taste_tief 3;
BA_ "GenSigSwitchedByIgnition" SG_ 954 FS_Remote_SHV_Taste_tief 0;
BA_ "GenSigSendType" SG_ 954 FS_Remote_SLV_Taste_vor 3;
BA_ "GenSigSwitchedByIgnition" SG_ 954 FS_Remote_SLV_Taste_vor 0;
BA_ "GenSigSendType" SG_ 954 FS_Remote_SLV_Taste_zurueck 3;
BA_ "GenSigSwitchedByIgnition" SG_ 954 FS_Remote_SLV_Taste_zurueck 0;
BA_ "GenSigSendType" SG_ 954 FS_Remote_SNV_Taste_hoch 3;
BA_ "GenSigSwitchedByIgnition" SG_ 954 FS_Remote_SNV_Taste_hoch 0;
BA_ "GenSigSendType" SG_ 954 FS_Remote_SNV_Taste_tief 3;
BA_ "GenSigSwitchedByIgnition" SG_ 954 FS_Remote_SNV_Taste_tief 0;
BA_ "GenSigSendType" SG_ 954 FS_Remote_STV_Taste_vor 3;
BA_ "GenSigSwitchedByIgnition" SG_ 954 FS_Remote_STV_Taste_vor 0;
BA_ "GenSigSendType" SG_ 954 FS_Remote_STV_Taste_zurueck 3;
BA_ "GenSigSwitchedByIgnition" SG_ 954 FS_Remote_STV_Taste_zurueck 0;
BA_ "GenSigSendType" SG_ 954 FS_Remote_SWV_Taste_breit 3;
BA_ "GenSigSwitchedByIgnition" SG_ 954 FS_Remote_SWV_Taste_breit 0;
BA_ "GenSigSendType" SG_ 954 FS_Remote_SWV_Taste_eng 3;
BA_ "GenSigSwitchedByIgnition" SG_ 954 FS_Remote_SWV_Taste_eng 0;
BA_ "GenSigSendType" SG_ 954 FS_RemoteTarget 3;
BA_ "GenSigSwitchedByIgnition" SG_ 954 FS_RemoteTarget 0;
BA_ "GenSigSendType" SG_ 954 Mem_FS_Lordose_hoch 3;
BA_ "GenSigSwitchedByIgnition" SG_ 954 Mem_FS_Lordose_hoch 0;
BA_ "GenSigSendType" SG_ 954 Mem_FS_Lordose_runter 3;
BA_ "GenSigSwitchedByIgnition" SG_ 954 Mem_FS_Lordose_runter 0;
BA_ "GenSigSendType" SG_ 954 Mem_FS_Lordose_vor 3;
BA_ "GenSigSwitchedByIgnition" SG_ 954 Mem_FS_Lordose_vor 0;
BA_ "GenSigSendType" SG_ 954 Mem_FS_Lordose_zurueck 3;
BA_ "GenSigSwitchedByIgnition" SG_ 954 Mem_FS_Lordose_zurueck 0;
BA_ "GenSigSendType" SG_ 954 Mem_FS_Massage_Geschw 3;
BA_ "GenSigSwitchedByIgnition" SG_ 954 Mem_FS_Massage_Geschw 0;
BA_ "GenSigSendType" SG_ 954 Mem_FS_Massage_Intensitaet 3;
BA_ "GenSigSwitchedByIgnition" SG_ 954 Mem_FS_Massage_Intensitaet 0;
BA_ "GenSigSendType" SG_ 954 Mem_FS_Massage_Programm 3;
BA_ "GenSigSwitchedByIgnition" SG_ 954 Mem_FS_Massage_Programm 0;
BA_ "GenSigSendType" SG_ 954 Mem_FS_SWangenLehne_beluef 3;
BA_ "GenSigSwitchedByIgnition" SG_ 954 Mem_FS_SWangenLehne_beluef 0;
BA_ "GenSigSendType" SG_ 954 Mem_FS_SWangenLehne_entlue 3;
BA_ "GenSigSwitchedByIgnition" SG_ 954 Mem_FS_SWangenLehne_entlue 0;
BA_ "GenSigSendType" SG_ 954 Mem_FS_SWangenSitz_beluef 3;
BA_ "GenSigSwitchedByIgnition" SG_ 954 Mem_FS_SWangenSitz_beluef 0;
BA_ "GenSigSendType" SG_ 954 Mem_FS_SWangenSitz_entlue 3;
BA_ "GenSigSwitchedByIgnition" SG_ 954 Mem_FS_SWangenSitz_entlue 0;
BA_ "GenSigSendType" SG_ 956 Mem_FSFo_Business_anfahren 3;
BA_ "GenSigSwitchedByIgnition" SG_ 956 Mem_FSFo_Business_anfahren 0;
BA_ "GenSigSendType" SG_ 956 Mem_FSFo_Lordose_hoch 3;
BA_ "GenSigSwitchedByIgnition" SG_ 956 Mem_FSFo_Lordose_hoch 0;
BA_ "GenSigSendType" SG_ 956 Mem_FSFo_Lordose_runter 3;
BA_ "GenSigSwitchedByIgnition" SG_ 956 Mem_FSFo_Lordose_runter 0;
BA_ "GenSigSendType" SG_ 956 Mem_FSFo_Lordose_vor 3;
BA_ "GenSigSwitchedByIgnition" SG_ 956 Mem_FSFo_Lordose_vor 0;
BA_ "GenSigSendType" SG_ 956 Mem_FSFo_Lordose_zurueck 3;
BA_ "GenSigSwitchedByIgnition" SG_ 956 Mem_FSFo_Lordose_zurueck 0;
BA_ "GenSigSendType" SG_ 956 Mem_FSFo_Massage_Geschw 3;
BA_ "GenSigSwitchedByIgnition" SG_ 956 Mem_FSFo_Massage_Geschw 0;
BA_ "GenSigSendType" SG_ 956 Mem_FSFo_Massage_Intens 3;
BA_ "GenSigSwitchedByIgnition" SG_ 956 Mem_FSFo_Massage_Intens 0;
BA_ "GenSigSendType" SG_ 956 Mem_FSFo_Massage_Prg 3;
BA_ "GenSigSwitchedByIgnition" SG_ 956 Mem_FSFo_Massage_Prg 0;
BA_ "GenSigSendType" SG_ 956 Mem_FSFo_MMB_glob_Stop 3;
BA_ "GenSigSwitchedByIgnition" SG_ 956 Mem_FSFo_MMB_glob_Stop 0;
BA_ "GenSigSendType" SG_ 956 Mem_FSFo_MMB_lokal_Stop 3;
BA_ "GenSigSwitchedByIgnition" SG_ 956 Mem_FSFo_MMB_lokal_Stop 0;
BA_ "GenSigSendType" SG_ 956 Mem_FSFo_MMB_storage 3;
BA_ "GenSigSwitchedByIgnition" SG_ 956 Mem_FSFo_MMB_storage 0;
BA_ "GenSigSendType" SG_ 956 Mem_FSFo_MMB_storage_beep 3;
BA_ "GenSigSwitchedByIgnition" SG_ 956 Mem_FSFo_MMB_storage_beep 0;
BA_ "GenSigSendType" SG_ 956 Mem_FSFo_MMB_store 3;
BA_ "GenSigSwitchedByIgnition" SG_ 956 Mem_FSFo_MMB_store 0;
BA_ "GenSigSendType" SG_ 956 Mem_FSFo_MMB_store_LED_on 3;
BA_ "GenSigSwitchedByIgnition" SG_ 956 Mem_FSFo_MMB_store_LED_on 0;
BA_ "GenSigSendType" SG_ 956 Mem_FSFo_MMB_tast 3;
BA_ "GenSigSwitchedByIgnition" SG_ 956 Mem_FSFo_MMB_tast 0;
BA_ "GenSigSendType" SG_ 956 Mem_FSFo_MMB_tipp 3;
BA_ "GenSigSwitchedByIgnition" SG_ 956 Mem_FSFo_MMB_tipp 0;
BA_ "GenSigSendType" SG_ 956 Mem_FSFo_Relax_anfahren 3;
BA_ "GenSigSwitchedByIgnition" SG_ 956 Mem_FSFo_Relax_anfahren 0;
BA_ "GenSigSendType" SG_ 956 Mem_FSFo_Sitzfahrt_aktiv 3;
BA_ "GenSigSwitchedByIgnition" SG_ 956 Mem_FSFo_Sitzfahrt_aktiv 0;
BA_ "GenSigSendType" SG_ 956 Mem_FSFo_Sitztiefe_vor 3;
BA_ "GenSigSwitchedByIgnition" SG_ 956 Mem_FSFo_Sitztiefe_vor 0;
BA_ "GenSigSendType" SG_ 956 Mem_FSFo_Sitztiefe_zur 3;
BA_ "GenSigSwitchedByIgnition" SG_ 956 Mem_FSFo_Sitztiefe_zur 0;
BA_ "GenSigSendType" SG_ 1180 Mem_Taster_BT_01_BZ 0;
BA_ "GenSigFuncType" SG_ 1180 Mem_Taster_BT_01_BZ 1;
BA_ "GenSigSwitchedByIgnition" SG_ 1180 Mem_Taster_BT_01_BZ 0;
BA_ "GenSigSendType" SG_ 1180 Mem_Taster_BT_01_CRC 0;
BA_ "GenSigFuncType" SG_ 1180 Mem_Taster_BT_01_CRC 2;
BA_ "GenSigActiveRepetitions" SG_ 1180 MTBT_M_Taste 6;
BA_ "GenSigSendType" SG_ 1180 MTBT_M_Taste 4;
BA_ "GenSigSwitchedByIgnition" SG_ 1180 MTBT_M_Taste 0;
BA_ "GenSigActiveRepetitions" SG_ 1180 MTBT_On_Off 6;
BA_ "GenSigSendType" SG_ 1180 MTBT_On_Off 4;
BA_ "GenSigSwitchedByIgnition" SG_ 1180 MTBT_On_Off 0;
BA_ "GenSigActiveRepetitions" SG_ 1180 MTBT_Pos1 6;
BA_ "GenSigSendType" SG_ 1180 MTBT_Pos1 4;
BA_ "GenSigSwitchedByIgnition" SG_ 1180 MTBT_Pos1 0;
BA_ "GenSigActiveRepetitions" SG_ 1180 MTBT_Pos2 6;
BA_ "GenSigSendType" SG_ 1180 MTBT_Pos2 4;
BA_ "GenSigSwitchedByIgnition" SG_ 1180 MTBT_Pos2 0;
BA_ "GenSigActiveRepetitions" SG_ 1180 MTBT_Pos3 6;
BA_ "GenSigSendType" SG_ 1180 MTBT_Pos3 4;
BA_ "GenSigSwitchedByIgnition" SG_ 1180 MTBT_Pos3 0;
BA_ "GenSigActiveRepetitions" SG_ 1180 MTBT_Pos4 6;
BA_ "GenSigSendType" SG_ 1180 MTBT_Pos4 4;
BA_ "GenSigSwitchedByIgnition" SG_ 1180 MTBT_Pos4 0;
BA_ "GenSigSendType" SG_ 1170 Mem_Taster_FT_01_BZ 0;
BA_ "GenSigFuncType" SG_ 1170 Mem_Taster_FT_01_BZ 1;
BA_ "GenSigSwitchedByIgnition" SG_ 1170 Mem_Taster_FT_01_BZ 0;
BA_ "GenSigSendType" SG_ 1170 Mem_Taster_FT_01_CRC 0;
BA_ "GenSigFuncType" SG_ 1170 Mem_Taster_FT_01_CRC 2;
BA_ "GenSigActiveRepetitions" SG_ 1170 MTFT_M_Taste 6;
BA_ "GenSigSendType" SG_ 1170 MTFT_M_Taste 4;
BA_ "GenSigSwitchedByIgnition" SG_ 1170 MTFT_M_Taste 0;
BA_ "GenSigActiveRepetitions" SG_ 1170 MTFT_On_Off 6;
BA_ "GenSigSendType" SG_ 1170 MTFT_On_Off 4;
BA_ "GenSigSwitchedByIgnition" SG_ 1170 MTFT_On_Off 0;
BA_ "GenSigActiveRepetitions" SG_ 1170 MTFT_Pos1_EE 6;
BA_ "GenSigSendType" SG_ 1170 MTFT_Pos1_EE 4;
BA_ "GenSigSwitchedByIgnition" SG_ 1170 MTFT_Pos1_EE 0;
BA_ "GenSigActiveRepetitions" SG_ 1170 MTFT_Pos2 6;
BA_ "GenSigSendType" SG_ 1170 MTFT_Pos2 4;
BA_ "GenSigSwitchedByIgnition" SG_ 1170 MTFT_Pos2 0;
BA_ "GenSigActiveRepetitions" SG_ 1170 MTFT_Pos3 6;
BA_ "GenSigSendType" SG_ 1170 MTFT_Pos3 4;
BA_ "GenSigSwitchedByIgnition" SG_ 1170 MTFT_Pos3 0;
BA_ "GenSigActiveRepetitions" SG_ 1170 MTFT_Pos4 6;
BA_ "GenSigSendType" SG_ 1170 MTFT_Pos4 4;
BA_ "GenSigSwitchedByIgnition" SG_ 1170 MTFT_Pos4 0;
BA_ "GenSigActiveRepetitions" SG_ 1170 MTFT_Verst_akt 6;
BA_ "GenSigSendType" SG_ 1170 MTFT_Verst_akt 4;
BA_ "GenSigSwitchedByIgnition" SG_ 1170 MTFT_Verst_akt 0;
BA_ "GenSigSendType" SG_ 1173 BFS_Kopfstuetzen_hoch 0;
BA_ "GenSigSwitchedByIgnition" SG_ 1173 BFS_Kopfstuetzen_hoch 0;
BA_ "GenSigSendType" SG_ 1173 BFS_Kopfstuetzen_runter 0;
BA_ "GenSigSwitchedByIgnition" SG_ 1173 BFS_Kopfstuetzen_runter 0;
BA_ "GenSigSendType" SG_ 1173 BFS_Laengsverst_vor 0;
BA_ "GenSigSwitchedByIgnition" SG_ 1173 BFS_Laengsverst_vor 0;
BA_ "GenSigSendType" SG_ 1173 BFS_Laengsverst_zurueck 0;
BA_ "GenSigSwitchedByIgnition" SG_ 1173 BFS_Laengsverst_zurueck 0;
BA_ "GenSigSendType" SG_ 1173 BFS_Lehnenkopf_vor 0;
BA_ "GenSigSwitchedByIgnition" SG_ 1173 BFS_Lehnenkopf_vor 0;
BA_ "GenSigSendType" SG_ 1173 BFS_Lehnenkopf_zurueck 0;
BA_ "GenSigSwitchedByIgnition" SG_ 1173 BFS_Lehnenkopf_zurueck 0;
BA_ "GenSigSendType" SG_ 1173 BFS_Lehnenneigung_vor 0;
BA_ "GenSigSwitchedByIgnition" SG_ 1173 BFS_Lehnenneigung_vor 0;
BA_ "GenSigSendType" SG_ 1173 BFS_Lehnenneigung_zurueck 0;
BA_ "GenSigSwitchedByIgnition" SG_ 1173 BFS_Lehnenneigung_zurueck 0;
BA_ "GenSigSendType" SG_ 1173 BFS_Sitzhoehe_hoch 0;
BA_ "GenSigSwitchedByIgnition" SG_ 1173 BFS_Sitzhoehe_hoch 0;
BA_ "GenSigSendType" SG_ 1173 BFS_Sitzhoehe_runter 0;
BA_ "GenSigSwitchedByIgnition" SG_ 1173 BFS_Sitzhoehe_runter 0;
BA_ "GenSigSendType" SG_ 1173 MTHBF_BZ 0;
BA_ "GenSigFuncType" SG_ 1173 MTHBF_BZ 1;
BA_ "GenSigSwitchedByIgnition" SG_ 1173 MTHBF_BZ 0;
BA_ "GenSigSendType" SG_ 1173 MTHBF_CRC 0;
BA_ "GenSigFuncType" SG_ 1173 MTHBF_CRC 2;
BA_ "GenSigSendType" SG_ 1173 MTHBF_ein 0;
BA_ "GenSigSwitchedByIgnition" SG_ 1173 MTHBF_ein 0;
BA_REL_ "GenSigTimeoutTime" BU_SG_REL_ BedienDisp_vo SG_ 1321 Lift_LED 2000;
BA_REL_ "GenSigTimeoutTime" BU_SG_REL_ BedienDisp_vo SG_ 1153 MMI_Gauges_active 5000;
BA_REL_ "GenSigTimeoutTime" BU_SG_REL_ BedienSG_hi SG_ 1624 LV_Standlicht_Anzeige 5000;
BA_REL_ "GenSigTimeoutTime" BU_SG_REL_ BedienSG_hi SG_ 1624 LV_Tagfahrlicht_Anzeige 5000;
BA_REL_ "GenSigTimeoutTime" BU_SG_REL_ BedienSG_hi SG_ 1624 LV_AFL_aktiv_Anzeige 5000;
BA_REL_ "GenSigTimeoutTime" BU_SG_REL_ DDA SG_ 1153 ZR_LAPP_Sondermodus_Status 5000;
BA_REL_ "GenSigTimeoutTime" BU_SG_REL_ DDA SG_ 1153 ZR_Parken_Sondermodus 5000;
BA_REL_ "GenSigTimeoutTime" BU_SG_REL_ Gateway SG_ 1153 MMI_Counter_Bedienevent 5000;
BA_REL_ "GenSigTimeoutTime" BU_SG_REL_ Gateway SG_ 1153 MMI_SDS_aktiv 5000;
BA_REL_ "GenSigTimeoutTime" BU_SG_REL_ Gateway SG_ 1153 MMI_Telefon_aktiv 5000;
BA_REL_ "GenSigTimeoutTime" BU_SG_REL_ Gateway SG_ 1153 MU_Update_Time 5000;
BA_REL_ "GenSigTimeoutTime" BU_SG_REL_ Gateway_PAG SG_ 1153 MMI_Counter_Bedienevent 5000;
BA_REL_ "GenSigTimeoutTime" BU_SG_REL_ Gateway_PAG SG_ 1153 MMI_SDS_aktiv 5000;
BA_REL_ "GenSigTimeoutTime" BU_SG_REL_ Gateway_PAG SG_ 1153 MMI_Telefon_aktiv 5000;
BA_REL_ "GenSigTimeoutTime" BU_SG_REL_ Gateway_PAG SG_ 1153 MU_Update_Time 5000;
BA_REL_ "GenSigTimeoutTime" BU_SG_REL_ GurtMikrofon SG_ 1153 MMI_Gurt_Mic_ref 5000;
BA_REL_ "GenSigTimeoutTime" BU_SG_REL_ OTA_FC SG_ 1624 LV_Abblendlicht_Anzeige 5000;
BA_REL_ "GenSigTimeoutTime" BU_SG_REL_ OTA_FC SG_ 1624 LV_Blinker_VL_aktiv 5000;
BA_REL_ "GenSigTimeoutTime" BU_SG_REL_ OTA_FC SG_ 1624 LV_Blinker_VR_aktiv 5000;
BA_REL_ "GenSigTimeoutTime" BU_SG_REL_ OTA_FC SG_ 134 LWI_Lenkradwinkel 1000;
BA_REL_ "GenSigTimeoutTime" BU_SG_REL_ OTA_FC SG_ 134 LWI_VZ_Lenkradwinkel 1000;
BA_REL_ "GenSigTimeoutTime" BU_SG_REL_ OTA_FC SG_ 134 LWI_Lenkradw_Geschw 1000;
BA_REL_ "GenSigTimeoutTime" BU_SG_REL_ ZR_High SG_ 982 BCM2_Bremsl_durch_ECD 1000;
BA_REL_ "GenSigTimeoutTime" BU_SG_REL_ ZR_High SG_ 982 LH_Aussenlicht_def 1000;
BA_REL_ "GenSigTimeoutTime" BU_SG_REL_ ZR_High SG_ 982 LH_Standlicht_H_aktiv 1000;
BA_REL_ "GenSigTimeoutTime" BU_SG_REL_ ZR_High SG_ 982 LH_Parklicht_HL_aktiv 1000;
BA_REL_ "GenSigTimeoutTime" BU_SG_REL_ ZR_High SG_ 982 LH_Parklicht_HR_aktiv 1000;
BA_REL_ "GenSigTimeoutTime" BU_SG_REL_ ZR_High SG_ 982 LH_Bremslicht_H_aktiv 1000;
BA_REL_ "GenSigTimeoutTime" BU_SG_REL_ ZR_High SG_ 982 LH_Nebelschluss_aktiv 1000;
BA_REL_ "GenSigTimeoutTime" BU_SG_REL_ ZR_High SG_ 982 LH_Rueckfahrlicht_aktiv 1000;
BA_REL_ "GenSigTimeoutTime" BU_SG_REL_ ZR_High SG_ 982 LH_Blinker_HL_akt 1000;
BA_REL_ "GenSigTimeoutTime" BU_SG_REL_ ZR_High SG_ 982 LH_Blinker_HR_akt 1000;
BA_REL_ "GenSigTimeoutTime" BU_SG_REL_ ZR_High SG_ 982 LH_Blinker_li_def 1000;
BA_REL_ "GenSigTimeoutTime" BU_SG_REL_ ZR_High SG_ 982 LH_Bremsl_li_def 1000;
BA_REL_ "GenSigTimeoutTime" BU_SG_REL_ ZR_High SG_ 982 LH_Schlusslicht_li_def 1000;
BA_REL_ "GenSigTimeoutTime" BU_SG_REL_ ZR_High SG_ 982 LH_Rueckf_li_def 1000;
BA_REL_ "GenSigTimeoutTime" BU_SG_REL_ ZR_High SG_ 982 LH_Nebel_li_def 1000;
BA_REL_ "GenSigTimeoutTime" BU_SG_REL_ ZR_High SG_ 982 LH_Schluss_Brems_Nebel_li_def 1000;
BA_REL_ "GenSigTimeoutTime" BU_SG_REL_ ZR_High SG_ 982 LH_Schluss_Brems_Nebel_re_def 1000;
BA_REL_ "GenSigTimeoutTime" BU_SG_REL_ ZR_High SG_ 982 LH_Schluss_Brems_li_def 1000;
BA_REL_ "GenSigTimeoutTime" BU_SG_REL_ ZR_High SG_ 982 LH_Schluss_Nebel_li_def 1000;
BA_REL_ "GenSigTimeoutTime" BU_SG_REL_ ZR_High SG_ 982 LH_SL_BRL_BLK_li_def 1000;
BA_REL_ "GenSigTimeoutTime" BU_SG_REL_ ZR_High SG_ 982 LH_Diag_Status_re_def 1000;
BA_REL_ "GenSigTimeoutTime" BU_SG_REL_ ZR_High SG_ 982 LH_Diag_Status_li_def 1000;
BA_REL_ "GenSigTimeoutTime" BU_SG_REL_ ZR_High SG_ 982 LH_Diag_LED_li_def 1000;
BA_REL_ "GenSigTimeoutTime" BU_SG_REL_ ZR_High SG_ 982 LH_Diag_LED_re_def 1000;
BA_REL_ "GenSigTimeoutTime" BU_SG_REL_ ZR_High SG_ 982 LH_Blinker_re_def 1000;
BA_REL_ "GenSigTimeoutTime" BU_SG_REL_ ZR_High SG_ 982 LH_Bremsl_re_def 1000;
BA_REL_ "GenSigTimeoutTime" BU_SG_REL_ ZR_High SG_ 982 LH_Schlusslicht_re_def 1000;
BA_REL_ "GenSigTimeoutTime" BU_SG_REL_ ZR_High SG_ 982 LH_Rueckf_re_def 1000;
BA_REL_ "GenSigTimeoutTime" BU_SG_REL_ ZR_High SG_ 982 LH_Nebel_re_def 1000;
BA_REL_ "GenSigTimeoutTime" BU_SG_REL_ ZR_High SG_ 982 LH_Schluss_Brems_re_def 1000;
BA_REL_ "GenSigTimeoutTime" BU_SG_REL_ ZR_High SG_ 982 LH_Schluss_Nebel_re_def 1000;
BA_REL_ "GenSigTimeoutTime" BU_SG_REL_ ZR_High SG_ 982 LH_SL_BRL_BLK_re_def 1000;
BA_REL_ "GenSigTimeoutTime" BU_SG_REL_ ZR_High SG_ 982 LH_Brems_Blk_re_def 1000;
BA_REL_ "GenSigTimeoutTime" BU_SG_REL_ ZR_High SG_ 982 LH_Kennzl_def 1000;
BA_REL_ "GenSigTimeoutTime" BU_SG_REL_ ZR_High SG_ 982 LH_3_Bremsl_def 1000;
BA_REL_ "GenSigTimeoutTime" BU_SG_REL_ ZR_High SG_ 982 LH_Nebel_mi_def 1000;
BA_REL_ "GenSigTimeoutTime" BU_SG_REL_ ZR_High SG_ 982 LH_Rueckf_mi_def 1000;
BA_REL_ "GenSigTimeoutTime" BU_SG_REL_ ZR_High SG_ 982 LH_Bremsl_li_ges_def 1000;
BA_REL_ "GenSigTimeoutTime" BU_SG_REL_ ZR_High SG_ 982 LH_Bremsl_re_ges_def 1000;
BA_REL_ "GenSigTimeoutTime" BU_SG_REL_ ZR_High SG_ 1624 LV_Standlicht_Anzeige 5000;
BA_REL_ "GenSigTimeoutTime" BU_SG_REL_ ZR_High SG_ 1624 LV_Abblendlicht_Anzeige 5000;
BA_REL_ "GenSigTimeoutTime" BU_SG_REL_ ZR_High SG_ 1624 LV_Fernlicht_Anzeige 5000;
BA_REL_ "GenSigTimeoutTime" BU_SG_REL_ ZR_High SG_ 1624 LV_Nebellicht_Anzeige 5000;
BA_REL_ "GenSigTimeoutTime" BU_SG_REL_ ZR_High SG_ 1624 LV_Nebelschlusslicht_Anzeige 5000;
BA_REL_ "GenSigTimeoutTime" BU_SG_REL_ ZR_High SG_ 1624 LV_Tagfahrlicht_Anzeige 5000;
BA_REL_ "GenSigTimeoutTime" BU_SG_REL_ ZR_High SG_ 1624 LV_AFL_aktiv_Anzeige 5000;
BA_REL_ "GenSigTimeoutTime" BU_SG_REL_ ZR_High SG_ 1624 LV_AFL_defekt 5000;
BA_REL_ "GenSigTimeoutTime" BU_SG_REL_ ZR_High SG_ 1624 LV_Blinker_li_def 5000;
BA_REL_ "GenSigTimeoutTime" BU_SG_REL_ ZR_High SG_ 1624 LV_Standlicht_li_def 5000;
BA_REL_ "GenSigTimeoutTime" BU_SG_REL_ ZR_High SG_ 1624 LV_Abblendlicht_li_def 5000;
BA_REL_ "GenSigTimeoutTime" BU_SG_REL_ ZR_High SG_ 1624 LV_Fernlicht_li_def 5000;
BA_REL_ "GenSigTimeoutTime" BU_SG_REL_ ZR_High SG_ 1624 LV_Nebellicht_li_def 5000;
BA_REL_ "GenSigTimeoutTime" BU_SG_REL_ ZR_High SG_ 1624 LV_Blk_li_Seite_def 5000;
BA_REL_ "GenSigTimeoutTime" BU_SG_REL_ ZR_High SG_ 1624 LV_Tagfahrlicht_li_def 5000;
BA_REL_ "GenSigTimeoutTime" BU_SG_REL_ ZR_High SG_ 1624 LV_FLA_aktiv_Anzeige 5000;
BA_REL_ "GenSigTimeoutTime" BU_SG_REL_ ZR_High SG_ 1624 LV_FLA_defekt 5000;
BA_REL_ "GenSigTimeoutTime" BU_SG_REL_ ZR_High SG_ 1624 LV_FLA_Sensor_blockiert 5000;
BA_REL_ "GenSigTimeoutTime" BU_SG_REL_ ZR_High SG_ 1624 LV_Blinker_re_def 5000;
BA_REL_ "GenSigTimeoutTime" BU_SG_REL_ ZR_High SG_ 1624 LV_Standlicht_re_def 5000;
BA_REL_ "GenSigTimeoutTime" BU_SG_REL_ ZR_High SG_ 1624 LV_Abblendlicht_re_def 5000;
BA_REL_ "GenSigTimeoutTime" BU_SG_REL_ ZR_High SG_ 1624 LV_Fernlicht_re_def 5000;
BA_REL_ "GenSigTimeoutTime" BU_SG_REL_ ZR_High SG_ 1624 LV_Nebellicht_re_def 5000;
BA_REL_ "GenSigTimeoutTime" BU_SG_REL_ ZR_High SG_ 1624 LV_Blk_re_Seite_def 5000;
BA_REL_ "GenSigTimeoutTime" BU_SG_REL_ ZR_High SG_ 1624 LV_Tagfahrlicht_re_def 5000;
BA_REL_ "GenSigTimeoutTime" BU_SG_REL_ ZR_High SG_ 1624 LV_Aussenlicht_def 5000;
BA_REL_ "GenSigTimeoutTime" BU_SG_REL_ ZR_High SG_ 1624 LV_Abblendlicht_TFL_li_def 5000;
BA_REL_ "GenSigTimeoutTime" BU_SG_REL_ ZR_High SG_ 1624 LV_Nebellicht_TFL_li_def 5000;
BA_REL_ "GenSigTimeoutTime" BU_SG_REL_ ZR_High SG_ 1624 LV_Standlicht_TFL_li_def 5000;
BA_REL_ "GenSigTimeoutTime" BU_SG_REL_ ZR_High SG_ 1624 LV_Abblend_Fernlicht_li_def 5000;
BA_REL_ "GenSigTimeoutTime" BU_SG_REL_ ZR_High SG_ 1624 LV_Abblendlicht_TFL_re_def 5000;
BA_REL_ "GenSigTimeoutTime" BU_SG_REL_ ZR_High SG_ 1624 LV_Nebellicht_TFL_re_def 5000;
BA_REL_ "GenSigTimeoutTime" BU_SG_REL_ ZR_High SG_ 1624 LV_Standlicht_TFL_re_def 5000;
BA_REL_ "GenSigTimeoutTime" BU_SG_REL_ ZR_High SG_ 1624 LV_Abblend_Fernlicht_re_def 5000;
BA_REL_ "GenSigTimeoutTime" BU_SG_REL_ ZR_High SG_ 1624 BCM1_Linksverkehr 5000;
BA_REL_ "GenSigTimeoutTime" BU_SG_REL_ ZR_High SG_ 1624 BCM1_Licht_Dunkelheit_aktiv 5000;
BA_REL_ "GenSigTimeoutTime" BU_SG_REL_ ZR_High SG_ 1624 LV_Blinker_VL_aktiv 5000;
BA_REL_ "GenSigTimeoutTime" BU_SG_REL_ ZR_High SG_ 1624 LV_Blinker_VR_aktiv 5000;
BA_REL_ "GenSigTimeoutTime" BU_SG_REL_ ZR_High SG_ 822 LR_HZG_Temp_Sensor 1200;
BA_REL_ "GenSigTimeoutTime" BU_SG_REL_ ZR_High SG_ 822 LR_HZG_Taster_on_off 1200;
BA_REL_ "GenSigTimeoutTime" BU_SG_REL_ ZR_High SG_ 134 LWI_Sensorstatus 1000;
BA_REL_ "GenSigTimeoutTime" BU_SG_REL_ ZR_High SG_ 134 LWI_QBit_Sub_Daten 1000;
BA_REL_ "GenSigTimeoutTime" BU_SG_REL_ ZR_High SG_ 134 LWI_MFL_Abschaltung 1000;
BA_REL_ "GenSigTimeoutTime" BU_SG_REL_ ZR_High SG_ 134 LWI_QBit_Lenkradwinkel 1000;
BA_REL_ "GenSigTimeoutTime" BU_SG_REL_ ZR_High SG_ 134 LWI_Lenkradwinkel 1000;
BA_REL_ "GenSigTimeoutTime" BU_SG_REL_ ZR_High SG_ 134 LWI_VZ_Lenkradwinkel 1000;
BA_REL_ "GenSigTimeoutTime" BU_SG_REL_ ZR_High SG_ 134 LWI_VZ_Lenkradw_Geschw 1000;
BA_REL_ "GenSigTimeoutTime" BU_SG_REL_ ZR_High SG_ 134 LWI_Lenkradw_Geschw 1000;
BA_REL_ "GenSigTimeoutTime" BU_SG_REL_ ZR_High SG_ 917 AFS_Abbiegelicht_li_Anf 1000;
BA_REL_ "GenSigTimeoutTime" BU_SG_REL_ ZR_High SG_ 917 AFS_Abbiegelicht_re_Anf 1000;
BA_REL_ "GenSigTimeoutTime" BU_SG_REL_ ZR_High SG_ 917 AFS_Abbiegelicht_Dimm_Anf 1000;
BA_REL_ "GenSigTimeoutTime" BU_SG_REL_ ZR_High SG_ 917 AFS_Verfuegbarkeit_GLW 1000;
BA_REL_ "GenSigTimeoutTime" BU_SG_REL_ ZR_High SG_ 917 AFS_Status_adaptive_LV 1000;
BA_REL_ "GenSigTimeoutTime" BU_SG_REL_ ZR_High SG_ 917 AFS_Fernlicht_li_defekt 1000;
BA_REL_ "GenSigTimeoutTime" BU_SG_REL_ ZR_High SG_ 917 AFS_Fernlicht_re_defekt 1000;
BA_REL_ "GenSigTimeoutTime" BU_SG_REL_ ZR_High SG_ 917 AFS_Fernlicht_Status 1000;
BA_REL_ "GenSigTimeoutTime" BU_SG_REL_ ZR_High SG_ 917 AFS_Lampe 1000;
BA_REL_ "GenSigTimeoutTime" BU_SG_REL_ ZR_High SG_ 917 LWR_Lampe 1000;
BA_REL_ "GenSigTimeoutTime" BU_SG_REL_ ZR_High SG_ 917 AFS_Fehlertext 1000;
BA_REL_ "GenSigTimeoutTime" BU_SG_REL_ ZR_High SG_ 917 LWR_Touristenmodus_aktiv 1000;
BA_REL_ "GenSigTimeoutTime" BU_SG_REL_ ZR_High SG_ 917 LWR_Sicherheitsposition_re 1000;
BA_REL_ "GenSigTimeoutTime" BU_SG_REL_ ZR_High SG_ 917 AFS_Allwetterlicht 1000;
BA_REL_ "GenSigTimeoutTime" BU_SG_REL_ ZR_High SG_ 917 LWR_Touristenmodus_verbaut 1000;
BA_REL_ "GenSigTimeoutTime" BU_SG_REL_ ZR_High SG_ 917 AFS_adaptive_LV_verbaut 1000;
BA_REL_ "GenSigTimeoutTime" BU_SG_REL_ ZR_High SG_ 917 LWR_Reisemodus_Texte 1000;
BA_REL_ "GenSigTimeoutTime" BU_SG_REL_ ZR_High SG_ 917 GLW_Sensor_blockiert 1000;
BA_REL_ "GenSigTimeoutTime" BU_SG_REL_ ZR_High SG_ 917 LWR_Hoehenwert_VL 1000;
BA_REL_ "GenSigTimeoutTime" BU_SG_REL_ ZR_High SG_ 917 LWR_Hoehenwert_HL 1000;
BA_REL_ "GenSigTimeoutTime" BU_SG_REL_ ZR_High SG_ 917 AFS_Ersatzlicht_Links 1000;
BA_REL_ "GenSigTimeoutTime" BU_SG_REL_ ZR_High SG_ 917 AFS_Ersatzlicht_Rechts 1000;
BA_REL_ "GenSigTimeoutTime" BU_SG_REL_ ZR_High SG_ 917 LWR_AFS_Grundeinstellung 1000;
BA_REL_ "GenSigTimeoutTime" BU_SG_REL_ ZR_High SG_ 917 LWR_AFS_Parametrisierung 1000;
BA_REL_ "GenSigTimeoutTime" BU_SG_REL_ ZR_High SG_ 917 LWR_Initialisierungslauf 1000;
BA_REL_ "GenSigTimeoutTime" BU_SG_REL_ ZR_High SG_ 917 LWR_Sicherheitsposition_li 1000;
BA_REL_ "GenSigTimeoutTime" BU_SG_REL_ ZR_High SG_ 917 LWR_Modus 1000;
BA_REL_ "GenSigTimeoutTime" BU_SG_REL_ ZR_High SG_ 1639 BFS_Fond_Bed_Ack 1000;
BA_REL_ "GenSigTimeoutTime" BU_SG_REL_ ZR_High SG_ 1639 BFS_Klapptisch_offen 1000;
BA_REL_ "GenSigTimeoutTime" BU_SG_REL_ ZR_High SG_ 1639 BFS_Gurtbringer_Sperre 1000;
BA_REL_ "GenSigTimeoutTime" BU_SG_REL_ ZR_High SG_ 1639 BFS_Sitzsym_Fahrt_aktiv 1000;
BA_REL_ "GenSigTimeoutTime" BU_SG_REL_ ZR_High SG_ 1639 BFS_Sitzfahrt_aktiv 1000;
BA_REL_ "GenSigTimeoutTime" BU_SG_REL_ ZR_High SG_ 1639 BFS_SLV_aktiv 1000;
BA_REL_ "GenSigTimeoutTime" BU_SG_REL_ ZR_High SG_ 1639 BFS_SHV_aktiv 1000;
BA_REL_ "GenSigTimeoutTime" BU_SG_REL_ ZR_High SG_ 1639 BFS_LNV_aktiv 1000;
BA_REL_ "GenSigTimeoutTime" BU_SG_REL_ ZR_High SG_ 1639 BFS_SNV_aktiv 1000;
BA_REL_ "GenSigTimeoutTime" BU_SG_REL_ ZR_High SG_ 1639 BFS_KSV_aktiv 1000;
BA_REL_ "GenSigTimeoutTime" BU_SG_REL_ ZR_High SG_ 1639 BFS_LKV_aktiv 1000;
BA_REL_ "GenSigTimeoutTime" BU_SG_REL_ ZR_High SG_ 1639 BFS_STV_aktiv 1000;
BA_REL_ "GenSigTimeoutTime" BU_SG_REL_ ZR_High SG_ 1639 BFS_LHV_aktiv 1000;
BA_REL_ "GenSigTimeoutTime" BU_SG_REL_ ZR_High SG_ 1639 BFS_LWV_aktiv 1000;
BA_REL_ "GenSigTimeoutTime" BU_SG_REL_ ZR_High SG_ 1639 BFS_GHV_aktiv 1000;
BA_REL_ "GenSigTimeoutTime" BU_SG_REL_ ZR_High SG_ 1639 BFS_KSS_Fahrt_aktiv 1000;
BA_REL_ "GenSigTimeoutTime" BU_SG_REL_ ZR_High SG_ 1639 BFS_MMB_lokal_Stop 1000;
BA_REL_ "GenSigTimeoutTime" BU_SG_REL_ ZR_High SG_ 1639 BFS_Ruhestellung_Status 1000;
BA_REL_ "GenSigTimeoutTime" BU_SG_REL_ ZR_High SG_ 1639 BFS_Seat_Locked 1000;
BA_REL_ "GenSigTimeoutTime" BU_SG_REL_ ZR_High SG_ 1639 BFS_MMB_storage 1000;
BA_REL_ "GenSigTimeoutTime" BU_SG_REL_ ZR_High SG_ 1639 BFS_MMB_tipp 1000;
BA_REL_ "GenSigTimeoutTime" BU_SG_REL_ ZR_High SG_ 1639 BFS_MMB_tast 1000;
BA_REL_ "GenSigTimeoutTime" BU_SG_REL_ ZR_High SG_ 1639 BFS_MMB_store_LED_on 1000;
BA_REL_ "GenSigTimeoutTime" BU_SG_REL_ ZR_High SG_ 1639 BFS_MMB_storage_beep 1000;
BA_REL_ "GenSigTimeoutTime" BU_SG_REL_ ZR_High SG_ 1639 BFS_MMB_store 1000;
BA_REL_ "GenSigTimeoutTime" BU_SG_REL_ ZR_High SG_ 1639 BFS_MMB_glob_stop 1000;
BA_REL_ "GenSigTimeoutTime" BU_SG_REL_ ZR_High SG_ 1639 BFS_FSV_ausgeklappt 1000;
BA_REL_ "GenSigTimeoutTime" BU_SG_REL_ ZR_High SG_ 957 Mem_BFSFo_Lordose_hoch 1000;
BA_REL_ "GenSigTimeoutTime" BU_SG_REL_ ZR_High SG_ 957 Mem_BFSFo_Lordose_runter 1000;
BA_REL_ "GenSigTimeoutTime" BU_SG_REL_ ZR_High SG_ 957 Mem_BFSFo_Lordose_vor 1000;
BA_REL_ "GenSigTimeoutTime" BU_SG_REL_ ZR_High SG_ 957 Mem_BFSFo_Lordose_zurueck 1000;
BA_REL_ "GenSigTimeoutTime" BU_SG_REL_ ZR_High SG_ 957 Mem_BFSFo_Massage_Geschw 1000;
BA_REL_ "GenSigTimeoutTime" BU_SG_REL_ ZR_High SG_ 957 Mem_BFSFo_Massage_Intens 1000;
BA_REL_ "GenSigTimeoutTime" BU_SG_REL_ ZR_High SG_ 957 Mem_BFSFo_MMB_storage 1000;
BA_REL_ "GenSigTimeoutTime" BU_SG_REL_ ZR_High SG_ 957 Mem_BFSFo_Massage_Prg 1000;
BA_REL_ "GenSigTimeoutTime" BU_SG_REL_ ZR_High SG_ 957 Mem_BFSFo_MMB_tast 1000;
BA_REL_ "GenSigTimeoutTime" BU_SG_REL_ ZR_High SG_ 957 Mem_BFSFo_MMB_tipp 1000;
BA_REL_ "GenSigTimeoutTime" BU_SG_REL_ ZR_High SG_ 957 Mem_BFSFo_MMB_glob_Stop 1000;
BA_REL_ "GenSigTimeoutTime" BU_SG_REL_ ZR_High SG_ 957 Mem_BFSFo_Sitztiefe_vor 1000;
BA_REL_ "GenSigTimeoutTime" BU_SG_REL_ ZR_High SG_ 957 Mem_BFSFo_Sitztiefe_zur 1000;
BA_REL_ "GenSigTimeoutTime" BU_SG_REL_ ZR_High SG_ 957 Mem_BFSFo_MMB_store 1000;
BA_REL_ "GenSigTimeoutTime" BU_SG_REL_ ZR_High SG_ 957 Mem_BFSFo_MMB_store_LED_on 1000;
BA_REL_ "GenSigTimeoutTime" BU_SG_REL_ ZR_High SG_ 957 Mem_BFSFo_BeifaSitzverstellung 1000;
BA_REL_ "GenSigTimeoutTime" BU_SG_REL_ ZR_High SG_ 957 Mem_BFSFo_MMB_lokal_Stop 1000;
BA_REL_ "GenSigTimeoutTime" BU_SG_REL_ ZR_High SG_ 957 Mem_BFSFo_Sitzfahrt_aktiv 1000;
BA_REL_ "GenSigTimeoutTime" BU_SG_REL_ ZR_High SG_ 957 Mem_BFSFo_BFS_Freigabe 1000;
BA_REL_ "GenSigTimeoutTime" BU_SG_REL_ ZR_High SG_ 957 Mem_BFS_Spezialpos_loeschen 1000;
BA_REL_ "GenSigTimeoutTime" BU_SG_REL_ ZR_High SG_ 957 Mem_BFSFo_RSE_zurueck 1000;
BA_REL_ "GenSigTimeoutTime" BU_SG_REL_ ZR_High SG_ 957 Mem_BFSFo_RSE_vor 1000;
BA_REL_ "GenSigTimeoutTime" BU_SG_REL_ ZR_High SG_ 957 Mem_BFSFo_Business_anfahren 1000;
BA_REL_ "GenSigTimeoutTime" BU_SG_REL_ ZR_High SG_ 957 Mem_BFSFo_Relax_anfahren 1000;
BA_REL_ "GenSigTimeoutTime" BU_SG_REL_ ZR_High SG_ 957 BFS_Kopfstuetze_vor 1000;
BA_REL_ "GenSigTimeoutTime" BU_SG_REL_ ZR_High SG_ 957 BFS_Kopfstuetze_zurueck 1000;
BA_REL_ "GenSigTimeoutTime" BU_SG_REL_ ZR_High SG_ 957 Mem_BFSFo_BFS_RSE_Freigabe 1000;
BA_REL_ "GenSigTimeoutTime" BU_SG_REL_ ZR_High SG_ 957 Mem_BFSFo_Fusstuetze_runter 1000;
BA_REL_ "GenSigTimeoutTime" BU_SG_REL_ ZR_High SG_ 957 Mem_BFSFo_Fusstuetze_hoch 1000;
BA_REL_ "GenSigTimeoutTime" BU_SG_REL_ ZR_High SG_ 1178 FS_Fond_Bed_enable 1000;
BA_REL_ "GenSigTimeoutTime" BU_SG_REL_ ZR_High SG_ 1178 FS_Lehne_nicht_verriegelt 1000;
BA_REL_ "GenSigTimeoutTime" BU_SG_REL_ ZR_High SG_ 1178 FS_Spezialposition_anfahren 1000;
BA_REL_ "GenSigTimeoutTime" BU_SG_REL_ ZR_High SG_ 1178 FS_Gurtbringer_Sperre 1000;
BA_REL_ "GenSigTimeoutTime" BU_SG_REL_ ZR_High SG_ 1178 FS_BFS_Sitzsym_Anfahrt 1000;
BA_REL_ "GenSigTimeoutTime" BU_SG_REL_ ZR_High SG_ 1178 FS_Sitzfahrt_aktiv 1000;
BA_REL_ "GenSigTimeoutTime" BU_SG_REL_ ZR_High SG_ 1178 FS_SLV_aktiv 1000;
BA_REL_ "GenSigTimeoutTime" BU_SG_REL_ ZR_High SG_ 1178 FS_SHV_aktiv 1000;
BA_REL_ "GenSigTimeoutTime" BU_SG_REL_ ZR_High SG_ 1178 FS_LNV_aktiv 1000;
BA_REL_ "GenSigTimeoutTime" BU_SG_REL_ ZR_High SG_ 1178 FS_SNV_aktiv 1000;
BA_REL_ "GenSigTimeoutTime" BU_SG_REL_ ZR_High SG_ 1178 FS_KSV_aktiv 1000;
BA_REL_ "GenSigTimeoutTime" BU_SG_REL_ ZR_High SG_ 1178 FS_LKV_aktiv 1000;
BA_REL_ "GenSigTimeoutTime" BU_SG_REL_ ZR_High SG_ 1178 FS_STV_aktiv 1000;
BA_REL_ "GenSigTimeoutTime" BU_SG_REL_ ZR_High SG_ 1178 FS_LHV_aktiv 1000;
BA_REL_ "GenSigTimeoutTime" BU_SG_REL_ ZR_High SG_ 1178 FS_LWV_aktiv 1000;
BA_REL_ "GenSigTimeoutTime" BU_SG_REL_ ZR_High SG_ 1178 FS_GHV_aktiv 1000;
BA_REL_ "GenSigTimeoutTime" BU_SG_REL_ ZR_High SG_ 1178 FS_BFS_KSS_Anfahrt 1000;
BA_REL_ "GenSigTimeoutTime" BU_SG_REL_ ZR_High SG_ 1178 FS_MMB_lokal_Stop 1000;
BA_REL_ "GenSigTimeoutTime" BU_SG_REL_ ZR_High SG_ 1178 FS_MMB_storage 1000;
BA_REL_ "GenSigTimeoutTime" BU_SG_REL_ ZR_High SG_ 1178 FS_MMB_tipp 1000;
BA_REL_ "GenSigTimeoutTime" BU_SG_REL_ ZR_High SG_ 1178 FS_MMB_tast 1000;
BA_REL_ "GenSigTimeoutTime" BU_SG_REL_ ZR_High SG_ 1178 FS_MMB_store_LED_on 1000;
BA_REL_ "GenSigTimeoutTime" BU_SG_REL_ ZR_High SG_ 1178 FS_MMB_store 1000;
BA_REL_ "GenSigTimeoutTime" BU_SG_REL_ ZR_High SG_ 1178 FS_MMB_glob_stop 1000;
BA_REL_ "GenSigTimeoutTime" BU_SG_REL_ ZR_High SG_ 1178 FS_EE_Fond_FS_enable 1000;
BA_REL_ "GenSigTimeoutTime" BU_SG_REL_ ZR_High SG_ 1178 FS_EE_Fond_BFS_enable 1000;
BA_REL_ "GenSigTimeoutTime" BU_SG_REL_ ZR_High SG_ 1178 FS_BFS_Fond_Verst_enable 1000;
BA_REL_ "GenSigTimeoutTime" BU_SG_REL_ ZR_High SG_ 1178 FS_EE_BFS_enable 1000;
BA_REL_ "GenSigTimeoutTime" BU_SG_REL_ ZR_High SG_ 954 Mem_FS_Lordose_hoch 1000;
BA_REL_ "GenSigTimeoutTime" BU_SG_REL_ ZR_High SG_ 954 Mem_FS_Lordose_runter 1000;
BA_REL_ "GenSigTimeoutTime" BU_SG_REL_ ZR_High SG_ 954 Mem_FS_Lordose_vor 1000;
BA_REL_ "GenSigTimeoutTime" BU_SG_REL_ ZR_High SG_ 954 Mem_FS_Lordose_zurueck 1000;
BA_REL_ "GenSigTimeoutTime" BU_SG_REL_ ZR_High SG_ 954 Mem_FS_Massage_Geschw 1000;
BA_REL_ "GenSigTimeoutTime" BU_SG_REL_ ZR_High SG_ 954 Mem_FS_Massage_Intensitaet 1000;
BA_REL_ "GenSigTimeoutTime" BU_SG_REL_ ZR_High SG_ 954 Mem_FS_SWangenLehne_beluef 1000;
BA_REL_ "GenSigTimeoutTime" BU_SG_REL_ ZR_High SG_ 954 Mem_FS_SWangenLehne_entlue 1000;
BA_REL_ "GenSigTimeoutTime" BU_SG_REL_ ZR_High SG_ 954 Mem_FS_SWangenSitz_beluef 1000;
BA_REL_ "GenSigTimeoutTime" BU_SG_REL_ ZR_High SG_ 954 Mem_FS_SWangenSitz_entlue 1000;
BA_REL_ "GenSigTimeoutTime" BU_SG_REL_ ZR_High SG_ 954 FS_BFS_aufraeumen 1000;
BA_REL_ "GenSigTimeoutTime" BU_SG_REL_ ZR_High SG_ 954 FS_BFSFo_aufraeumen 1000;
BA_REL_ "GenSigTimeoutTime" BU_SG_REL_ ZR_High SG_ 954 FS_FSFo_aufraeumen 1000;
BA_REL_ "GenSigTimeoutTime" BU_SG_REL_ ZR_High SG_ 954 FS_Remote_Multif_Taster_hoch 1000;
BA_REL_ "GenSigTimeoutTime" BU_SG_REL_ ZR_High SG_ 954 FS_Remote_Multif_Taster_tief 1000;
BA_REL_ "GenSigTimeoutTime" BU_SG_REL_ ZR_High SG_ 954 FS_Remote_Multif_Taster_vor 1000;
BA_REL_ "GenSigTimeoutTime" BU_SG_REL_ ZR_High SG_ 954 FS_Remote_Multif_Taster_zurueck 1000;
BA_REL_ "GenSigTimeoutTime" BU_SG_REL_ ZR_High SG_ 954 FS_Remote_Programmwippe_hoch 1000;
BA_REL_ "GenSigTimeoutTime" BU_SG_REL_ ZR_High SG_ 954 FS_Remote_Programmwippe_tief 1000;
BA_REL_ "GenSigTimeoutTime" BU_SG_REL_ ZR_High SG_ 954 FS_Remote_SHV_Taste_hoch 1000;
BA_REL_ "GenSigTimeoutTime" BU_SG_REL_ ZR_High SG_ 954 FS_Remote_SHV_Taste_tief 1000;
BA_REL_ "GenSigTimeoutTime" BU_SG_REL_ ZR_High SG_ 954 FS_Remote_SLV_Taste_vor 1000;
BA_REL_ "GenSigTimeoutTime" BU_SG_REL_ ZR_High SG_ 954 FS_Remote_SLV_Taste_zurueck 1000;
BA_REL_ "GenSigTimeoutTime" BU_SG_REL_ ZR_High SG_ 954 FS_Remote_SNV_Taste_hoch 1000;
BA_REL_ "GenSigTimeoutTime" BU_SG_REL_ ZR_High SG_ 954 FS_Remote_SNV_Taste_tief 1000;
BA_REL_ "GenSigTimeoutTime" BU_SG_REL_ ZR_High SG_ 954 FS_Remote_KSV_Taste_hoch 1000;
BA_REL_ "GenSigTimeoutTime" BU_SG_REL_ ZR_High SG_ 954 FS_Remote_KSV_Taste_tief 1000;
BA_REL_ "GenSigTimeoutTime" BU_SG_REL_ ZR_High SG_ 954 FS_Remote_LNV_Taste_vor 1000;
BA_REL_ "GenSigTimeoutTime" BU_SG_REL_ ZR_High SG_ 954 FS_Remote_LNV_Taste_zurueck 1000;
BA_REL_ "GenSigTimeoutTime" BU_SG_REL_ ZR_High SG_ 954 FS_Remote_Massage_Taste 1000;
BA_REL_ "GenSigTimeoutTime" BU_SG_REL_ ZR_High SG_ 954 FS_RemoteTarget 1000;
BA_REL_ "GenSigTimeoutTime" BU_SG_REL_ ZR_High SG_ 954 FS_Remote_KSV_Taste_vor 1000;
BA_REL_ "GenSigTimeoutTime" BU_SG_REL_ ZR_High SG_ 954 FS_Remote_KSV_Taste_zurueck 1000;
BA_REL_ "GenSigTimeoutTime" BU_SG_REL_ ZR_High SG_ 954 FS_Remote_STV_Taste_vor 1000;
BA_REL_ "GenSigTimeoutTime" BU_SG_REL_ ZR_High SG_ 954 FS_Remote_STV_Taste_zurueck 1000;
BA_REL_ "GenSigTimeoutTime" BU_SG_REL_ ZR_High SG_ 954 FS_Remote_SWV_Taste_eng 1000;
BA_REL_ "GenSigTimeoutTime" BU_SG_REL_ ZR_High SG_ 954 FS_Remote_SWV_Taste_breit 1000;
BA_REL_ "GenSigTimeoutTime" BU_SG_REL_ ZR_High SG_ 954 FS_Remote_LWV_Taste_eng 1000;
BA_REL_ "GenSigTimeoutTime" BU_SG_REL_ ZR_High SG_ 954 FS_Remote_LWV_Taste_breit 1000;
BA_REL_ "GenSigTimeoutTime" BU_SG_REL_ ZR_High SG_ 954 FS_Remote_LKV_Taste_vor 1000;
BA_REL_ "GenSigTimeoutTime" BU_SG_REL_ ZR_High SG_ 954 FS_Remote_LKV_Taste_zurueck 1000;
BA_REL_ "GenSigTimeoutTime" BU_SG_REL_ ZR_High SG_ 954 FS_MMB_Sys_Fahrt_aktiv 1000;
BA_REL_ "GenSigTimeoutTime" BU_SG_REL_ ZR_High SG_ 956 Mem_FSFo_Lordose_hoch 1000;
BA_REL_ "GenSigTimeoutTime" BU_SG_REL_ ZR_High SG_ 956 Mem_FSFo_Lordose_runter 1000;
BA_REL_ "GenSigTimeoutTime" BU_SG_REL_ ZR_High SG_ 956 Mem_FSFo_Lordose_vor 1000;
BA_REL_ "GenSigTimeoutTime" BU_SG_REL_ ZR_High SG_ 956 Mem_FSFo_Lordose_zurueck 1000;
BA_REL_ "GenSigTimeoutTime" BU_SG_REL_ ZR_High SG_ 956 Mem_FSFo_Massage_Geschw 1000;
BA_REL_ "GenSigTimeoutTime" BU_SG_REL_ ZR_High SG_ 956 Mem_FSFo_Massage_Intens 1000;
BA_REL_ "GenSigTimeoutTime" BU_SG_REL_ ZR_High SG_ 956 Mem_FSFo_MMB_storage 1000;
BA_REL_ "GenSigTimeoutTime" BU_SG_REL_ ZR_High SG_ 956 Mem_FSFo_Massage_Prg 1000;
BA_REL_ "GenSigTimeoutTime" BU_SG_REL_ ZR_High SG_ 956 Mem_FSFo_MMB_tast 1000;
BA_REL_ "GenSigTimeoutTime" BU_SG_REL_ ZR_High SG_ 956 Mem_FSFo_MMB_tipp 1000;
BA_REL_ "GenSigTimeoutTime" BU_SG_REL_ ZR_High SG_ 956 Mem_FSFo_MMB_glob_Stop 1000;
BA_REL_ "GenSigTimeoutTime" BU_SG_REL_ ZR_High SG_ 956 Mem_FSFo_Sitztiefe_vor 1000;
BA_REL_ "GenSigTimeoutTime" BU_SG_REL_ ZR_High SG_ 956 Mem_FSFo_Sitztiefe_zur 1000;
BA_REL_ "GenSigTimeoutTime" BU_SG_REL_ ZR_High SG_ 956 Mem_FSFo_MMB_store 1000;
BA_REL_ "GenSigTimeoutTime" BU_SG_REL_ ZR_High SG_ 956 Mem_FSFo_MMB_storage_beep 1000;
BA_REL_ "GenSigTimeoutTime" BU_SG_REL_ ZR_High SG_ 956 Mem_FSFo_MMB_store_LED_on 1000;
BA_REL_ "GenSigTimeoutTime" BU_SG_REL_ ZR_High SG_ 956 Mem_FSFo_MMB_lokal_Stop 1000;
BA_REL_ "GenSigTimeoutTime" BU_SG_REL_ ZR_High SG_ 956 Mem_FSFo_Sitzfahrt_aktiv 1000;
BA_REL_ "GenSigTimeoutTime" BU_SG_REL_ ZR_High SG_ 956 Mem_FSFo_Business_anfahren 1000;
BA_REL_ "GenSigTimeoutTime" BU_SG_REL_ ZR_High SG_ 956 Mem_FSFo_Relax_anfahren 1000;
BA_REL_ "GenSigTimeoutTime" BU_SG_REL_ ZR_High SG_ 1180 MTBT_Pos1 1000;
BA_REL_ "GenSigTimeoutTime" BU_SG_REL_ ZR_High SG_ 1180 MTBT_Pos2 1000;
BA_REL_ "GenSigTimeoutTime" BU_SG_REL_ ZR_High SG_ 1180 MTBT_Pos3 1000;
BA_REL_ "GenSigTimeoutTime" BU_SG_REL_ ZR_High SG_ 1180 MTBT_Pos4 1000;
BA_REL_ "GenSigTimeoutTime" BU_SG_REL_ ZR_High SG_ 1180 MTBT_On_Off 1000;
BA_REL_ "GenSigTimeoutTime" BU_SG_REL_ ZR_High SG_ 1180 MTBT_M_Taste 1000;
BA_REL_ "GenSigTimeoutTime" BU_SG_REL_ ZR_High SG_ 1170 MTFT_Pos1_EE 1000;
BA_REL_ "GenSigTimeoutTime" BU_SG_REL_ ZR_High SG_ 1170 MTFT_Pos2 1000;
BA_REL_ "GenSigTimeoutTime" BU_SG_REL_ ZR_High SG_ 1170 MTFT_Pos3 1000;
BA_REL_ "GenSigTimeoutTime" BU_SG_REL_ ZR_High SG_ 1170 MTFT_Pos4 1000;
BA_REL_ "GenSigTimeoutTime" BU_SG_REL_ ZR_High SG_ 1170 MTFT_On_Off 1000;
BA_REL_ "GenSigTimeoutTime" BU_SG_REL_ ZR_High SG_ 1170 MTFT_Verst_akt 1000;
BA_REL_ "GenSigTimeoutTime" BU_SG_REL_ ZR_High SG_ 1170 MTFT_M_Taste 1000;
BA_REL_ "GenSigTimeoutTime" BU_SG_REL_ ZR_High SG_ 1173 BFS_Sitzhoehe_hoch 1000;
BA_REL_ "GenSigTimeoutTime" BU_SG_REL_ ZR_High SG_ 1173 BFS_Sitzhoehe_runter 1000;
BA_REL_ "GenSigTimeoutTime" BU_SG_REL_ ZR_High SG_ 1173 MTHBF_ein 1000;
BA_REL_ "GenSigTimeoutTime" BU_SG_REL_ ZR_High SG_ 1173 BFS_Laengsverst_vor 1000;
BA_REL_ "GenSigTimeoutTime" BU_SG_REL_ ZR_High SG_ 1173 BFS_Laengsverst_zurueck 1000;
BA_REL_ "GenSigTimeoutTime" BU_SG_REL_ ZR_High SG_ 1173 BFS_Lehnenneigung_vor 1000;
BA_REL_ "GenSigTimeoutTime" BU_SG_REL_ ZR_High SG_ 1173 BFS_Lehnenneigung_zurueck 1000;
BA_REL_ "GenSigTimeoutTime" BU_SG_REL_ ZR_High SG_ 1173 BFS_Lehnenkopf_vor 1000;
BA_REL_ "GenSigTimeoutTime" BU_SG_REL_ ZR_High SG_ 1173 BFS_Lehnenkopf_zurueck 1000;
BA_REL_ "GenSigTimeoutTime" BU_SG_REL_ ZR_High SG_ 1173 BFS_Kopfstuetzen_hoch 1000;
BA_REL_ "GenSigTimeoutTime" BU_SG_REL_ ZR_High SG_ 1173 BFS_Kopfstuetzen_runter 1000;
BA_REL_ "GenSigTimeoutTime" BU_SG_REL_ ZR_LIMU SG_ 2527679774 LRM_General_Error 5000;
BA_REL_ "GenSigTimeoutTime" BU_SG_REL_ ZR_LIMU SG_ 2527679774 LRM_Auto_Error 5000;
BA_REL_ "GenSigTimeoutTime" BU_SG_REL_ ZR_LIMU SG_ 2527679774 LRM_Manual_Error 5000;
BA_REL_ "GenSigTimeoutTime" BU_SG_REL_ ZR_LIMU SG_ 2527679774 LRM_Glass_OC_Error 5000;
BA_REL_ "GenSigTimeoutTime" BU_SG_REL_ ZR_LIMU SG_ 2527679774 LRM_Glass_SC_Error 5000;
BA_REL_ "GenSigTimeoutTime" BU_SG_REL_ ZR_LIMU SG_ 2527679774 LRM_Glass_Rear_OC_Error 5000;
BA_REL_ "GenSigTimeoutTime" BU_SG_REL_ ZR_LIMU SG_ 2527679774 LRM_Glass_Rear_SC_Error 5000;
BA_REL_ "GenSigTimeoutTime" BU_SG_REL_ ZR_LIMU SG_ 2527679774 LRM_Level 5000;
BA_REL_ "GenSigTimeoutTime" BU_SG_REL_ ZR_LIMU SG_ 2527679774 LRM_Level_Rear 5000;
BA_REL_ "GenSigTimeoutTime" BU_SG_REL_ ZR_LIMU SG_ 2527679774 LRM_Mode 5000;
BA_REL_ "GenSigTimeoutTime" BU_SG_REL_ ZR_LIMU SG_ 134 LWI_Sensorstatus 1000;
BA_REL_ "GenSigTimeoutTime" BU_SG_REL_ ZR_LIMU SG_ 134 LWI_QBit_Lenkradwinkel 1000;
BA_REL_ "GenSigTimeoutTime" BU_SG_REL_ ZR_LIMU SG_ 134 LWI_Lenkradwinkel 1000;
BA_REL_ "GenSigTimeoutTime" BU_SG_REL_ ZR_LIMU SG_ 134 LWI_VZ_Lenkradwinkel 1000;
BA_REL_ "GenSigTimeoutTime" BU_SG_REL_ ZR_MIB_TOP_ab_Gen3 SG_ 134 LWI_Sensorstatus 1000;
BA_REL_ "GenSigTimeoutTime" BU_SG_REL_ ZR_MIB_TOP_ab_Gen3 SG_ 134 LWI_QBit_Lenkradwinkel 1000;
BA_REL_ "GenSigTimeoutTime" BU_SG_REL_ ZR_MIB_TOP_ab_Gen3 SG_ 134 LWI_Lenkradwinkel 1000;
BA_REL_ "GenSigTimeoutTime" BU_SG_REL_ ZR_MIB_TOP_ab_Gen3 SG_ 134 LWI_VZ_Lenkradwinkel 1000;
BA_REL_ "GenSigTimeoutTime" BU_SG_REL_ ZR_Standard SG_ 134 LWI_Sensorstatus 1000;
BA_REL_ "GenSigTimeoutTime" BU_SG_REL_ ZR_Standard SG_ 134 LWI_QBit_Lenkradwinkel 1000;
BA_REL_ "GenSigTimeoutTime" BU_SG_REL_ ZR_Standard SG_ 134 LWI_Lenkradwinkel 1000;
BA_REL_ "GenSigTimeoutTime" BU_SG_REL_ ZR_Standard SG_ 134 LWI_VZ_Lenkradwinkel 1000;
VAL_ 982 BCM2_Bremsl_durch_ECD 0 "Bremslicht_ist_aus" 1 "Bremslicht_durch_ECD_aktiv" ;
VAL_ 982 LH_Aussenlicht_def 0 "OK" 1 "defekt" ;
VAL_ 982 LH_Standlicht_H_aktiv 1 "Standlicht hinten aktiv" ;
VAL_ 982 LH_Parklicht_HL_aktiv 0 "nicht aktiv" 1 "Parklicht hinten links aktiv" ;
VAL_ 982 LH_Parklicht_HR_aktiv 0 "nicht aktiv" 1 "Parklicht hinten rechts aktiv" ;
VAL_ 982 LH_Bremslicht_H_aktiv 1 "Bremslicht hinten aktiv" ;
VAL_ 982 LH_Nebelschluss_aktiv 0 "nicht aktiv" 1 "aktiv" ;
VAL_ 982 LH_Rueckfahrlicht_aktiv 0 "nicht_aktiv" 1 "aktiv" ;
VAL_ 982 LH_Blinker_HL_akt 1 "Blinker hinten links aktiv" ;
VAL_ 982 LH_Blinker_HR_akt 1 "Blinker hinten rechts aktiv" ;
VAL_ 982 LH_Blinker_li_def 0 "OK" 1 "Blinker hinten links defekt" ;
VAL_ 982 LH_Bremsl_li_def 0 "OK" 1 "mindestens ein Bremslicht hinten links defekt" ;
VAL_ 982 LH_Schlusslicht_li_def 0 "OK" 1 "mindestens ein Schlusslicht hinten links defekt" ;
VAL_ 982 LH_Rueckf_li_def 0 "OK" 1 "Rückfahrlicht hinten links defekt" ;
VAL_ 982 LH_Nebel_li_def 0 "OK" 1 " Nebelschlusslicht hinten links defekt" ;
VAL_ 982 LH_Schluss_Brems_Nebel_li_def 0 "iO" 1 "defekt" ;
VAL_ 982 LH_Schluss_Brems_Nebel_re_def 0 "iO" 1 "defekt" ;
VAL_ 982 LH_Zusatzschlussl_def 0 "OK" 1 "mindestens_ein_Zusatzschlusslicht_defekt" ;
VAL_ 982 LH_Schluss_Brems_li_def 0 "OK" 1 "defekt" ;
VAL_ 982 LH_Schluss_Nebel_li_def 0 "OK" 1 "defekt" ;
VAL_ 982 LH_SL_BRL_BLK_li_def 0 "OK" 1 "defekt" ;
VAL_ 982 LH_Brems_Blk_li_def 0 "OK" 1 "defekt" ;
VAL_ 982 LH_Diag_Status_re_def 0 "OK" 1 "Aussenlict_Diagnose_Systemstoerung_rechts" ;
VAL_ 982 LH_Diag_Status_li_def 0 "OK" 1 "Aussenlicht_Diagnose_Systemstoerung_links" ;
VAL_ 982 LH_Diag_LED_li_def 0 "OK" 1 "Heckleuchte_links_defekt" ;
VAL_ 982 LH_Diag_LED_re_def 0 "OK" 1 "Heckleuchte_rechts_defekt" ;
VAL_ 982 LH_Blinker_re_def 0 "OK" 1 "Blinker hinten rechts defekt" ;
VAL_ 982 LH_Bremsl_re_def 0 "OK" 1 "mindestens ein Bremslicht hinten rechts defekt" ;
VAL_ 982 LH_Schlusslicht_re_def 0 "OK" 1 "mindestens ein Schlusslicht hinten rechts defekt" ;
VAL_ 982 LH_Rueckf_re_def 0 "OK" 1 "Rückfahrlicht hinten rechts defekt" ;
VAL_ 982 LH_Nebel_re_def 0 "OK" 1 "Nebelschlusslicht hinten rechts defekt" ;
VAL_ 982 LH_Schluss_Brems_mi_def 0 "OK" 1 "Defekt" ;
VAL_ 982 LH_Schluss_Brems_re_def 0 "OK" 1 "defekt" ;
VAL_ 982 LH_Schluss_Nebel_re_def 0 "OK" 1 "defekt" ;
VAL_ 982 LH_SL_BRL_BLK_re_def 0 "OK" 1 "defekt" ;
VAL_ 982 LH_Brems_Blk_re_def 0 "OK" 1 "defekt" ;
VAL_ 982 LH_Kennzl_def 0 "OK" 1 "Kennzeichenbeleuchtung hinten defekt" ;
VAL_ 982 LH_3_Bremsl_def 0 "OK" 1 "hochgesetzte  Bremsleuchte defekt" ;
VAL_ 982 LH_Nebel_mi_def 0 "OK" 1 " Nebelschlusslicht hinten Mitte defekt" ;
VAL_ 982 LH_Rueckf_mi_def 0 "OK" 1 "Rückfahllicht Mitte defekt" ;
VAL_ 982 LH_Schlusslicht_mi_def 0 "OK" 1 "defekt" ;
VAL_ 982 LH_Bremsl_mi_def 0 "OK" 1 "defekt" ;
VAL_ 982 LH_Bremsl_li_ges_def 0 "OK" 1 "Alle Bremslichter hinten links defekt" ;
VAL_ 982 LH_Bremsl_re_ges_def 0 "OK" 1 "Alle Bremslichter hinten rechts defekt" ;
VAL_ 1624 LV_Standlicht_Anzeige 0 "nicht aktiv" 1 "aktiv" ;
VAL_ 1624 LV_Abblendlicht_Anzeige 0 "inaktiv" 1 "aktiv" ;
VAL_ 1624 LV_Fernlicht_Anzeige 0 "nicht aktiv" 1 "aktiv" ;
VAL_ 1624 LV_Nebellicht_Anzeige 0 "nicht aktiv" 1 "aktiv" ;
VAL_ 1624 LV_Nebelschlusslicht_Anzeige 0 "nicht aktiv" 1 "aktiv" ;
VAL_ 1624 LV_Tagfahrlicht_Anzeige 0 "nicht aktiv" 1 "aktiv" ;
VAL_ 1624 LV_AFL_aktiv_Anzeige 0 "nicht aktiv" 1 "aktiv" ;
VAL_ 1624 LV_AFL_defekt 0 "OK" 1 "defekt" ;
VAL_ 1624 LV_Blinker_li_def 0 "OK" 1 "defekt" ;
VAL_ 1624 LV_Standlicht_li_def 0 "OK" 1 "defekt" ;
VAL_ 1624 LV_Abblendlicht_li_def 0 "OK" 1 "defekt" ;
VAL_ 1624 LV_Fernlicht_li_def 0 "OK" 1 "defekt" ;
VAL_ 1624 LV_Nebellicht_li_def 0 "OK" 1 "defekt" ;
VAL_ 1624 LV_Blk_li_Seite_def 0 "OK" 1 "defekt" ;
VAL_ 1624 LV_Tagfahrlicht_li_def 0 "OK" 1 "defekt" ;
VAL_ 1624 LV_FLA_aktiv_Anzeige 0 "aus" 1 "ein" ;
VAL_ 1624 LV_FLA_defekt 0 "i.O." 1 "FLA defekt" ;
VAL_ 1624 LV_FLA_Sensor_blockiert 0 "i.O." 1 "FLA-Sensor blockiert" ;
VAL_ 1624 LV_Blinker_re_def 0 "OK" 1 "defekt" ;
VAL_ 1624 LV_Standlicht_re_def 0 "OK" 1 "defekt" ;
VAL_ 1624 LV_Abblendlicht_re_def 0 "OK" 1 "defekt" ;
VAL_ 1624 LV_Fernlicht_re_def 0 "OK" 1 "defekt" ;
VAL_ 1624 LV_Nebellicht_re_def 0 "OK" 1 "defekt" ;
VAL_ 1624 LV_Blk_re_Seite_def 0 "OK" 1 "defekt" ;
VAL_ 1624 LV_Tagfahrlicht_re_def 0 "OK" 1 "defekt" ;
VAL_ 1624 LV_Aussenlicht_def 0 "OK" 1 "defekt" ;
VAL_ 1624 LV_Abblendlicht_TFL_li_def 0 "OK" 1 "defekt" ;
VAL_ 1624 LV_Nebellicht_TFL_li_def 0 "OK" 1 "defekt" ;
VAL_ 1624 LV_Standlicht_TFL_li_def 0 "OK" 1 "defekt" ;
VAL_ 1624 LV_Abblend_Fernlicht_li_def 0 "OK" 1 "defekt" ;
VAL_ 1624 LV_Abblendlicht_TFL_re_def 0 "OK" 1 "defekt" ;
VAL_ 1624 LV_Nebellicht_TFL_re_def 0 "OK" 1 "defekt" ;
VAL_ 1624 LV_Standlicht_TFL_re_def 0 "OK" 1 "defekt" ;
VAL_ 1624 LV_Abblend_Fernlicht_re_def 0 "OK" 1 "defekt" ;
VAL_ 1624 LV_Abbiegelicht_li_def 0 "OK" 1 "defekt" ;
VAL_ 1624 LV_Abbiegelicht_re_def 0 "OK" 1 "defekt" ;
VAL_ 1624 BCM1_Linksverkehr 0 "Rechtsverkehr" 1 "Linksverkehr" ;
VAL_ 1624 BCM1_Licht_Dunkelheit_aktiv 0 "inaktiv" 1 "aktiv" ;
VAL_ 1624 LV_LED_Scheinwerfer_li_def 0 "OK" 1 "defekt" ;
VAL_ 1624 LV_LED_Scheinwerfer_re_def 0 "OK" 1 "defekt" ;
VAL_ 1624 LV_Blinker_VL_aktiv 0 "inaktiv" 1 "aktiv" ;
VAL_ 1624 LV_Blinker_VR_aktiv 0 "inaktiv" 1 "aktiv" ;
VAL_ 1624 LV_MXB_Status_Anzeige 0 "MXB_aus" 1 "MXB_regelt" 2 "MXB_volles_Fernlicht" 3 "MXB_und_Laser_aktiv" ;
VAL_ 1321 Lift_Charisma_FahrPr 0 "nicht_belegt" 1 "Programm_1" 2 "Programm_2" 3 "Programm_3" 4 "Programm_4" 5 "Programm_5" 6 "Programm_6" 7 "Programm_7" ;
VAL_ 1321 Lift_Charisma_Status 0 "Init" 1 "verfuegbar" 2 "nicht_verfuegbar" 3 "asynchron_durch_Fahrerwunsch" ;
VAL_ 1321 Lift_Charisma_Umschaltung 0 "Idle" 1 "Erkennung_Umschaltaufforderung" 2 "Steuerbotschaft_nicht_definiert" 3 "Umschaltung_verzoegert" ;
VAL_ 1321 Lift_Anforderung_EFP 0 "Init" 1 "Anforderung_Tiefniveau" 2 "Anforderung_Hochniveau" ;
VAL_ 1321 Lift_ESP_Zuschaltung 0 "keine_ESP_Beeinflussung" 1 "ESP_Zwangszuschaltung_gefordert" ;
VAL_ 1321 Lift_Meldung_12 0 "inaktiv" 1 "aktiv" ;
VAL_ 1321 Lift_Meldung_13 0 "inaktiv" 1 "aktiv" ;
VAL_ 1321 Lift_Meldung_14 0 "inaktiv" 1 "aktiv" ;
VAL_ 1321 Lift_LED 0 "LED_aus" 1 "LED_ein" 2 "LED_blinken" 3 "Fehler" ;
VAL_ 1321 Lift_Position 0 "Init" 1 "Lift_in_Endlage_unten" 2 "Lift_in_Endlage_oben" 3 "Ausfuehrung_Hebevorgang" 4 "Ausfuehrung_Senkvorgang" 5 "Lift_in_zwischenstellung" ;
VAL_ 1321 Lift_Meldung_01 0 "inaktiv" 1 "aktiv" ;
VAL_ 1321 Lift_Meldung_02 0 "Init" 1 "Meldung_aktiv" ;
VAL_ 1321 Lift_Meldung_03 0 "inaktiv" 1 "aktiv" ;
VAL_ 1321 Lift_Meldung_04 0 "inaktiv" 1 "aktiv" ;
VAL_ 1321 Lift_Meldung_05 0 "inaktiv" 1 "aktiv" ;
VAL_ 1321 Lift_Meldung_06 0 "inaktiv" 1 "aktiv" ;
VAL_ 1321 Lift_Meldung_07 0 "inaktiv" 1 "aktiv" ;
VAL_ 1321 Lift_Meldung_08 0 "inaktiv" 1 "aktiv" ;
VAL_ 1321 Lift_Meldung_09 0 "inaktiv" 1 "aktiv" ;
VAL_ 1321 Lift_Meldung_10 0 "inaktiv" 1 "aktiv" ;
VAL_ 1321 Lift_Meldung_11 0 "inaktiv" 1 "aktiv" ;
VAL_ 1321 Lift_SpannungsAnf 0 "Keine_Anforderung" 1 "Anforderung_Stufe1" 2 "Anforderung_Stufe2" 3 "Anforderung_Stufe3" ;
VAL_ 1321 Lift_StartStopp_Info 0 "Motorlauf_nicht_notwendig_(Stoppfreigabe)" 1 "Motoranlauf_nicht_zwingend_notwendig_(Stoppverbot,keine_Startanforderung)" 2 "Motoranlauf_zwingend_notwendig_(Startanforderung)" 3 "Systemfehler" ;
VAL_ 822 LR_HZG_Temp_Sensor 253 "KS_Plus__Unterbrechung" 254 "Init" 255 "Tempsensor_fehlerhaft__KS_GND" ;
VAL_ 822 LR_HZG_Taster_on_off 0 "nicht_betaetigt" 1 "betaetigt" ;
VAL_ 2527679774 LRM_General_Error 0 "No_fault" 1 "Fault_present" ;
VAL_ 2527679774 LRM_Auto_Error 0 "No_fault" 1 "Auto_not_available" ;
VAL_ 2527679774 LRM_Manual_Error 0 "No_fault" 1 "Manual_not_available" ;
VAL_ 2527679774 LRM_Glass_OC_Error 0 "No_fault" 1 "Fault_present" ;
VAL_ 2527679774 LRM_Glass_SC_Error 0 "No_fault" 1 "Fault_present" ;
VAL_ 2527679774 LRM_Glass_Rear_OC_Error 0 "No_fault" 1 "Fault_present" ;
VAL_ 2527679774 LRM_Glass_Rear_SC_Error 0 "No_fault" 1 "Fault_present" ;
VAL_ 2527679774 LRM_Level 0 "Changing_level" 1 "Off" 2 "Level_1" 3 "Level_2" 4 "Clear" 6 "Init" 7 "Fehler" ;
VAL_ 2527679774 LRM_Level_Rear 0 "Changing_level" 1 "Off" 2 "Level_1" 3 "Level_2" 4 "Clear" 6 "Init" 7 "Fehler" ;
VAL_ 2527679774 LRM_Mode 0 "Changing_mode" 1 "Auto" 2 "Manual" 6 "Init" 7 "Fehler" ;
VAL_ 134 LWI_Sensorstatus 0 "iO" 1 "nicht kalibriert" ;
VAL_ 134 LWI_QBit_Sub_Daten 0 "LWS-Subinfo real (Lenkradwinkelinformation ADS-tauglich) " 1 "LWS-Subinfo simuliert (Lenkradwinkelinformation nicht ADS-tauglich )" ;
VAL_ 134 LWI_MFL_Abschaltung 0 "inaktiv" 1 "aktiv" ;
VAL_ 134 LWI_QBit_Lenkradwinkel 0 "gültiger Wert" 1 "ausserhalb der Spezifikation" ;
VAL_ 134 LWI_Lenkradwinkel 8190 "Init" 8191 "Fehler" ;
VAL_ 134 LWI_VZ_Lenkradwinkel 0 "positiv_links_von_der_Nullstellung" 1 "negativ" ;
VAL_ 134 LWI_VZ_Lenkradw_Geschw 0 "positiv_links_von_der_Nullstellung" 1 "negativ" ;
VAL_ 134 LWI_Lenkradw_Geschw 510 "Init" 511 "Fehler" ;
VAL_ 917 AFS_Abbiegelicht_li_Anf 0 "Abbiegelicht_aus" 1 "Abbiegelicht_ein" ;
VAL_ 917 AFS_Abbiegelicht_re_Anf 0 "Abbiegelicht_aus" 1 "Abbiegelicht_ein" ;
VAL_ 917 AFS_Abbiegelicht_Dimm_Anf 0 "Dimmung_angefordert" 1 "keine_Dimmung" ;
VAL_ 917 AFS_Verfuegbarkeit_GLW 0 "GLW_nicht_verfuegbar" 1 "GLW_verfuegbar" ;
VAL_ 917 AFS_Status_adaptive_LV 0 "adaptive_Lichtverteilung_aus" 1 "adaptive_Lichtverteilung_an" ;
VAL_ 917 AFS_Fernlicht_li_defekt 0 "Fernlicht_in_Ordnung" 1 "Fernlicht_defekt" ;
VAL_ 917 AFS_Fernlicht_re_defekt 0 "Fernlicht_in_Ordnung" 1 "Fernlicht_defekt" ;
VAL_ 917 AFS_Fernlicht_Status 0 "Fernlicht_aus" 1 "Fernlicht_ein" ;
VAL_ 917 AFS_Lampe 0 "Aus" 1 "Ein" ;
VAL_ 917 LWR_Lampe 0 "LWR Fehlerlampe aus" 1 "LWR Fehlerlampe ein" ;
VAL_ 917 AFS_Fehlertext 0 "kein Text" 1 "AFS ohne Funktion" ;
VAL_ 917 AFS_LED_Blinkmode 0 "kein Blinkmode angefordert" 1 "Blinkmode angefordert" ;
VAL_ 917 LWR_Touristenmodus_aktiv 0 "Touristenmodus inaktiv" 1 "Touristenmodus aktiv" ;
VAL_ 917 AFS_Charisma_FahrPr 0 "keine_Funktion" 1 "Programm_1" 2 "Programm_2" 3 "Programm_3" 4 "Programm_4" 5 "Programm_5" 6 "Programm_6" 7 "Programm_7" 8 "Programm_8" 9 "Programm_9" 10 "Programm_10" 11 "Programm_11" 12 "Programm_12" 13 "Programm_13" 14 "Programm_14" 15 "Programm_15" ;
VAL_ 917 AFS_Charisma_Status 0 "Init" 1 "verfuegbar" 2 "nicht_verfuegbar" 3 "asynchron_durch_Fahrerwunsch" ;
VAL_ 917 LWR_Sicherheitsposition_re 0 "inaktiv" 1 "aktiv" ;
VAL_ 917 AFS_Allwetterlicht 0 "Allwetterlicht_nicht_aktiv" 1 "Allwetterlicht_aktiv" ;
VAL_ 917 LWR_Touristenmodus_verbaut 0 "Touristenmodus_nicht_verbaut" 1 "Touristenmodus_verbaut" ;
VAL_ 917 AFS_adaptive_LV_verbaut 0 "adaptive_Lichtverteilung_nicht_verbaut" 1 "adaptive_Lichtverteilung_verbaut" ;
VAL_ 917 LWR_Reisemodus_Texte 0 "keine_Anzeige" 1 "Umschaltung_auf_Linksverkehr_aktiv" 2 "Umschaltung_auf_Rechtsverkehr_aktiv" ;
VAL_ 917 GLW_Sensor_blockiert 0 "Kamera_Sensor_nicht_blockiert" 1 "Kamera_Sensor_blockiert" ;
VAL_ 917 AFS_Charisma_Umschaltung 0 "Idle" 1 "Erkennung_Umschaltaufforderung" 2 "Steuerbotschaft_nicht_definiert" 3 "Umschaltung_verzoegert" ;
VAL_ 917 LWR_Pos_Schrittmotor 254 "Init" 255 "Fehler" ;
VAL_ 917 LWR_Hoehenwert_VL 254 "nicht_initialisiert" 255 "Fehler" ;
VAL_ 917 LWR_Hoehenwert_HL 254 "nicht_initialisiert" 255 "Fehler" ;
VAL_ 917 AFS_Ersatzlicht_Links 0 "keine Ersatzlichtfunktion links" 1 "Ersatzlichtfunktion links" ;
VAL_ 917 AFS_Ersatzlicht_Rechts 0 "keine Ersatzlichtfunktion rechts" 1 "Ersatzlichtfunktion rechts" ;
VAL_ 917 LWR_AFS_Grundeinstellung 0 "Grundeinstellung nicht erfolgt" 1 "Grundeinstellung erfolgt" ;
VAL_ 917 LWR_AFS_Parametrisierung 0 "Parametrisierung nicht erfolgt" 1 "Parametrisierung erfolgt" ;
VAL_ 917 LWR_Initialisierungslauf 0 "Initialisierungslauf nicht erfolgt" 1 "Initialisierungslauf erfolgt" ;
VAL_ 917 LWR_Sicherheitsposition_li 0 "inaktiv" 1 "aktiv" ;
VAL_ 917 LWR_Modus 0 "LWR statisch" 1 "LWR dynamisch" ;
VAL_ 1153 ZR_LoGeWa_Event_Kombiwarnung 0 "Init" 1 "Unfall" 2 "Traktionsverlust" 3 "Panne" 4 "Sichtbehinderung" 5 "Aquaplaning" 6 "EEBL" 7 "SEF_stat" 8 "SEF_dyn_allgemein" 9 "SEF_dyn_vorne" 10 "SEF_dyn_hinten" 11 "SEF_dyn_links" 12 "SEF_dyn_rechts" 13 "Stauende" ;
VAL_ 1153 Nav_FoD_Status 0 "Init" 1 "Nav_permanently_available" 2 "FoD_Nav_not_activated" 3 "FoD_Nav_activated" 4 "R4N_Nav_not_activated" ;
VAL_ 1153 MIB_Tongenerator_PH_verfuegbar 0 "Tongenerator_nicht_verfuegbar" 1 "Tongenerator_vorne_verfuegbar" 2 "Tongenerator_hinten_verfuegbar" 3 "Tongenerator_gesamt_verfuegbar" 4 "Tongenerator_im_AMP" ;
VAL_ 1153 DSSS_Warning 0 "No_Warning" 1 "Red_traffic_light_guidance" 2 "Stop_sign_warning" 3 "Rear_end_collision_avoidance_warning" 4 "Intersection_collision_avoidance_warning_right" 5 "Intersection_collision_avoidance_warning_left" 6 "turn_right_collision_avoidance" 7 "turn_left_collision_avoidance" 8 "pedestrian_crossing_right" 9 "pedestrian_crossing_left" 10 "bicycle_collision_right" 11 "bicycle_collision_left" ;
VAL_ 1153 ZR_Kindersicherung_RSE 0 "inaktiv" 1 "aktiv" ;
VAL_ 1153 ZR_RSE_aktivieren 0 "inaktiv" 1 "aktiv" ;
VAL_ 1153 MMI_SDS_aktiv 0 "inaktiv" 1 "aktiv" ;
VAL_ 1153 MU_SecondDisplay 0 "Init" 1 "gueltige_Karte" 2 "ungueltiges_Signal" 3 "Nicht_Verbaut" ;
VAL_ 1153 MMI_Telefon_aktiv 0 "Telefongespraech_nicht_aktiv" 1 "Telefongespraech_aktiv" ;
VAL_ 1153 MMI_Gurt_Mic_ref 0 "Downlink_inaktiv" 1 "Downlink_aktiv" ;
VAL_ 1153 ZR_Sta_Inszenierung 0 "Init" 1 "Inszenierung_deaktiviert" 2 "Inszenierung_Start" 3 "Inszenierung_Stop" ;
VAL_ 1153 MMI_Gauges_active 0 "gauges_inactive" 1 "gauges_active" ;
VAL_ 1153 ZR_MXB_Manoever_Ansage 0 "keine_Ansage" 1 "Ansage_ohne_Richtung" 2 "Ansage_rechte_Richtung" 3 "Ansage_linke_Richtung" ;
VAL_ 1153 ZR_LAPP_Sondermodus_Status 0 "keine_Anforderung" 1 "Sondermodus_aktiv" 2 "Aktivierung_nicht_moeglich" ;
VAL_ 1153 MMI_StartStopp_Info 0 "Stoppfreigabe" 1 "Stoppverbot" 2 "Startanforderung" 3 "Fehler" ;
VAL_ 1153 ZR_Parken_Sondermodus 0 "Init" 1 "Sondermodus_aktiv" 2 "Sondermodus_nicht_verfuegbar" 3 "WLAN_aus" 4 "WLAN_auscodiert" 15 "keine_WLAN_HW" ;
VAL_ 1153 ZR_Rundenbewertung 0 "Bewertung_nicht_aktiv" 1 "langsamer" 2 "gleich_schnell" 3 "schneller" 4 "reserviert" 5 "reserviert" 6 "reserviert" 7 "reserviert" 8 "reserviert" 9 "reserviert" 10 "reserviert" 11 "reserviert" 12 "reserviert" 13 "reserviert" 14 "Init" 15 "Funktion_nicht_verbaut" ;
VAL_ 1153 ZR_Rundenfortschritt 254 "Init" 255 "Funktion_nicht_verbaut" ;
VAL_ 2527679771 ZR_ECR_SwitchMode_HMI_Anf 0 "No_change" 1 "Auto" 2 "Manual" 3 "Init" 7 "Fehler" ;
VAL_ 2527679771 ZR_ECR_LevelMode_HMI_Anf 0 "No_change" 1 "Off" 2 "Level_1" 3 "Level_2" 4 "Clear" 7 "Fehler" ;
VAL_ 2527679771 ZR_Slider_soll_01 127 "Init" ;
VAL_ 2527679771 ZR_Slider_soll_02 127 "Init" ;
VAL_ 2527679771 ZR_Slider_soll_03 127 "Init" ;
VAL_ 2527679771 LIMU_Aero_Selec_HMI_Anf 0 "Init" 1 "Button_1" 2 "Button_2" 3 "Button_3" ;
VAL_ 2527679771 LIMU_BAR_Mode_Switch_HMI_Anf 0 "Not_pressed" 1 "Pressed" ;
VAL_ 2527679771 LIMU_Confirmation_HMI_Anf 0 "Not_pressed" 1 "Pressed" ;
VAL_ 2527679771 LIMU_DR_Select_HMI_Anf 0 "Init" 1 "Button_1" 2 "Button_2" 3 "Button_3" ;
VAL_ 2527679771 LIMU_Reset_switch_HMI_Anf 0 "Not_pressed" 1 "Pressed" ;
VAL_ 1639 BFS_Fond_Bed_Ack 0 "nicht aktiviert" 1 "aktiviert" ;
VAL_ 1639 BFS_Lehne_nicht_verriegelt 0 "keine Anzeige" 1 "Lehne_nicht_verriegelt" ;
VAL_ 1639 BFS_Klapptisch_offen 0 "inaktiv" 1 "aktiv" ;
VAL_ 1639 BFS_Gurtbringer_Sperre 0 "Gurtzubringer_freigegeben" 1 "Gurtzubringer_gesperrt" ;
VAL_ 1639 BFS_Sitzsym_Fahrt_aktiv 0 "inaktiv" 1 "aktiv" ;
VAL_ 1639 BFS_Sitzfahrt_aktiv 0 "Init" 1 "Sitz in Bewegung" ;
VAL_ 1639 BFS_SLV_aktiv 0 "nicht_aktiv" 1 "Sitzlaengsverstellung aktiv" ;
VAL_ 1639 BFS_SHV_aktiv 0 "nicht_aktiv" 1 "Sitzhoehenverstellung aktiv" ;
VAL_ 1639 BFS_LNV_aktiv 0 "inaktiv" 1 "aktiv" ;
VAL_ 1639 BFS_SNV_aktiv 0 "nicht_aktiv" 1 "Sitzneigungsverstellung aktiv" ;
VAL_ 1639 BFS_KSV_aktiv 0 "nicht_aktiv" 1 "Kopfstuetzenverstellung aktiv" ;
VAL_ 1639 BFS_LKV_aktiv 0 "nicht_aktiv" 1 "aktiv" ;
VAL_ 1639 BFS_STV_aktiv 0 "inaktiv" 1 "Sitztiefeverstellung aktiv" ;
VAL_ 1639 BFS_LHV_aktiv 0 "inaktiv" 1 "aktiv" ;
VAL_ 1639 BFS_LWV_aktiv 0 "nicht_aktiv" 1 "aktiv" ;
VAL_ 1639 BFS_GHV_aktiv 0 "nicht_aktiv" 1 "Gurthoehe Verstellung aktiv" ;
VAL_ 1639 BFS_KSS_Fahrt_aktiv 0 "nicht_aktiv" 1 "Komfortseitensichtfahrt aktiv" ;
VAL_ 1639 BFS_MMB_lokal_Stop 0 "kein_Abbruch" 1 "lokaler_Abbruch" ;
VAL_ 1639 BFS_Ruhestellung_Status 0 "inakiv" 1 "Ruhestellung_aktiv" ;
VAL_ 1639 BFS_Seat_Locked 0 "nicht_gesperrt" 1 "gesperrt" ;
VAL_ 1639 BFS_MMB_storage 0 "keine Zuweisung" 1 "P1/FP1 Pos Zuweisung" 2 "P2/FP2 Pos Zuweisung" 3 "P3/FP3 Pos Zuweisung" 4 "P4/FP4 Pos Zuweisung an den im System aktiven Funkschlüssel/FPI ID über MMI" 5 "FS1" 6 "FS2" 7 "FS3" 8 "FS4" ;
VAL_ 1639 BFS_MMB_tipp 0 "kein_Tippbetrieb" 1 "Tippbetrieb" ;
VAL_ 1639 BFS_MMB_tast 0 "kein_Tastbetrieb" 1 "Tastbetrieb" ;
VAL_ 1639 BFS_MMB_store_LED_on 0 "LED_aus" 1 "LED_ein" ;
VAL_ 1639 BFS_MMB_storage_beep 0 "beep_aus" 1 "beep ein" ;
VAL_ 1639 BFS_MMB_store 0 "nicht speichern" 1 "speichern" ;
VAL_ 1639 BFS_MMB_glob_stop 0 "kein globaler Abbruch" 1 "globaler Abbruch" ;
VAL_ 1639 BFS_FSV_ausgeklappt 0 "FSV_nicht_ausgeklappt" 1 "FSV_ausgeklappt" ;
VAL_ 1639 BFS_NFA_einfahren 0 "uneingeschraenkt" 1 "NFA_einfahren" ;
VAL_ 1639 BFS_Kollisionsbereich_Windschott 0 "Ausserhalb_Kollisionsbereich" 1 "Innerhalb_Kollisionsbereich" ;
VAL_ 1639 BFS_Kollisionsgefahr_Windschott 0 "keine_Kombimeldung_anzeigen" 1 "Kombimeldung_anzeigen" ;
VAL_ 957 Mem_BFSFo_Lordose_hoch 0 "Aus" 1 "Ein" ;
VAL_ 957 Mem_BFSFo_Lordose_runter 0 "Aus" 1 "Ein" ;
VAL_ 957 Mem_BFSFo_Lordose_vor 0 "Aus" 1 "Ein" ;
VAL_ 957 Mem_BFSFo_Lordose_zurueck 0 "Aus" 1 "Ein" ;
VAL_ 957 Mem_BFSFo_Massage_Geschw 0 "Aus" 1 "Stufe1" 2 "Stufe2" 3 "Stufe3" 4 "Stufe4" 5 "Stufe5" ;
VAL_ 957 Mem_BFSFo_Massage_Intens 0 "Aus" 1 "Stufe1" 2 "Stufe2" 3 "Stufe3" 4 "Stufe4" 5 "Stufe5" ;
VAL_ 957 Mem_BFSFo_MMB_storage 0 "keine_Zuweisung" 1 "P1/FP1_MemoryPos" 2 "P2/FP2_MemoryPos" 3 "P3/FP3_MemoryPos" ;
VAL_ 957 Mem_BFSFo_Massage_Prg 0 "Aus" 1 "Programm1" 2 "Programm2" 3 "Programm3" 4 "Programm4" 5 "Programm5" ;
VAL_ 957 Mem_BFSFo_MMB_tast 0 "kein_Tastbetrieb" 1 "Tastbetrieb" ;
VAL_ 957 Mem_BFSFo_MMB_tipp 0 "kein_Tippbetrieb" 1 "Tippbetrieb" ;
VAL_ 957 Mem_BFSFo_MMB_glob_Stop 0 "kein_Abbruch" 1 "Abbruch" ;
VAL_ 957 Mem_BFSFo_Sitztiefe_vor 0 "Aus" 1 "Ein" ;
VAL_ 957 Mem_BFSFo_Sitztiefe_zur 0 "Aus" 1 "Ein" ;
VAL_ 957 Mem_BFSFo_MMB_store 0 "nicht_speichern" 1 "speichern" ;
VAL_ 957 Mem_BFSFo_MMB_storage_beep 0 "Beep_aus" 1 "Beep_ein" ;
VAL_ 957 Mem_BFSFo_MMB_store_LED_on 0 "LED_aus" 1 "LED_ein" ;
VAL_ 957 Mem_BFSFo_BeifaSitzverstellung 0 "nicht_aktiv" 1 "aktiv" ;
VAL_ 957 Mem_BFSFo_MMB_lokal_Stop 0 "kein_Abbruch" 1 "lokaler_Abbruch" ;
VAL_ 957 Mem_BFSFo_Sitzfahrt_aktiv 0 "nicht_aktiv" 1 "Sitzfahrt_Aktiv" ;
VAL_ 957 Mem_BFSFo_BFS_Freigabe 0 "keine_Freigabe" 1 "Freigabe" ;
VAL_ 957 Mem_BFS_Spezialpos_loeschen 0 "Init" 1 "aktiv" ;
VAL_ 957 Mem_BFSFo_RSE_zurueck 0 "inaktiv" 1 "aktiv" ;
VAL_ 957 Mem_BFSFo_RSE_vor 0 "inaktiv" 1 "aktiv" ;
VAL_ 957 Mem_BFSFo_Business_anfahren 0 "inaktiv" 1 "Business_anfahren" ;
VAL_ 957 Mem_BFSFo_Relax_anfahren 0 "inaktiv" 1 "Relax_aktivieren" ;
VAL_ 957 BFS_Kopfstuetze_vor 0 "inaktiv" 1 "aktiv" ;
VAL_ 957 BFS_Kopfstuetze_zurueck 0 "inaktiv" 1 "aktiv" ;
VAL_ 957 Mem_BFSFo_NFA_aufgestellt 0 "aktiv" 1 "inaktiv" ;
VAL_ 957 Fernsteuerung_BFS_LED 0 "inaktiv" 1 "aktiv" ;
VAL_ 957 Mem_BFSFo_BFS_RSE_Freigabe 0 "keine_Freigabe" 1 "Freigabe" ;
VAL_ 957 Mem_BFSFo_Fusstuetze_runter 0 "inaktiv" 1 "aktiv" ;
VAL_ 957 Mem_BFSFo_Fusstuetze_hoch 0 "inaktiv" 1 "aktiv" ;
VAL_ 957 Fernsteuerung_Massage_LED 0 "inaktiv" 1 "aktiv" ;
VAL_ 1178 FS_Fond_Bed_enable 0 "disable" 1 "enable" ;
VAL_ 1178 FS_Lehne_nicht_verriegelt 0 "keine Anzeige" 1 "Lehne_nicht_verriegelt" ;
VAL_ 1178 FS_Spezialposition_anfahren 0 "Fkt_inaktiv" 1 "Fkt_aktiv" ;
VAL_ 1178 FS_Gurtbringer_Sperre 0 "Gurtzubringer_freigegeben" 1 "Gurtzubringer_gesperrt" ;
VAL_ 1178 FS_BFS_Sitzsym_Anfahrt 0 "keine Sitzsymetrie Anfahrt BFS" 1 "Sitzsymetrie Anfahrt BFS" ;
VAL_ 1178 FS_Sitzfahrt_aktiv 0 "Sitz_nicht_in_Bewegung" 1 "Sitz_in_Bewegung" ;
VAL_ 1178 FS_SLV_aktiv 0 "nicht_aktiv" 1 "Sitzlaengsverstellung aktiv" ;
VAL_ 1178 FS_SHV_aktiv 0 "nicht_aktiv" 1 "Sitzhoehenverstellung aktiv" ;
VAL_ 1178 FS_LNV_aktiv 0 "nicht_aktiv" 1 "Lehnenneigungverstellung aktiv" ;
VAL_ 1178 FS_SNV_aktiv 0 "nicht_aktiv" 1 "Sitzneigungsverstellung_aktiv" ;
VAL_ 1178 FS_KSV_aktiv 0 "nicht_aktiv" 1 "Kopfstuetzenverstellung aktiv" ;
VAL_ 1178 FS_LKV_aktiv 0 "nicht_aktiv" 1 "Lehnenkopfverstellung aktiv" ;
VAL_ 1178 FS_STV_aktiv 0 "nicht_aktiv" 1 "Sitztiefeverstellung aktiv" ;
VAL_ 1178 FS_LHV_aktiv 0 "nicht_aktiv" 1 "Lordose Höhe Verstellung aktiv" ;
VAL_ 1178 FS_LWV_aktiv 0 "nicht_aktiv" 1 "Lordose W Verstellung aktiv" ;
VAL_ 1178 FS_GHV_aktiv 0 "nicht_aktiv" 1 "Gurthoehenverstellung aktiv" ;
VAL_ 1178 FS_BFS_KSS_Anfahrt 0 "keine Anfahrt KSS BFS" 1 "Anfahrt KSS BFS" ;
VAL_ 1178 FS_MMB_lokal_Stop 0 "kein_Abbruch" 1 "lokaler_Abbruch" ;
VAL_ 1178 FS_NFA_einfahren 0 "uneingeschraenkt" 1 "NFA_einfahren" ;
VAL_ 1178 FS_Kollisionsbereich_Windschott 0 "Ausserhalb_Kollisionsbereich" 1 "Innerhalb_Kollisionsbereich" ;
VAL_ 1178 FS_MMB_storage 0 "keine_Zuweisung" 1 "P1_FP1_Pos_Zuweisung" 2 "P2_FP2_Pos_Zuweisung" 3 "P3_FP3_Pos_Zuweisung" 4 "P4_FP4_Pos_Zuweisung" 5 "FS1_bzw_Benutzerkonto_1" 6 "FS2_bzw_Benutzerkonto_2" 7 "FS3_bzw_Benutzerkonto_3" 8 "FS4_bzw_Benutzerkonto_4" 9 "FS5_bzw_Benutzerkonto_5" 10 "FS6_bzw_Benutzerkonto_6" 11 "FS7_bzw_Benutzerkonto_7" ;
VAL_ 1178 FS_MMB_tipp 0 "kein_Tippbetrieb" 1 "Tippbetrieb__automatisches_Funks" ;
VAL_ 1178 FS_MMB_tast 0 "kein_Tastbetrieb" 1 "Tastbetrieb__Fingerprintautomati" ;
VAL_ 1178 FS_MMB_store_LED_on 0 "LED_aus" 1 "LED_ein" ;
VAL_ 1178 FS_MMB_storage_beep 0 "beep aus" 1 "beep ein" ;
VAL_ 1178 FS_MMB_store 0 "nicht_speichern__kein_keyless_ve" 1 "abspeichern__keyless_verbaut" ;
VAL_ 1178 FS_MMB_glob_stop 0 "kein_globaler_Abbrucht" 1 "globaler_Abbruch" ;
VAL_ 1178 FS_EE_Fond_FS_enable 0 "EE Fond links deaktiv" 1 "EE Fond links aktiv (default) vom MMI" ;
VAL_ 1178 FS_EE_Fond_BFS_enable 0 "EE Fond rechts deaktiv" 1 "EE Fond rechts aktiv (default) vom MMI" ;
VAL_ 1178 FS_EE_BFS_enable 0 "keine_EE_Freigabe" 1 "EE_Freigabe" ;
VAL_ 1178 FS_Kollisionsgefahr_Windschott 0 "Keine_Kombimeldung_anzeigen" 1 "Kombimeldung_anzeigen" ;
VAL_ 954 Mem_FS_Lordose_hoch 0 "Aus" 1 "Ein" ;
VAL_ 954 Mem_FS_Lordose_runter 0 "Aus" 1 "Ein" ;
VAL_ 954 Mem_FS_Lordose_vor 0 "Aus" 1 "Ein" ;
VAL_ 954 Mem_FS_Lordose_zurueck 0 "Aus" 1 "Ein" ;
VAL_ 954 Mem_FS_Massage_Geschw 0 "Aus" 1 "Stufe1" 2 "Stufe2" 3 "Stufe3" 4 "Stufe4" 5 "Stufe5" ;
VAL_ 954 Mem_FS_Massage_Intensitaet 0 "Aus" 1 "Stufe1" 2 "Stufe2" 3 "Stufe3" 4 "Stufe4" 5 "Stufe5" ;
VAL_ 954 Mem_FS_SWangenLehne_beluef 0 "Aus" 1 "Ein" ;
VAL_ 954 Mem_FS_SWangenLehne_entlue 0 "Aus" 1 "Ein" ;
VAL_ 954 Mem_FS_Massage_Programm 0 "Aus" 1 "Programm1" 2 "Programm2" 3 "Programm3" 4 "Programm4" 5 "Programm5" ;
VAL_ 954 Mem_FS_SWangenSitz_beluef 0 "Aus" 1 "Ein" ;
VAL_ 954 Mem_FS_SWangenSitz_entlue 0 "Aus" 1 "Ein" ;
VAL_ 954 FS_BFS_aufraeumen 0 "unbetaetigt" 1 "betaetigt" ;
VAL_ 954 FS_BFSFo_aufraeumen 0 "unbetaetigt" 1 "betaetigt" ;
VAL_ 954 FS_FSFo_aufraeumen 0 "unbetaetigt" 1 "betaetigt" ;
VAL_ 954 FS_Remote_Multif_Taster_hoch 0 "inaktiv" 1 "aktiv" ;
VAL_ 954 FS_Remote_Multif_Taster_tief 0 "inaktiv" 1 "aktiv" ;
VAL_ 954 FS_Remote_Multif_Taster_vor 0 "inaktiv" 1 "aktiv" ;
VAL_ 954 FS_Remote_Multif_Taster_zurueck 0 "inaktiv" 1 "aktiv" ;
VAL_ 954 FS_Remote_Programmwippe_hoch 0 "inaktiv" 1 "aktiv" ;
VAL_ 954 FS_Remote_Programmwippe_tief 0 "inaktiv" 1 "aktiv" ;
VAL_ 954 FS_Remote_SHV_Taste_hoch 0 "inaktiv" 1 "aktiv" ;
VAL_ 954 FS_Remote_SHV_Taste_tief 0 "inaktiv" 1 "aktiv" ;
VAL_ 954 FS_Remote_SLV_Taste_vor 0 "inaktiv" 1 "aktiv" ;
VAL_ 954 FS_Remote_SLV_Taste_zurueck 0 "inaktiv" 1 "aktiv" ;
VAL_ 954 FS_Remote_SNV_Taste_hoch 0 "inaktiv" 1 "aktiv" ;
VAL_ 954 FS_Remote_SNV_Taste_tief 0 "inaktiv" 1 "aktiv" ;
VAL_ 954 FS_Remote_KSV_Taste_hoch 0 "inaktiv" 1 "aktiv" ;
VAL_ 954 FS_Remote_KSV_Taste_tief 0 "inaktiv" 1 "aktiv" ;
VAL_ 954 FS_Remote_LNV_Taste_vor 0 "inaktiv" 1 "aktiv" ;
VAL_ 954 FS_Remote_LNV_Taste_zurueck 0 "inaktiv" 1 "aktiv" ;
VAL_ 954 FS_Remote_Massage_Taste 0 "inaktiv" 1 "aktiv" ;
VAL_ 954 FS_RemoteTarget 0 "Init_oder_Beifahrerseite_Front" 1 "Fahrerseite_Fond" 2 "Beifahrerseite_Fond" ;
VAL_ 954 FS_Remote_KSV_Taste_vor 0 "inaktiv" 1 "aktiv" ;
VAL_ 954 FS_Remote_KSV_Taste_zurueck 0 "inaktiv" 1 "aktiv" ;
VAL_ 954 FS_Remote_STV_Taste_vor 0 "inaktiv" 1 "aktiv" ;
VAL_ 954 FS_Remote_STV_Taste_zurueck 0 "inaktiv" 1 "aktiv" ;
VAL_ 954 FS_Remote_SWV_Taste_eng 0 "inaktiv" 1 "aktiv" ;
VAL_ 954 FS_Remote_SWV_Taste_breit 0 "inaktiv" 1 "aktiv" ;
VAL_ 954 FS_Remote_LWV_Taste_eng 0 "inaktiv" 1 "aktiv" ;
VAL_ 954 FS_Remote_LWV_Taste_breit 0 "inaktiv" 1 "aktiv" ;
VAL_ 954 FS_Remote_LKV_Taste_vor 0 "inaktiv" 1 "aktiv" ;
VAL_ 954 FS_Remote_LKV_Taste_zurueck 0 "inaktiv" 1 "aktiv" ;
VAL_ 954 FS_MMB_Sys_Fahrt_aktiv 0 "inaktiv" 1 "aktiv" ;
VAL_ 956 Mem_FSFo_Lordose_hoch 0 "Aus" 1 "Ein" ;
VAL_ 956 Mem_FSFo_Lordose_runter 0 "Aus" 1 "Ein" ;
VAL_ 956 Mem_FSFo_Lordose_vor 0 "Aus" 1 "Ein" ;
VAL_ 956 Mem_FSFo_Lordose_zurueck 0 "Aus" 1 "Ein" ;
VAL_ 956 Mem_FSFo_Massage_Geschw 0 "Aus" 1 "Stufe1" 2 "Stufe2" 3 "Stufe3" 4 "Stufe4" 5 "Stufe5" ;
VAL_ 956 Mem_FSFo_Massage_Intens 0 "Aus" 1 "Stufe1" 2 "Stufe2" 3 "Stufe3" 4 "Stufe4" 5 "Stufe5" ;
VAL_ 956 Mem_FSFo_MMB_storage 0 "keine_Zuweisung" 1 "P1/FP1_MemoryPos" 2 "P2/FP2_MemoryPos" 3 "P3/FP3_MemoryPos" ;
VAL_ 956 Mem_FSFo_Massage_Prg 0 "Aus" 1 "Programm1" 2 "Programm2" 3 "Programm3" 4 "Programm4" 5 "Programm5" ;
VAL_ 956 Mem_FSFo_MMB_tast 0 "kein_Tastbetrieb" 1 "Tastbetrieb" ;
VAL_ 956 Mem_FSFo_MMB_tipp 0 "kein_Tippbetrieb" 1 "Tippbetrieb" ;
VAL_ 956 Mem_FSFo_MMB_glob_Stop 0 "kein_Abbruch" 1 "Abbruch" ;
VAL_ 956 Mem_FSFo_Sitztiefe_vor 0 "Aus" 1 "Ein" ;
VAL_ 956 Mem_FSFo_Sitztiefe_zur 0 "Aus" 1 "Ein" ;
VAL_ 956 Mem_FSFo_MMB_store 0 "nicht_speichern" 1 "speichern" ;
VAL_ 956 Mem_FSFo_MMB_storage_beep 0 "Beep_aus" 1 "Beep_ein" ;
VAL_ 956 Mem_FSFo_MMB_store_LED_on 0 "LED_aus" 1 "LED_ein" ;
VAL_ 956 Mem_FSFo_MMB_lokal_Stop 0 "kein_Abbruch" 1 "lokaler_Abbruch" ;
VAL_ 956 Mem_FSFo_Sitzfahrt_aktiv 0 "nicht_aktiv" 1 "Sitzfahrt_Aktiv" ;
VAL_ 956 Mem_FSFo_Business_anfahren 0 "inaktiv" 1 "Business_anfahren" ;
VAL_ 956 Mem_FSFo_Relax_anfahren 0 "inaktiv" 1 "Relax_aktivieren" ;
VAL_ 1180 MTBT_Pos1 0 "Taste_nicht_gedrueckt" 1 "Postionstaste_1_BT_gedrueckt" ;
VAL_ 1180 MTBT_Pos2 0 "Taste_nicht_gedrueckt" 1 "Postionstaste_2_BT_gedrueckt" ;
VAL_ 1180 MTBT_Pos3 0 "Taste_nicht_gedrueckt" 1 "Postionstaste_3_BT_gedrueckt" ;
VAL_ 1180 MTBT_Pos4 0 "Taste_nicht_gedrueckt" 1 "Postionstaste_4_BT_gedrueckt" ;
VAL_ 1180 MTBT_On_Off 0 "Taste_nicht_gedrueckt" 1 "OnOff_Taste_BT_gedrueckt" ;
VAL_ 1180 MTBT_M_Taste 0 "Taste_nicht_gedrueckt" 1 "MTaste_BT_gedrueckt" ;
VAL_ 1170 MTFT_Pos1_EE 0 "Taste_nicht_gedrueckt" 1 "Postionstaste_1_FT_gedrueckt" ;
VAL_ 1170 MTFT_Pos2 0 "Taste_nicht_gedrueckt" 1 "Postionstaste_2_FT_gedrueckt" ;
VAL_ 1170 MTFT_Pos3 0 "Taste_nicht_gedrueckt" 1 "Postionstaste_3_FT_gedrueckt" ;
VAL_ 1170 MTFT_Pos4 0 "Taste_nicht_gedrueckt" 1 "Postionstaste_4_FT_gedrueckt" ;
VAL_ 1170 MTFT_On_Off 0 "Taste_nicht_gedrueckt" 1 "On-Off Taste FT gedrückt" ;
VAL_ 1170 MTFT_Verst_akt 0 "Verstellung_nicht_aktiv" 1 "Verstellung_aktiv" ;
VAL_ 1170 MTFT_M_Taste 0 "Taste_nicht_gedrueckt" 1 "MTaste_FT_gedrueckt" ;
VAL_ 1173 BFS_Sitzhoehe_hoch 0 "aus" 1 "hoch" ;
VAL_ 1173 BFS_Sitzhoehe_runter 0 "aus" 1 "runter" ;
VAL_ 1173 MTHBF_ein 0 "aus" 1 "ein" ;
VAL_ 1173 BFS_Laengsverst_vor 0 "Taste_nicht_gedrueckt" 1 "Laengsverstellung_vor" ;
VAL_ 1173 BFS_Laengsverst_zurueck 0 "Taste_nicht_gedrueckt" 1 "Längsverstellung zurück (Wird bei Rechtslenker vom TSG HL gesendet)" ;
VAL_ 1173 BFS_Lehnenneigung_vor 0 "Taste_nicht_gedrueckt" 1 "Lehnenneigung vor (Wird bei Rechtslenker vom TSG HL gesendet)" ;
VAL_ 1173 BFS_Lehnenneigung_zurueck 0 "Taste_nicht_gedrueckt" 1 "Lehnenneigung_zurueck" ;
VAL_ 1173 BFS_Lehnenkopf_vor 0 "Taste_nicht_gedrueckt" 1 "Lehnenkopf_vor" ;
VAL_ 1173 BFS_Lehnenkopf_zurueck 0 "Taste_nicht_gedrueckt" 1 "Lehnenkopf_zurueck" ;
VAL_ 1173 BFS_Kopfstuetzen_hoch 0 "Taste_nicht_gedrueckt" 1 "Kopfstuetzen_hoch" ;
VAL_ 1173 BFS_Kopfstuetzen_runter 0 "Taste_nicht_gedrueckt" 1 "Kopfstuetzen_runter" ;
